VERSION "created by canmatrix"

NS_ :

BS_:

BU_: RadarFrontCenter VideoFrontCenter RadarFrontLeft RadarFrontRight ReceiveECU

BO_ 3221225472 VECTOR__INDEPENDENT_SIG_MSG: 0 Vector__XXX
 SG_ RFC_Status_CRC : 0|8@1+ (1,0) [0|255] "" Vector__XXX
 SG_ RFC_Status_AliveCtr : 0|4@1+ (1,0) [0|15] "" Vector__XXX
 SG_ RFC_Status_ModulationStatus : 0|2@1+ (1,0) [0|3] "" Vector__XXX
 SG_ RFC_Status_SensorStatus : 0|8@1+ (1,0) [0|255] "" Vector__XXX

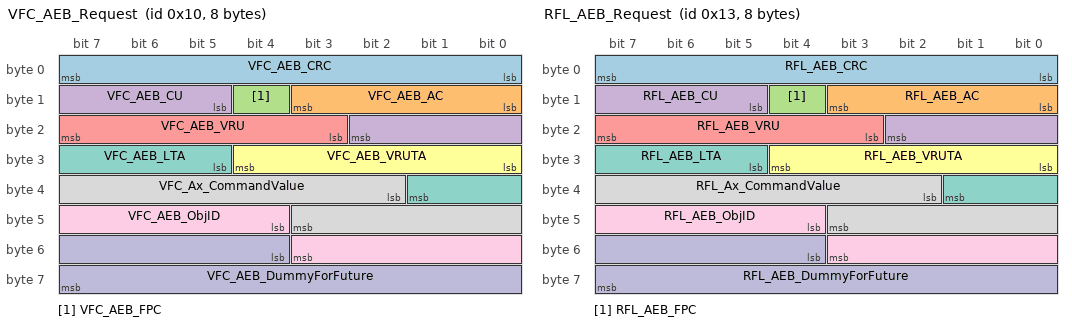
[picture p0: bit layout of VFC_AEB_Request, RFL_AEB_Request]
BO_ 16 VFC_AEB_Request: 8 VideoFrontCenter
 SG_ VFC_AEB_CRC : 0|8@1+ (1,0) [0|255] ""  RadarFrontCenter
 SG_ VFC_AEB_AC : 8|4@1+ (1,0) [0|15] ""  RadarFrontCenter
 SG_ VFC_AEB_FPC : 12|1@1+ (1,0) [0|1] ""  RadarFrontCenter
 SG_ VFC_AEB_CU : 13|6@1+ (1,0) [0|63] ""  RadarFrontCenter
 SG_ VFC_AEB_VRU : 19|5@1+ (1,0) [0|31] ""  RadarFrontCenter
 SG_ VFC_AEB_VRUTA : 24|5@1+ (1,0) [0|31] ""  RadarFrontCenter
 SG_ VFC_AEB_LTA : 29|5@1+ (1,0) [0|31] ""  RadarFrontCenter
 SG_ VFC_Ax_CommandValue : 34|10@1+ (0.024,-20.016) [-20.016|4.536] "m/s^2"  RadarFrontCenter
 SG_ VFC_AEB_ObjID : 44|8@1+ (1,0) [0|255] ""  RadarFrontCenter
 SG_ VFC_AEB_DummyForFuture : 52|12@1+ (1,0) [0|4095] ""  RadarFrontCenter

BO_ 19 RFL_AEB_Request: 8 RadarFrontLeft
 SG_ RFL_AEB_CRC : 0|8@1+ (1,0) [0|255] ""  RadarFrontCenter
 SG_ RFL_AEB_AC : 8|4@1+ (1,0) [0|15] ""  RadarFrontCenter
 SG_ RFL_AEB_FPC : 12|1@1+ (1,0) [0|1] ""  RadarFrontCenter
 SG_ RFL_AEB_CU : 13|6@1+ (1,0) [0|63] ""  RadarFrontCenter
 SG_ RFL_AEB_VRU : 19|5@1+ (1,0) [0|31] ""  RadarFrontCenter
 SG_ RFL_AEB_VRUTA : 24|5@1+ (1,0) [0|31] ""  RadarFrontCenter
 SG_ RFL_AEB_LTA : 29|5@1+ (1,0) [0|31] ""  RadarFrontCenter
 SG_ RFL_Ax_CommandValue : 34|10@1+ (0.024,-20.016) [-20.016|4.536] "m/s^2"  RadarFrontCenter
 SG_ RFL_AEB_ObjID : 44|8@1+ (1,0) [0|255] ""  RadarFrontCenter
 SG_ RFL_AEB_DummyForFuture : 52|12@1+ (1,0) [0|4095] ""  RadarFrontCenter

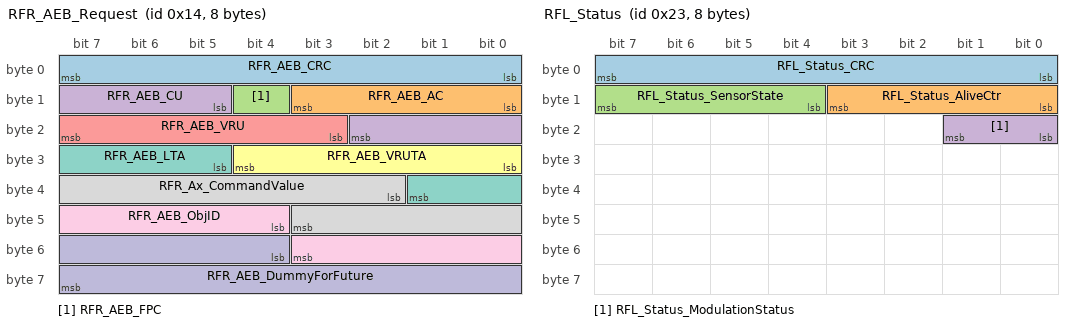
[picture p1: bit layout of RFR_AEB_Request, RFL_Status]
BO_ 20 RFR_AEB_Request: 8 RadarFrontRight
 SG_ RFR_AEB_CRC : 0|8@1+ (1,0) [0|255] ""  RadarFrontCenter
 SG_ RFR_AEB_AC : 8|4@1+ (1,0) [0|15] ""  RadarFrontCenter
 SG_ RFR_AEB_FPC : 12|1@1+ (1,0) [0|1] ""  RadarFrontCenter
 SG_ RFR_AEB_CU : 13|6@1+ (1,0) [0|63] ""  RadarFrontCenter
 SG_ RFR_AEB_VRU : 19|5@1+ (1,0) [0|31] ""  RadarFrontCenter
 SG_ RFR_AEB_VRUTA : 24|5@1+ (1,0) [0|31] ""  RadarFrontCenter
 SG_ RFR_AEB_LTA : 29|5@1+ (1,0) [0|31] ""  RadarFrontCenter
 SG_ RFR_Ax_CommandValue : 34|10@1+ (0.024,-20.016) [-20.016|4.536] "m/s^2"  RadarFrontCenter
 SG_ RFR_AEB_ObjID : 44|8@1+ (1,0) [0|255] ""  RadarFrontCenter
 SG_ RFR_AEB_DummyForFuture : 52|12@1+ (1,0) [0|4095] ""  RadarFrontCenter

BO_ 32 VFC_GlobalHdr: 32 VideoFrontCenter
 SG_ VFC_GlobalHdr_CRC : 0|16@1+ (1,0) [0|65535] ""  RadarFrontCenter,RadarFrontLeft,RadarFrontRight
 SG_ VFC_GlobalHdr_AliveCtr : 16|8@1+ (1,0) [0|255] ""  RadarFrontCenter,RadarFrontLeft,RadarFrontRight
 SG_ VFC_GlobalHdr_ProtocolVersion : 32|16@1+ (1,0) [0|65535] ""  RadarFrontCenter,RadarFrontLeft,RadarFrontRight
 SG_ VFC_GlobalHdr_TrafficFlowType : 48|1@1+ (1,0) [0|1] ""  RadarFrontCenter,RadarFrontLeft,RadarFrontRight
 SG_ VFC_GlobalHdr_TimeStampStatus : 56|8@1+ (1,0) [0|255] ""  RadarFrontCenter,RadarFrontLeft,RadarFrontRight
 SG_ VFC_GlobalHdr_TimeStamp : 64|26@1+ (1,0) [0|67108863] "ms"  RadarFrontCenter,RadarFrontLeft,RadarFrontRight
 SG_ VFC_GlobalHdr_SensorState : 96|4@1+ (1,0) [0|15] ""  RadarFrontCenter,RadarFrontLeft,RadarFrontRight
 SG_ VFC_GlobalHdr_DsmState : 100|4@1+ (1,0) [0|15] ""  RadarFrontCenter,RadarFrontLeft,RadarFrontRight
 SG_ VFC_GlobalHdr_CalibState : 104|3@1+ (1,0) [0|7] ""  RadarFrontCenter,RadarFrontLeft,RadarFrontRight
 SG_ VFC_GlobalHdr_StmState : 107|3@1+ (1,0) [0|7] ""  RadarFrontCenter,RadarFrontLeft,RadarFrontRight
 SG_ VFC_GlobalHdr_RollerBenchState : 110|2@1+ (1,0) [0|3] ""  RadarFrontCenter,RadarFrontLeft,RadarFrontRight
 SG_ VFC_GlobalHdr_MountPosX : 112|13@1+ (0.001,-4.096) [-4.096|4.095] "m"  RadarFrontCenter,RadarFrontLeft,RadarFrontRight
 SG_ VFC_GlobalHdr_MountPosY : 125|12@1+ (0.001,-2.048) [-2.048|2.047] "m"  RadarFrontCenter,RadarFrontLeft,RadarFrontRight
 SG_ VFC_GlobalHdr_MountPosZ : 137|13@1+ (0.001,0) [0|5] "m"  RadarFrontCenter,RadarFrontLeft,RadarFrontRight
 SG_ VFC_GlobalHdr_CalibYawAngle : 150|10@1+ (0.0005,-0.256) [-0.256|0.2555] "rad"  RadarFrontCenter,RadarFrontLeft,RadarFrontRight
 SG_ VFC_GlobalHdr_CalibPitchAngle : 160|10@1+ (0.0005,-0.256) [-0.256|0.2555] "rad"  RadarFrontCenter,RadarFrontLeft,RadarFrontRight
 SG_ VFC_GlobalHdr_CalibRollAngle : 170|10@1+ (0.0005,-0.256) [-0.256|0.2555] "rad"  RadarFrontCenter,RadarFrontLeft,RadarFrontRight
 SG_ VFC_GlobalHdr_SwVersion : 180|20@1+ (0.01,0) [0|9999.99] ""  RadarFrontCenter,RadarFrontLeft,RadarFrontRight
 SG_ VFC_GlobalHdr_FrameNumber : 200|16@1+ (1,0) [0|65535] ""  RadarFrontCenter,RadarFrontLeft,RadarFrontRight

BO_ 35 RFL_Status: 8 RadarFrontLeft
 SG_ RFL_Status_CRC : 0|8@1+ (1,0) [0|255] ""  RadarFrontCenter,VideoFrontCenter,RadarFrontRight
 SG_ RFL_Status_AliveCtr : 8|4@1+ (1,0) [0|15] ""  RadarFrontCenter,VideoFrontCenter,RadarFrontRight
 SG_ RFL_Status_SensorState : 12|4@1+ (1,0) [0|15] ""  RadarFrontCenter,VideoFrontCenter,RadarFrontRight
 SG_ RFL_Status_ModulationStatus : 16|2@1+ (1,0) [0|3] ""  RadarFrontCenter,VideoFrontCenter,RadarFrontRight

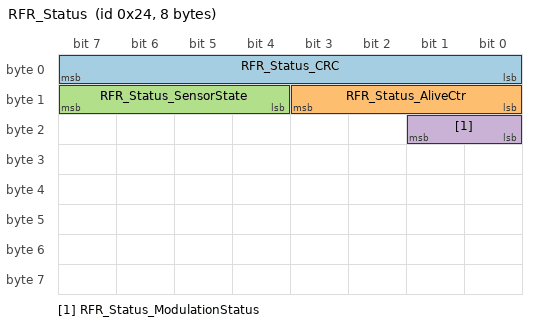
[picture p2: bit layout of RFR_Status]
BO_ 36 RFR_Status: 8 RadarFrontRight
 SG_ RFR_Status_CRC : 0|8@1+ (1,0) [0|255] ""  RadarFrontCenter,VideoFrontCenter,RadarFrontLeft
 SG_ RFR_Status_AliveCtr : 8|4@1+ (1,0) [0|15] ""  RadarFrontCenter,VideoFrontCenter,RadarFrontLeft
 SG_ RFR_Status_SensorState : 12|4@1+ (1,0) [0|15] ""  RadarFrontCenter,VideoFrontCenter,RadarFrontLeft
 SG_ RFR_Status_ModulationStatus : 16|2@1+ (1,0) [0|3] ""  RadarFrontCenter,VideoFrontCenter,RadarFrontLeft

BO_ 52 VFC_ObjectHdr: 32 VideoFrontCenter
 SG_ VFC_ObjHdr_CRC : 0|16@1+ (1,0) [0|65535] ""  RadarFrontCenter
 SG_ VFC_ObjHdr_AliveCtr : 16|8@1+ (1,0) [0|255] ""  RadarFrontCenter
 SG_ VFC_ObjHdr_ProtBlockCtr : 24|4@1+ (1,0) [0|15] ""  RadarFrontCenter
 SG_ VFC_ObjHdr_ProtObjCount : 28|6@1+ (1,0) [0|32] ""  RadarFrontCenter
 SG_ VFC_ObjHdr_State : 34|3@1+ (1,0) [0|7] ""  RadarFrontCenter
 SG_ VFC_ObjHdr_TimeStampStatus : 37|8@1+ (1,0) [0|255] ""  RadarFrontCenter
 SG_ VFC_ObjHdr_TimeStamp : 45|26@1+ (1,0) [0|67108863] "ms"  RadarFrontCenter
 SG_ VFC_ObjHdr_Principal_Point_U : 72|11@1+ (1,0) [0|2047] ""  RadarFrontCenter
 SG_ VFC_ObjHdr_Principal_Point_V : 88|10@1+ (1,0) [0|1023] ""  RadarFrontCenter
 SG_ VFC_ObjHdr_Focal_Length_X : 104|8@1+ (1,1572) [1572|1827] ""  RadarFrontCenter
 SG_ VFC_ObjHdr_Focal_Length_Y : 112|8@1+ (1,1572) [1572|1827] ""  RadarFrontCenter

BO_ 54 VFC_Object00A: 64 VideoFrontCenter
 SG_ VFC_Obj00A_CRC : 0|16@1+ (1,0) [0|65535] ""  RadarFrontCenter
 SG_ VFC_Obj00A_AliveCtr : 16|8@1+ (1,0) [0|255] ""  RadarFrontCenter
 SG_ VFC_Obj00A_ProtBlockCtr : 24|4@1+ (1,0) [0|15] ""  RadarFrontCenter
 SG_ VFC_Obj00A_ID : 32|8@1+ (1,0) [1|255] ""  RadarFrontCenter
 SG_ VFC_Obj00A_AxStdDev : 40|8@1+ (0.1,0) [0|25.5] "m/s^2"  RadarFrontCenter
 SG_ VFC_Obj00A_Dx : 48|12@1+ (0.05,0) [0|204.75] "m"  RadarFrontCenter
 SG_ VFC_Obj00A_Type : 60|4@1+ (1,0) [0|15] ""  RadarFrontCenter
 SG_ VFC_Obj00A_Dy : 64|14@1+ (0.01,-80) [-80|80] "m"  RadarFrontCenter
 SG_ VFC_Obj00A_Measured : 78|2@1+ (1,0) [0|3] ""  RadarFrontCenter
 SG_ VFC_Obj00A_Vx : 80|11@1+ (0.1,-154) [-154|50] "m/s"  RadarFrontCenter
 SG_ VFC_Obj00A_MeasSource : 91|5@1+ (1,0) [0|31] ""  RadarFrontCenter
 SG_ VFC_Obj00A_Vy : 96|10@1+ (0.1,-50) [-50|50] "m/s"  RadarFrontCenter
 SG_ VFC_Obj00A_DirIndicator : 106|3@1+ (1,0) [0|4] ""  RadarFrontCenter
 SG_ VFC_Obj00A_BrakeLight : 109|3@1+ (1,0) [0|7] ""  RadarFrontCenter
 SG_ VFC_Obj00A_Ax : 112|9@1+ (0.1,-16) [-16|16] "m/s^2"  RadarFrontCenter
 SG_ VFC_Obj00A_CompletelyInImg : 121|1@1+ (1,0) [0|1] ""  RadarFrontCenter
 SG_ VFC_Obj00A_ProbExist : 122|6@1+ (2,0) [0|100] "%"  RadarFrontCenter
 SG_ VFC_Obj00A_Ay : 128|8@1+ (0.1,-12) [-12|12] "m/s^2"  RadarFrontCenter
 SG_ VFC_Obj00A_AyStdDev : 136|8@1+ (0.1,0) [0|25.5] "m/s^2"  RadarFrontCenter
 SG_ VFC_Obj00A_DxStdDev : 144|10@1+ (0.05,0) [0|51.15] "m"  RadarFrontCenter
 SG_ VFC_Obj00A_ProbMovingLat : 154|6@1+ (2,0) [0|100] "%"  RadarFrontCenter
 SG_ VFC_Obj00A_DyStdDev : 160|10@1+ (0.02,0) [0|20.46] "m"  RadarFrontCenter
 SG_ VFC_Obj00A_ProbMovingLong : 170|6@1+ (2,0) [0|100] "%"  RadarFrontCenter
 SG_ VFC_Obj00A_VxStdDev : 176|10@1+ (0.1,0) [0|102.3] "m/s"  RadarFrontCenter
 SG_ VFC_Obj00A_HeadingAngleStdDev : 186|6@1+ (0.01,0) [0|0.5] "rad"  RadarFrontCenter
 SG_ VFC_Obj00A_VyStdDev : 192|9@1+ (0.1,0) [0|51.1] "m/s"  RadarFrontCenter
 SG_ VFC_Obj00A_HeightStdDev : 201|7@1+ (0.01,0) [0|1] "m"  RadarFrontCenter
 SG_ VFC_Obj00A_Height : 208|9@1+ (0.01,0) [0|5.11] "m"  RadarFrontCenter
 SG_ VFC_Obj00A_Length : 217|9@1+ (0.05,0) [0|25.55] "m"  RadarFrontCenter
 SG_ VFC_Obj00A_HeadingAngle : 226|9@1+ (0.01,-1.57) [-1.57|1.57] "rad"  RadarFrontCenter
 SG_ VFC_Obj00A_NormAx : 235|13@1+ (0.002,-10) [-10|6] "1/s^2"  RadarFrontCenter
 SG_ VFC_Obj00A_NormVyEdgeLeftStdDev : 248|8@1+ (0.001,0) [0|0.255] "1/s"  RadarFrontCenter
 SG_ VFC_Obj00A_NormVyEdgeLeft : 256|13@1+ (0.001,-4) [-4|4] "1/s"  RadarFrontCenter
 SG_ VFC_Obj00A_EdgeBottom : 269|12@1+ (0.00025,-0.5) [-0.5|0.5] "unitless"  RadarFrontCenter
 SG_ VFC_Obj00A_NormVyEdgeRight : 281|13@1+ (0.001,-4) [-4|4] "1/s"  RadarFrontCenter
 SG_ VFC_Obj00A_Width : 294|10@1+ (0.01,0) [0|10.23] "m"  RadarFrontCenter
 SG_ VFC_Obj00A_NormVx : 304|16@1+ (0.001,-40) [-40|25] "1/s"  RadarFrontCenter
 SG_ VFC_Obj00A_NormVyEdgeRightStdDev : 320|8@1+ (0.001,0) [0|0.255] "1/s"  RadarFrontCenter
 SG_ VFC_Obj00A_NormAxStdDev : 328|10@1+ (0.0025,0) [0|2.5575] "1/s^2"  RadarFrontCenter
 SG_ VFC_Obj00A_ScaleChange : 338|14@1+ (0.0001,0.5) [0.5|2.1383] "unitless"  RadarFrontCenter
 SG_ VFC_Obj00A_ScaleChngStdDev : 352|10@1+ (0.0001,0) [0|0.1023] "unitless"  RadarFrontCenter
 SG_ VFC_Obj00A_Reliability : 362|6@1+ (1,0) [0|63] ""  RadarFrontCenter
 SG_ VFC_Obj00A_NormVxStdDev : 368|10@1+ (0.001,0) [0|1.023] "1/s"  RadarFrontCenter
 SG_ VFC_Obj00A_TypeProb : 378|6@1+ (2,0) [0|100] "%"  RadarFrontCenter
 SG_ VFC_Obj00A_LengthStdDev : 384|7@1+ (0.05,0) [0|5] "m"  RadarFrontCenter
 SG_ VFC_Obj00A_WidthStdDev : 391|7@1+ (0.01,0) [0|1] "m"  RadarFrontCenter
 SG_ VFC_Obj00A_EdgeMid : 398|13@1+ (0.00025,-1) [-1|1] "unitless"  RadarFrontCenter
 SG_ VFC_Obj00A_EdgeLeft : 411|13@1+ (0.00025,-1) [-1|1] "unitless"  RadarFrontCenter
 SG_ VFC_Obj00A_EdgeRight : 424|13@1+ (0.00025,-1) [-1|1] "unitless"  RadarFrontCenter
 SG_ VFC_Obj00A_VisibleView : 437|3@1+ (1,0) [0|4] ""  RadarFrontCenter
 SG_ VFC_Obj00A_EdgeLeftStdDev : 440|8@1+ (0.0002,0) [0|0.051] "unitless"  RadarFrontCenter
 SG_ VFC_Obj00A_EdgeTop : 448|12@1+ (0.00025,-0.5) [-0.5|0.5] "unitless"  RadarFrontCenter
 SG_ VFC_Obj00A_HeadOrientation : 460|4@1+ (1,0) [0|15] ""  RadarFrontCenter
 SG_ VFC_Obj00A_EdgeMidStdDev : 464|8@1+ (0.0002,0) [0|0.051] "unitless"  RadarFrontCenter
 SG_ VFC_Obj00A_EdgeRightStdDev : 472|8@1+ (0.0002,0) [0|0.051] "unitless"  RadarFrontCenter
 SG_ VFC_Obj00A_EdgeTopStdDev : 480|8@1+ (0.0002,0) [0|0.051] "unitless"  RadarFrontCenter
 SG_ VFC_Obj00A_EdgeBottomStdDev : 488|8@1+ (0.0002,0) [0|0.051] "unitless"  RadarFrontCenter
 SG_ VFC_Obj00A_ClassifiedView : 496|3@1+ (1,0) [0|4] ""  RadarFrontCenter

BO_ 55 VFC_Object01A: 64 VideoFrontCenter
 SG_ VFC_Obj01A_CRC : 0|16@1+ (1,0) [0|65535] ""  RadarFrontCenter
 SG_ VFC_Obj01A_AliveCtr : 16|8@1+ (1,0) [0|255] ""  RadarFrontCenter
 SG_ VFC_Obj01A_ProtBlockCtr : 24|4@1+ (1,0) [0|15] ""  RadarFrontCenter
 SG_ VFC_Obj01A_ID : 32|8@1+ (1,0) [1|255] ""  RadarFrontCenter
 SG_ VFC_Obj01A_AxStdDev : 40|8@1+ (0.1,0) [0|25.5] "m/s^2"  RadarFrontCenter
 SG_ VFC_Obj01A_Dx : 48|12@1+ (0.05,0) [0|204.75] "m"  RadarFrontCenter
 SG_ VFC_Obj01A_Type : 60|4@1+ (1,0) [0|15] ""  RadarFrontCenter
 SG_ VFC_Obj01A_Dy : 64|14@1+ (0.01,-80) [-80|80] "m"  RadarFrontCenter
 SG_ VFC_Obj01A_Measured : 78|2@1+ (1,0) [0|3] ""  RadarFrontCenter
 SG_ VFC_Obj01A_Vx : 80|11@1+ (0.1,-154) [-154|50] "m/s"  RadarFrontCenter
 SG_ VFC_Obj01A_MeasSource : 91|5@1+ (1,0) [0|31] ""  RadarFrontCenter
 SG_ VFC_Obj01A_Vy : 96|10@1+ (0.1,-50) [-50|50] "m/s"  RadarFrontCenter
 SG_ VFC_Obj01A_DirIndicator : 106|3@1+ (1,0) [0|4] ""  RadarFrontCenter
 SG_ VFC_Obj01A_BrakeLight : 109|3@1+ (1,0) [0|7] ""  RadarFrontCenter
 SG_ VFC_Obj01A_Ax : 112|9@1+ (0.1,-16) [-16|16] "m/s^2"  RadarFrontCenter
 SG_ VFC_Obj01A_CompletelyInImg : 121|1@1+ (1,0) [0|1] ""  RadarFrontCenter
 SG_ VFC_Obj01A_ProbExist : 122|6@1+ (2,0) [0|100] "%"  RadarFrontCenter
 SG_ VFC_Obj01A_Ay : 128|8@1+ (0.1,-12) [-12|12] "m/s^2"  RadarFrontCenter
 SG_ VFC_Obj01A_AyStdDev : 136|8@1+ (0.1,0) [0|25.5] "m/s^2"  RadarFrontCenter
 SG_ VFC_Obj01A_DxStdDev : 144|10@1+ (0.05,0) [0|51.15] "m"  RadarFrontCenter
 SG_ VFC_Obj01A_ProbMovingLat : 154|6@1+ (2,0) [0|100] "%"  RadarFrontCenter
 SG_ VFC_Obj01A_DyStdDev : 160|10@1+ (0.02,0) [0|20.46] "m"  RadarFrontCenter
 SG_ VFC_Obj01A_ProbMovingLong : 170|6@1+ (2,0) [0|100] "%"  RadarFrontCenter
 SG_ VFC_Obj01A_VxStdDev : 176|10@1+ (0.1,0) [0|102.3] "m/s"  RadarFrontCenter
 SG_ VFC_Obj01A_HeadingAngleStdDev : 186|6@1+ (0.01,0) [0|0.5] "rad"  RadarFrontCenter
 SG_ VFC_Obj01A_VyStdDev : 192|9@1+ (0.1,0) [0|51.1] "m/s"  RadarFrontCenter
 SG_ VFC_Obj01A_HeightStdDev : 201|7@1+ (0.01,0) [0|1] "m"  RadarFrontCenter
 SG_ VFC_Obj01A_Height : 208|9@1+ (0.01,0) [0|5.11] "m"  RadarFrontCenter
 SG_ VFC_Obj01A_Length : 217|9@1+ (0.05,0) [0|25.55] "m"  RadarFrontCenter
 SG_ VFC_Obj01A_HeadingAngle : 226|9@1+ (0.01,-1.57) [-1.57|1.57] "rad"  RadarFrontCenter
 SG_ VFC_Obj01A_NormAx : 235|13@1+ (0.002,-10) [-10|6] "1/s^2"  RadarFrontCenter
 SG_ VFC_Obj01A_NormVyEdgeLeftStdDev : 248|8@1+ (0.001,0) [0|0.255] "1/s"  RadarFrontCenter
 SG_ VFC_Obj01A_NormVyEdgeLeft : 256|13@1+ (0.001,-4) [-4|4] "1/s"  RadarFrontCenter
 SG_ VFC_Obj01A_EdgeBottom : 269|12@1+ (0.00025,-0.5) [-0.5|0.5] "unitless"  RadarFrontCenter
 SG_ VFC_Obj01A_NormVyEdgeRight : 281|13@1+ (0.001,-4) [-4|4] "1/s"  RadarFrontCenter
 SG_ VFC_Obj01A_Width : 294|10@1+ (0.01,0) [0|10.23] "m"  RadarFrontCenter
 SG_ VFC_Obj01A_NormVx : 304|16@1+ (0.001,-40) [-40|25] "1/s"  RadarFrontCenter
 SG_ VFC_Obj01A_NormVyEdgeRightStdDev : 320|8@1+ (0.001,0) [0|0.255] "1/s"  RadarFrontCenter
 SG_ VFC_Obj01A_NormAxStdDev : 328|10@1+ (0.0025,0) [0|2.5575] "1/s^2"  RadarFrontCenter
 SG_ VFC_Obj01A_ScaleChange : 338|14@1+ (0.0001,0.5) [0.5|2.1383] "unitless"  RadarFrontCenter
 SG_ VFC_Obj01A_ScaleChngStdDev : 352|10@1+ (0.0001,0) [0|0.1023] "unitless"  RadarFrontCenter
 SG_ VFC_Obj01A_Reliability : 362|6@1+ (1,0) [0|63] ""  RadarFrontCenter
 SG_ VFC_Obj01A_NormVxStdDev : 368|10@1+ (0.001,0) [0|1.023] "1/s"  RadarFrontCenter
 SG_ VFC_Obj01A_TypeProb : 378|6@1+ (2,0) [0|100] "%"  RadarFrontCenter
 SG_ VFC_Obj01A_LengthStdDev : 384|7@1+ (0.05,0) [0|5] "m"  RadarFrontCenter
 SG_ VFC_Obj01A_WidthStdDev : 391|7@1+ (0.01,0) [0|1] "m"  RadarFrontCenter
 SG_ VFC_Obj01A_EdgeMid : 398|13@1+ (0.00025,-1) [-1|1] "unitless"  RadarFrontCenter
 SG_ VFC_Obj01A_EdgeLeft : 411|13@1+ (0.00025,-1) [-1|1] "unitless"  RadarFrontCenter
 SG_ VFC_Obj01A_EdgeRight : 424|13@1+ (0.00025,-1) [-1|1] "unitless"  RadarFrontCenter
 SG_ VFC_Obj01A_VisibleView : 437|3@1+ (1,0) [0|4] ""  RadarFrontCenter
 SG_ VFC_Obj01A_EdgeLeftStdDev : 440|8@1+ (0.0002,0) [0|0.051] "unitless"  RadarFrontCenter
 SG_ VFC_Obj01A_EdgeTop : 448|12@1+ (0.00025,-0.5) [-0.5|0.5] "unitless"  RadarFrontCenter
 SG_ VFC_Obj01A_HeadOrientation : 460|4@1+ (1,0) [0|15] ""  RadarFrontCenter
 SG_ VFC_Obj01A_EdgeMidStdDev : 464|8@1+ (0.0002,0) [0|0.051] "unitless"  RadarFrontCenter
 SG_ VFC_Obj01A_EdgeRightStdDev : 472|8@1+ (0.0002,0) [0|0.051] "unitless"  RadarFrontCenter
 SG_ VFC_Obj01A_EdgeTopStdDev : 480|8@1+ (0.0002,0) [0|0.051] "unitless"  RadarFrontCenter
 SG_ VFC_Obj01A_EdgeBottomStdDev : 488|8@1+ (0.0002,0) [0|0.051] "unitless"  RadarFrontCenter
 SG_ VFC_Obj01A_ClassifiedView : 496|3@1+ (1,0) [0|4] ""  RadarFrontCenter

BO_ 56 VFC_Object02A: 64 VideoFrontCenter
 SG_ VFC_Obj02A_CRC : 0|16@1+ (1,0) [0|65535] ""  RadarFrontCenter
 SG_ VFC_Obj02A_AliveCtr : 16|8@1+ (1,0) [0|255] ""  RadarFrontCenter
 SG_ VFC_Obj02A_ProtBlockCtr : 24|4@1+ (1,0) [0|15] ""  RadarFrontCenter
 SG_ VFC_Obj02A_ID : 32|8@1+ (1,0) [1|255] ""  RadarFrontCenter
 SG_ VFC_Obj02A_AxStdDev : 40|8@1+ (0.1,0) [0|25.5] "m/s^2"  RadarFrontCenter
 SG_ VFC_Obj02A_Dx : 48|12@1+ (0.05,0) [0|204.75] "m"  RadarFrontCenter
 SG_ VFC_Obj02A_Type : 60|4@1+ (1,0) [0|15] ""  RadarFrontCenter
 SG_ VFC_Obj02A_Dy : 64|14@1+ (0.01,-80) [-80|80] "m"  RadarFrontCenter
 SG_ VFC_Obj02A_Measured : 78|2@1+ (1,0) [0|3] ""  RadarFrontCenter
 SG_ VFC_Obj02A_Vx : 80|11@1+ (0.1,-154) [-154|50] "m/s"  RadarFrontCenter
 SG_ VFC_Obj02A_MeasSource : 91|5@1+ (1,0) [0|31] ""  RadarFrontCenter
 SG_ VFC_Obj02A_Vy : 96|10@1+ (0.1,-50) [-50|50] "m/s"  RadarFrontCenter
 SG_ VFC_Obj02A_DirIndicator : 106|3@1+ (1,0) [0|4] ""  RadarFrontCenter
 SG_ VFC_Obj02A_BrakeLight : 109|3@1+ (1,0) [0|7] ""  RadarFrontCenter
 SG_ VFC_Obj02A_Ax : 112|9@1+ (0.1,-16) [-16|16] "m/s^2"  RadarFrontCenter
 SG_ VFC_Obj02A_CompletelyInImg : 121|1@1+ (1,0) [0|1] ""  RadarFrontCenter
 SG_ VFC_Obj02A_ProbExist : 122|6@1+ (2,0) [0|100] "%"  RadarFrontCenter
 SG_ VFC_Obj02A_Ay : 128|8@1+ (0.1,-12) [-12|12] "m/s^2"  RadarFrontCenter
 SG_ VFC_Obj02A_AyStdDev : 136|8@1+ (0.1,0) [0|25.5] "m/s^2"  RadarFrontCenter
 SG_ VFC_Obj02A_DxStdDev : 144|10@1+ (0.05,0) [0|51.15] "m"  RadarFrontCenter
 SG_ VFC_Obj02A_ProbMovingLat : 154|6@1+ (2,0) [0|100] "%"  RadarFrontCenter
 SG_ VFC_Obj02A_DyStdDev : 160|10@1+ (0.02,0) [0|20.46] "m"  RadarFrontCenter
 SG_ VFC_Obj02A_ProbMovingLong : 170|6@1+ (2,0) [0|100] "%"  RadarFrontCenter
 SG_ VFC_Obj02A_VxStdDev : 176|10@1+ (0.1,0) [0|102.3] "m/s"  RadarFrontCenter
 SG_ VFC_Obj02A_HeadingAngleStdDev : 186|6@1+ (0.01,0) [0|0.5] "rad"  RadarFrontCenter
 SG_ VFC_Obj02A_VyStdDev : 192|9@1+ (0.1,0) [0|51.1] "m/s"  RadarFrontCenter
 SG_ VFC_Obj02A_HeightStdDev : 201|7@1+ (0.01,0) [0|1] "m"  RadarFrontCenter
 SG_ VFC_Obj02A_Height : 208|9@1+ (0.01,0) [0|5.11] "m"  RadarFrontCenter
 SG_ VFC_Obj02A_Length : 217|9@1+ (0.05,0) [0|25.55] "m"  RadarFrontCenter
 SG_ VFC_Obj02A_HeadingAngle : 226|9@1+ (0.01,-1.57) [-1.57|1.57] "rad"  RadarFrontCenter
 SG_ VFC_Obj02A_NormAx : 235|13@1+ (0.002,-10) [-10|6] "1/s^2"  RadarFrontCenter
 SG_ VFC_Obj02A_NormVyEdgeLeftStdDev : 248|8@1+ (0.001,0) [0|0.255] "1/s"  RadarFrontCenter
 SG_ VFC_Obj02A_NormVyEdgeLeft : 256|13@1+ (0.001,-4) [-4|4] "1/s"  RadarFrontCenter
 SG_ VFC_Obj02A_EdgeBottom : 269|12@1+ (0.00025,-0.5) [-0.5|0.5] "unitless"  RadarFrontCenter
 SG_ VFC_Obj02A_NormVyEdgeRight : 281|13@1+ (0.001,-4) [-4|4] "1/s"  RadarFrontCenter
 SG_ VFC_Obj02A_Width : 294|10@1+ (0.01,0) [0|10.23] "m"  RadarFrontCenter
 SG_ VFC_Obj02A_NormVx : 304|16@1+ (0.001,-40) [-40|25] "1/s"  RadarFrontCenter
 SG_ VFC_Obj02A_NormVyEdgeRightStdDev : 320|8@1+ (0.001,0) [0|0.255] "1/s"  RadarFrontCenter
 SG_ VFC_Obj02A_NormAxStdDev : 328|10@1+ (0.0025,0) [0|2.5575] "1/s^2"  RadarFrontCenter
 SG_ VFC_Obj02A_ScaleChange : 338|14@1+ (0.0001,0.5) [0.5|2.1383] "unitless"  RadarFrontCenter
 SG_ VFC_Obj02A_ScaleChngStdDev : 352|10@1+ (0.0001,0) [0|0.1023] "unitless"  RadarFrontCenter
 SG_ VFC_Obj02A_Reliability : 362|6@1+ (1,0) [0|63] ""  RadarFrontCenter
 SG_ VFC_Obj02A_NormVxStdDev : 368|10@1+ (0.001,0) [0|1.023] "1/s"  RadarFrontCenter
 SG_ VFC_Obj02A_TypeProb : 378|6@1+ (2,0) [0|100] "%"  RadarFrontCenter
 SG_ VFC_Obj02A_LengthStdDev : 384|7@1+ (0.05,0) [0|5] "m"  RadarFrontCenter
 SG_ VFC_Obj02A_WidthStdDev : 391|7@1+ (0.01,0) [0|1] "m"  RadarFrontCenter
 SG_ VFC_Obj02A_EdgeMid : 398|13@1+ (0.00025,-1) [-1|1] "unitless"  RadarFrontCenter
 SG_ VFC_Obj02A_EdgeLeft : 411|13@1+ (0.00025,-1) [-1|1] "unitless"  RadarFrontCenter
 SG_ VFC_Obj02A_EdgeRight : 424|13@1+ (0.00025,-1) [-1|1] "unitless"  RadarFrontCenter
 SG_ VFC_Obj02A_VisibleView : 437|3@1+ (1,0) [0|4] ""  RadarFrontCenter
 SG_ VFC_Obj02A_EdgeLeftStdDev : 440|8@1+ (0.0002,0) [0|0.051] "unitless"  RadarFrontCenter
 SG_ VFC_Obj02A_EdgeTop : 448|12@1+ (0.00025,-0.5) [-0.5|0.5] "unitless"  RadarFrontCenter
 SG_ VFC_Obj02A_HeadOrientation : 460|4@1+ (1,0) [0|15] ""  RadarFrontCenter
 SG_ VFC_Obj02A_EdgeMidStdDev : 464|8@1+ (0.0002,0) [0|0.051] "unitless"  RadarFrontCenter
 SG_ VFC_Obj02A_EdgeRightStdDev : 472|8@1+ (0.0002,0) [0|0.051] "unitless"  RadarFrontCenter
 SG_ VFC_Obj02A_EdgeTopStdDev : 480|8@1+ (0.0002,0) [0|0.051] "unitless"  RadarFrontCenter
 SG_ VFC_Obj02A_EdgeBottomStdDev : 488|8@1+ (0.0002,0) [0|0.051] "unitless"  RadarFrontCenter
 SG_ VFC_Obj02A_ClassifiedView : 496|3@1+ (1,0) [0|4] ""  RadarFrontCenter

BO_ 57 VFC_Object03A: 64 VideoFrontCenter
 SG_ VFC_Obj03A_CRC : 0|16@1+ (1,0) [0|65535] ""  RadarFrontCenter
 SG_ VFC_Obj03A_AliveCtr : 16|8@1+ (1,0) [0|255] ""  RadarFrontCenter
 SG_ VFC_Obj03A_ProtBlockCtr : 24|4@1+ (1,0) [0|15] ""  RadarFrontCenter
 SG_ VFC_Obj03A_ID : 32|8@1+ (1,0) [1|255] ""  RadarFrontCenter
 SG_ VFC_Obj03A_AxStdDev : 40|8@1+ (0.1,0) [0|25.5] "m/s^2"  RadarFrontCenter
 SG_ VFC_Obj03A_Dx : 48|12@1+ (0.05,0) [0|204.75] "m"  RadarFrontCenter
 SG_ VFC_Obj03A_Type : 60|4@1+ (1,0) [0|15] ""  RadarFrontCenter
 SG_ VFC_Obj03A_Dy : 64|14@1+ (0.01,-80) [-80|80] "m"  RadarFrontCenter
 SG_ VFC_Obj03A_Measured : 78|2@1+ (1,0) [0|3] ""  RadarFrontCenter
 SG_ VFC_Obj03A_Vx : 80|11@1+ (0.1,-154) [-154|50] "m/s"  RadarFrontCenter
 SG_ VFC_Obj03A_MeasSource : 91|5@1+ (1,0) [0|31] ""  RadarFrontCenter
 SG_ VFC_Obj03A_Vy : 96|10@1+ (0.1,-50) [-50|50] "m/s"  RadarFrontCenter
 SG_ VFC_Obj03A_DirIndicator : 106|3@1+ (1,0) [0|4] ""  RadarFrontCenter
 SG_ VFC_Obj03A_BrakeLight : 109|3@1+ (1,0) [0|7] ""  RadarFrontCenter
 SG_ VFC_Obj03A_Ax : 112|9@1+ (0.1,-16) [-16|16] "m/s^2"  RadarFrontCenter
 SG_ VFC_Obj03A_CompletelyInImg : 121|1@1+ (1,0) [0|1] ""  RadarFrontCenter
 SG_ VFC_Obj03A_ProbExist : 122|6@1+ (2,0) [0|100] "%"  RadarFrontCenter
 SG_ VFC_Obj03A_Ay : 128|8@1+ (0.1,-12) [-12|12] "m/s^2"  RadarFrontCenter
 SG_ VFC_Obj03A_AyStdDev : 136|8@1+ (0.1,0) [0|25.5] "m/s^2"  RadarFrontCenter
 SG_ VFC_Obj03A_DxStdDev : 144|10@1+ (0.05,0) [0|51.15] "m"  RadarFrontCenter
 SG_ VFC_Obj03A_ProbMovingLat : 154|6@1+ (2,0) [0|100] "%"  RadarFrontCenter
 SG_ VFC_Obj03A_DyStdDev : 160|10@1+ (0.02,0) [0|20.46] "m"  RadarFrontCenter
 SG_ VFC_Obj03A_ProbMovingLong : 170|6@1+ (2,0) [0|100] "%"  RadarFrontCenter
 SG_ VFC_Obj03A_VxStdDev : 176|10@1+ (0.1,0) [0|102.3] "m/s"  RadarFrontCenter
 SG_ VFC_Obj03A_HeadingAngleStdDev : 186|6@1+ (0.01,0) [0|0.5] "rad"  RadarFrontCenter
 SG_ VFC_Obj03A_VyStdDev : 192|9@1+ (0.1,0) [0|51.1] "m/s"  RadarFrontCenter
 SG_ VFC_Obj03A_HeightStdDev : 201|7@1+ (0.01,0) [0|1] "m"  RadarFrontCenter
 SG_ VFC_Obj03A_Height : 208|9@1+ (0.01,0) [0|5.11] "m"  RadarFrontCenter
 SG_ VFC_Obj03A_Length : 217|9@1+ (0.05,0) [0|25.55] "m"  RadarFrontCenter
 SG_ VFC_Obj03A_HeadingAngle : 226|9@1+ (0.01,-1.57) [-1.57|1.57] "rad"  RadarFrontCenter
 SG_ VFC_Obj03A_NormAx : 235|13@1+ (0.002,-10) [-10|6] "1/s^2"  RadarFrontCenter
 SG_ VFC_Obj03A_NormVyEdgeLeftStdDev : 248|8@1+ (0.001,0) [0|0.255] "1/s"  RadarFrontCenter
 SG_ VFC_Obj03A_NormVyEdgeLeft : 256|13@1+ (0.001,-4) [-4|4] "1/s"  RadarFrontCenter
 SG_ VFC_Obj03A_EdgeBottom : 269|12@1+ (0.00025,-0.5) [-0.5|0.5] "unitless"  RadarFrontCenter
 SG_ VFC_Obj03A_NormVyEdgeRight : 281|13@1+ (0.001,-4) [-4|4] "1/s"  RadarFrontCenter
 SG_ VFC_Obj03A_Width : 294|10@1+ (0.01,0) [0|10.23] "m"  RadarFrontCenter
 SG_ VFC_Obj03A_NormVx : 304|16@1+ (0.001,-40) [-40|25] "1/s"  RadarFrontCenter
 SG_ VFC_Obj03A_NormVyEdgeRightStdDev : 320|8@1+ (0.001,0) [0|0.255] "1/s"  RadarFrontCenter
 SG_ VFC_Obj03A_NormAxStdDev : 328|10@1+ (0.0025,0) [0|2.5575] "1/s^2"  RadarFrontCenter
 SG_ VFC_Obj03A_ScaleChange : 338|14@1+ (0.0001,0.5) [0.5|2.1383] "unitless"  RadarFrontCenter
 SG_ VFC_Obj03A_ScaleChngStdDev : 352|10@1+ (0.0001,0) [0|0.1023] "unitless"  RadarFrontCenter
 SG_ VFC_Obj03A_Reliability : 362|6@1+ (1,0) [0|63] ""  RadarFrontCenter
 SG_ VFC_Obj03A_NormVxStdDev : 368|10@1+ (0.001,0) [0|1.023] "1/s"  RadarFrontCenter
 SG_ VFC_Obj03A_TypeProb : 378|6@1+ (2,0) [0|100] "%"  RadarFrontCenter
 SG_ VFC_Obj03A_LengthStdDev : 384|7@1+ (0.05,0) [0|5] "m"  RadarFrontCenter
 SG_ VFC_Obj03A_WidthStdDev : 391|7@1+ (0.01,0) [0|1] "m"  RadarFrontCenter
 SG_ VFC_Obj03A_EdgeMid : 398|13@1+ (0.00025,-1) [-1|1] "unitless"  RadarFrontCenter
 SG_ VFC_Obj03A_EdgeLeft : 411|13@1+ (0.00025,-1) [-1|1] "unitless"  RadarFrontCenter
 SG_ VFC_Obj03A_EdgeRight : 424|13@1+ (0.00025,-1) [-1|1] "unitless"  RadarFrontCenter
 SG_ VFC_Obj03A_VisibleView : 437|3@1+ (1,0) [0|4] ""  RadarFrontCenter
 SG_ VFC_Obj03A_EdgeLeftStdDev : 440|8@1+ (0.0002,0) [0|0.051] "unitless"  RadarFrontCenter
 SG_ VFC_Obj03A_EdgeTop : 448|12@1+ (0.00025,-0.5) [-0.5|0.5] "unitless"  RadarFrontCenter
 SG_ VFC_Obj03A_HeadOrientation : 460|4@1+ (1,0) [0|15] ""  RadarFrontCenter
 SG_ VFC_Obj03A_EdgeMidStdDev : 464|8@1+ (0.0002,0) [0|0.051] "unitless"  RadarFrontCenter
 SG_ VFC_Obj03A_EdgeRightStdDev : 472|8@1+ (0.0002,0) [0|0.051] "unitless"  RadarFrontCenter
 SG_ VFC_Obj03A_EdgeTopStdDev : 480|8@1+ (0.0002,0) [0|0.051] "unitless"  RadarFrontCenter
 SG_ VFC_Obj03A_EdgeBottomStdDev : 488|8@1+ (0.0002,0) [0|0.051] "unitless"  RadarFrontCenter
 SG_ VFC_Obj03A_ClassifiedView : 496|3@1+ (1,0) [0|4] ""  RadarFrontCenter

BO_ 58 VFC_Object04A: 64 VideoFrontCenter
 SG_ VFC_Obj04A_CRC : 0|16@1+ (1,0) [0|65535] ""  RadarFrontCenter
 SG_ VFC_Obj04A_AliveCtr : 16|8@1+ (1,0) [0|255] ""  RadarFrontCenter
 SG_ VFC_Obj04A_ProtBlockCtr : 24|4@1+ (1,0) [0|15] ""  RadarFrontCenter
 SG_ VFC_Obj04A_ID : 32|8@1+ (1,0) [1|255] ""  RadarFrontCenter
 SG_ VFC_Obj04A_AxStdDev : 40|8@1+ (0.1,0) [0|25.5] "m/s^2"  RadarFrontCenter
 SG_ VFC_Obj04A_Dx : 48|12@1+ (0.05,0) [0|204.75] "m"  RadarFrontCenter
 SG_ VFC_Obj04A_Type : 60|4@1+ (1,0) [0|15] ""  RadarFrontCenter
 SG_ VFC_Obj04A_Dy : 64|14@1+ (0.01,-80) [-80|80] "m"  RadarFrontCenter
 SG_ VFC_Obj04A_Measured : 78|2@1+ (1,0) [0|3] ""  RadarFrontCenter
 SG_ VFC_Obj04A_Vx : 80|11@1+ (0.1,-154) [-154|50] "m/s"  RadarFrontCenter
 SG_ VFC_Obj04A_MeasSource : 91|5@1+ (1,0) [0|31] ""  RadarFrontCenter
 SG_ VFC_Obj04A_Vy : 96|10@1+ (0.1,-50) [-50|50] "m/s"  RadarFrontCenter
 SG_ VFC_Obj04A_DirIndicator : 106|3@1+ (1,0) [0|4] ""  RadarFrontCenter
 SG_ VFC_Obj04A_BrakeLight : 109|3@1+ (1,0) [0|7] ""  RadarFrontCenter
 SG_ VFC_Obj04A_Ax : 112|9@1+ (0.1,-16) [-16|16] "m/s^2"  RadarFrontCenter
 SG_ VFC_Obj04A_CompletelyInImg : 121|1@1+ (1,0) [0|1] ""  RadarFrontCenter
 SG_ VFC_Obj04A_ProbExist : 122|6@1+ (2,0) [0|100] "%"  RadarFrontCenter
 SG_ VFC_Obj04A_Ay : 128|8@1+ (0.1,-12) [-12|12] "m/s^2"  RadarFrontCenter
 SG_ VFC_Obj04A_AyStdDev : 136|8@1+ (0.1,0) [0|25.5] "m/s^2"  RadarFrontCenter
 SG_ VFC_Obj04A_DxStdDev : 144|10@1+ (0.05,0) [0|51.15] "m"  RadarFrontCenter
 SG_ VFC_Obj04A_ProbMovingLat : 154|6@1+ (2,0) [0|100] "%"  RadarFrontCenter
 SG_ VFC_Obj04A_DyStdDev : 160|10@1+ (0.02,0) [0|20.46] "m"  RadarFrontCenter
 SG_ VFC_Obj04A_ProbMovingLong : 170|6@1+ (2,0) [0|100] "%"  RadarFrontCenter
 SG_ VFC_Obj04A_VxStdDev : 176|10@1+ (0.1,0) [0|102.3] "m/s"  RadarFrontCenter
 SG_ VFC_Obj04A_HeadingAngleStdDev : 186|6@1+ (0.01,0) [0|0.5] "rad"  RadarFrontCenter
 SG_ VFC_Obj04A_VyStdDev : 192|9@1+ (0.1,0) [0|51.1] "m/s"  RadarFrontCenter
 SG_ VFC_Obj04A_HeightStdDev : 201|7@1+ (0.01,0) [0|1] "m"  RadarFrontCenter
 SG_ VFC_Obj04A_Height : 208|9@1+ (0.01,0) [0|5.11] "m"  RadarFrontCenter
 SG_ VFC_Obj04A_Length : 217|9@1+ (0.05,0) [0|25.55] "m"  RadarFrontCenter
 SG_ VFC_Obj04A_HeadingAngle : 226|9@1+ (0.01,-1.57) [-1.57|1.57] "rad"  RadarFrontCenter
 SG_ VFC_Obj04A_NormAx : 235|13@1+ (0.002,-10) [-10|6] "1/s^2"  RadarFrontCenter
 SG_ VFC_Obj04A_NormVyEdgeLeftStdDev : 248|8@1+ (0.001,0) [0|0.255] "1/s"  RadarFrontCenter
 SG_ VFC_Obj04A_NormVyEdgeLeft : 256|13@1+ (0.001,-4) [-4|4] "1/s"  RadarFrontCenter
 SG_ VFC_Obj04A_EdgeBottom : 269|12@1+ (0.00025,-0.5) [-0.5|0.5] "unitless"  RadarFrontCenter
 SG_ VFC_Obj04A_NormVyEdgeRight : 281|13@1+ (0.001,-4) [-4|4] "1/s"  RadarFrontCenter
 SG_ VFC_Obj04A_Width : 294|10@1+ (0.01,0) [0|10.23] "m"  RadarFrontCenter
 SG_ VFC_Obj04A_NormVx : 304|16@1+ (0.001,-40) [-40|25] "1/s"  RadarFrontCenter
 SG_ VFC_Obj04A_NormVyEdgeRightStdDev : 320|8@1+ (0.001,0) [0|0.255] "1/s"  RadarFrontCenter
 SG_ VFC_Obj04A_NormAxStdDev : 328|10@1+ (0.0025,0) [0|2.5575] "1/s^2"  RadarFrontCenter
 SG_ VFC_Obj04A_ScaleChange : 338|14@1+ (0.0001,0.5) [0.5|2.1383] "unitless"  RadarFrontCenter
 SG_ VFC_Obj04A_ScaleChngStdDev : 352|10@1+ (0.0001,0) [0|0.1023] "unitless"  RadarFrontCenter
 SG_ VFC_Obj04A_Reliability : 362|6@1+ (1,0) [0|63] ""  RadarFrontCenter
 SG_ VFC_Obj04A_NormVxStdDev : 368|10@1+ (0.001,0) [0|1.023] "1/s"  RadarFrontCenter
 SG_ VFC_Obj04A_TypeProb : 378|6@1+ (2,0) [0|100] "%"  RadarFrontCenter
 SG_ VFC_Obj04A_LengthStdDev : 384|7@1+ (0.05,0) [0|5] "m"  RadarFrontCenter
 SG_ VFC_Obj04A_WidthStdDev : 391|7@1+ (0.01,0) [0|1] "m"  RadarFrontCenter
 SG_ VFC_Obj04A_EdgeMid : 398|13@1+ (0.00025,-1) [-1|1] "unitless"  RadarFrontCenter
 SG_ VFC_Obj04A_EdgeLeft : 411|13@1+ (0.00025,-1) [-1|1] "unitless"  RadarFrontCenter
 SG_ VFC_Obj04A_EdgeRight : 424|13@1+ (0.00025,-1) [-1|1] "unitless"  RadarFrontCenter
 SG_ VFC_Obj04A_VisibleView : 437|3@1+ (1,0) [0|4] ""  RadarFrontCenter
 SG_ VFC_Obj04A_EdgeLeftStdDev : 440|8@1+ (0.0002,0) [0|0.051] "unitless"  RadarFrontCenter
 SG_ VFC_Obj04A_EdgeTop : 448|12@1+ (0.00025,-0.5) [-0.5|0.5] "unitless"  RadarFrontCenter
 SG_ VFC_Obj04A_HeadOrientation : 460|4@1+ (1,0) [0|15] ""  RadarFrontCenter
 SG_ VFC_Obj04A_EdgeMidStdDev : 464|8@1+ (0.0002,0) [0|0.051] "unitless"  RadarFrontCenter
 SG_ VFC_Obj04A_EdgeRightStdDev : 472|8@1+ (0.0002,0) [0|0.051] "unitless"  RadarFrontCenter
 SG_ VFC_Obj04A_EdgeTopStdDev : 480|8@1+ (0.0002,0) [0|0.051] "unitless"  RadarFrontCenter
 SG_ VFC_Obj04A_EdgeBottomStdDev : 488|8@1+ (0.0002,0) [0|0.051] "unitless"  RadarFrontCenter
 SG_ VFC_Obj04A_ClassifiedView : 496|3@1+ (1,0) [0|4] ""  RadarFrontCenter

BO_ 59 VFC_Object05A: 64 VideoFrontCenter
 SG_ VFC_Obj05A_CRC : 0|16@1+ (1,0) [0|65535] ""  RadarFrontCenter
 SG_ VFC_Obj05A_AliveCtr : 16|8@1+ (1,0) [0|255] ""  RadarFrontCenter
 SG_ VFC_Obj05A_ProtBlockCtr : 24|4@1+ (1,0) [0|15] ""  RadarFrontCenter
 SG_ VFC_Obj05A_ID : 32|8@1+ (1,0) [1|255] ""  RadarFrontCenter
 SG_ VFC_Obj05A_AxStdDev : 40|8@1+ (0.1,0) [0|25.5] "m/s^2"  RadarFrontCenter
 SG_ VFC_Obj05A_Dx : 48|12@1+ (0.05,0) [0|204.75] "m"  RadarFrontCenter
 SG_ VFC_Obj05A_Type : 60|4@1+ (1,0) [0|15] ""  RadarFrontCenter
 SG_ VFC_Obj05A_Dy : 64|14@1+ (0.01,-80) [-80|80] "m"  RadarFrontCenter
 SG_ VFC_Obj05A_Measured : 78|2@1+ (1,0) [0|3] ""  RadarFrontCenter
 SG_ VFC_Obj05A_Vx : 80|11@1+ (0.1,-154) [-154|50] "m/s"  RadarFrontCenter
 SG_ VFC_Obj05A_MeasSource : 91|5@1+ (1,0) [0|31] ""  RadarFrontCenter
 SG_ VFC_Obj05A_Vy : 96|10@1+ (0.1,-50) [-50|50] "m/s"  RadarFrontCenter
 SG_ VFC_Obj05A_DirIndicator : 106|3@1+ (1,0) [0|4] ""  RadarFrontCenter
 SG_ VFC_Obj05A_BrakeLight : 109|3@1+ (1,0) [0|7] ""  RadarFrontCenter
 SG_ VFC_Obj05A_Ax : 112|9@1+ (0.1,-16) [-16|16] "m/s^2"  RadarFrontCenter
 SG_ VFC_Obj05A_CompletelyInImg : 121|1@1+ (1,0) [0|1] ""  RadarFrontCenter
 SG_ VFC_Obj05A_ProbExist : 122|6@1+ (2,0) [0|100] "%"  RadarFrontCenter
 SG_ VFC_Obj05A_Ay : 128|8@1+ (0.1,-12) [-12|12] "m/s^2"  RadarFrontCenter
 SG_ VFC_Obj05A_AyStdDev : 136|8@1+ (0.1,0) [0|25.5] "m/s^2"  RadarFrontCenter
 SG_ VFC_Obj05A_DxStdDev : 144|10@1+ (0.05,0) [0|51.15] "m"  RadarFrontCenter
 SG_ VFC_Obj05A_ProbMovingLat : 154|6@1+ (2,0) [0|100] "%"  RadarFrontCenter
 SG_ VFC_Obj05A_DyStdDev : 160|10@1+ (0.02,0) [0|20.46] "m"  RadarFrontCenter
 SG_ VFC_Obj05A_ProbMovingLong : 170|6@1+ (2,0) [0|100] "%"  RadarFrontCenter
 SG_ VFC_Obj05A_VxStdDev : 176|10@1+ (0.1,0) [0|102.3] "m/s"  RadarFrontCenter
 SG_ VFC_Obj05A_HeadingAngleStdDev : 186|6@1+ (0.01,0) [0|0.5] "rad"  RadarFrontCenter
 SG_ VFC_Obj05A_VyStdDev : 192|9@1+ (0.1,0) [0|51.1] "m/s"  RadarFrontCenter
 SG_ VFC_Obj05A_HeightStdDev : 201|7@1+ (0.01,0) [0|1] "m"  RadarFrontCenter
 SG_ VFC_Obj05A_Height : 208|9@1+ (0.01,0) [0|5.11] "m"  RadarFrontCenter
 SG_ VFC_Obj05A_Length : 217|9@1+ (0.05,0) [0|25.55] "m"  RadarFrontCenter
 SG_ VFC_Obj05A_HeadingAngle : 226|9@1+ (0.01,-1.57) [-1.57|1.57] "rad"  RadarFrontCenter
 SG_ VFC_Obj05A_NormAx : 235|13@1+ (0.002,-10) [-10|6] "1/s^2"  RadarFrontCenter
 SG_ VFC_Obj05A_NormVyEdgeLeftStdDev : 248|8@1+ (0.001,0) [0|0.255] "1/s"  RadarFrontCenter
 SG_ VFC_Obj05A_NormVyEdgeLeft : 256|13@1+ (0.001,-4) [-4|4] "1/s"  RadarFrontCenter
 SG_ VFC_Obj05A_EdgeBottom : 269|12@1+ (0.00025,-0.5) [-0.5|0.5] "unitless"  RadarFrontCenter
 SG_ VFC_Obj05A_NormVyEdgeRight : 281|13@1+ (0.001,-4) [-4|4] "1/s"  RadarFrontCenter
 SG_ VFC_Obj05A_Width : 294|10@1+ (0.01,0) [0|10.23] "m"  RadarFrontCenter
 SG_ VFC_Obj05A_NormVx : 304|16@1+ (0.001,-40) [-40|25] "1/s"  RadarFrontCenter
 SG_ VFC_Obj05A_NormVyEdgeRightStdDev : 320|8@1+ (0.001,0) [0|0.255] "1/s"  RadarFrontCenter
 SG_ VFC_Obj05A_NormAxStdDev : 328|10@1+ (0.0025,0) [0|2.5575] "1/s^2"  RadarFrontCenter
 SG_ VFC_Obj05A_ScaleChange : 338|14@1+ (0.0001,0.5) [0.5|2.1383] "unitless"  RadarFrontCenter
 SG_ VFC_Obj05A_ScaleChngStdDev : 352|10@1+ (0.0001,0) [0|0.1023] "unitless"  RadarFrontCenter
 SG_ VFC_Obj05A_Reliability : 362|6@1+ (1,0) [0|63] ""  RadarFrontCenter
 SG_ VFC_Obj05A_NormVxStdDev : 368|10@1+ (0.001,0) [0|1.023] "1/s"  RadarFrontCenter
 SG_ VFC_Obj05A_TypeProb : 378|6@1+ (2,0) [0|100] "%"  RadarFrontCenter
 SG_ VFC_Obj05A_LengthStdDev : 384|7@1+ (0.05,0) [0|5] "m"  RadarFrontCenter
 SG_ VFC_Obj05A_WidthStdDev : 391|7@1+ (0.01,0) [0|1] "m"  RadarFrontCenter
 SG_ VFC_Obj05A_EdgeMid : 398|13@1+ (0.00025,-1) [-1|1] "unitless"  RadarFrontCenter
 SG_ VFC_Obj05A_EdgeLeft : 411|13@1+ (0.00025,-1) [-1|1] "unitless"  RadarFrontCenter
 SG_ VFC_Obj05A_EdgeRight : 424|13@1+ (0.00025,-1) [-1|1] "unitless"  RadarFrontCenter
 SG_ VFC_Obj05A_VisibleView : 437|3@1+ (1,0) [0|4] ""  RadarFrontCenter
 SG_ VFC_Obj05A_EdgeLeftStdDev : 440|8@1+ (0.0002,0) [0|0.051] "unitless"  RadarFrontCenter
 SG_ VFC_Obj05A_EdgeTop : 448|12@1+ (0.00025,-0.5) [-0.5|0.5] "unitless"  RadarFrontCenter
 SG_ VFC_Obj05A_HeadOrientation : 460|4@1+ (1,0) [0|15] ""  RadarFrontCenter
 SG_ VFC_Obj05A_EdgeMidStdDev : 464|8@1+ (0.0002,0) [0|0.051] "unitless"  RadarFrontCenter
 SG_ VFC_Obj05A_EdgeRightStdDev : 472|8@1+ (0.0002,0) [0|0.051] "unitless"  RadarFrontCenter
 SG_ VFC_Obj05A_EdgeTopStdDev : 480|8@1+ (0.0002,0) [0|0.051] "unitless"  RadarFrontCenter
 SG_ VFC_Obj05A_EdgeBottomStdDev : 488|8@1+ (0.0002,0) [0|0.051] "unitless"  RadarFrontCenter
 SG_ VFC_Obj05A_ClassifiedView : 496|3@1+ (1,0) [0|4] ""  RadarFrontCenter

BO_ 60 VFC_Object06A: 64 VideoFrontCenter
 SG_ VFC_Obj06A_CRC : 0|16@1+ (1,0) [0|65535] ""  RadarFrontCenter
 SG_ VFC_Obj06A_AliveCtr : 16|8@1+ (1,0) [0|255] ""  RadarFrontCenter
 SG_ VFC_Obj06A_ProtBlockCtr : 24|4@1+ (1,0) [0|15] ""  RadarFrontCenter
 SG_ VFC_Obj06A_ID : 32|8@1+ (1,0) [1|255] ""  RadarFrontCenter
 SG_ VFC_Obj06A_AxStdDev : 40|8@1+ (0.1,0) [0|25.5] "m/s^2"  RadarFrontCenter
 SG_ VFC_Obj06A_Dx : 48|12@1+ (0.05,0) [0|204.75] "m"  RadarFrontCenter
 SG_ VFC_Obj06A_Type : 60|4@1+ (1,0) [0|15] ""  RadarFrontCenter
 SG_ VFC_Obj06A_Dy : 64|14@1+ (0.01,-80) [-80|80] "m"  RadarFrontCenter
 SG_ VFC_Obj06A_Measured : 78|2@1+ (1,0) [0|3] ""  RadarFrontCenter
 SG_ VFC_Obj06A_Vx : 80|11@1+ (0.1,-154) [-154|50] "m/s"  RadarFrontCenter
 SG_ VFC_Obj06A_MeasSource : 91|5@1+ (1,0) [0|31] ""  RadarFrontCenter
 SG_ VFC_Obj06A_Vy : 96|10@1+ (0.1,-50) [-50|50] "m/s"  RadarFrontCenter
 SG_ VFC_Obj06A_DirIndicator : 106|3@1+ (1,0) [0|4] ""  RadarFrontCenter
 SG_ VFC_Obj06A_BrakeLight : 109|3@1+ (1,0) [0|7] ""  RadarFrontCenter
 SG_ VFC_Obj06A_Ax : 112|9@1+ (0.1,-16) [-16|16] "m/s^2"  RadarFrontCenter
 SG_ VFC_Obj06A_CompletelyInImg : 121|1@1+ (1,0) [0|1] ""  RadarFrontCenter
 SG_ VFC_Obj06A_ProbExist : 122|6@1+ (2,0) [0|100] "%"  RadarFrontCenter
 SG_ VFC_Obj06A_Ay : 128|8@1+ (0.1,-12) [-12|12] "m/s^2"  RadarFrontCenter
 SG_ VFC_Obj06A_AyStdDev : 136|8@1+ (0.1,0) [0|25.5] "m/s^2"  RadarFrontCenter
 SG_ VFC_Obj06A_DxStdDev : 144|10@1+ (0.05,0) [0|51.15] "m"  RadarFrontCenter
 SG_ VFC_Obj06A_ProbMovingLat : 154|6@1+ (2,0) [0|100] "%"  RadarFrontCenter
 SG_ VFC_Obj06A_DyStdDev : 160|10@1+ (0.02,0) [0|20.46] "m"  RadarFrontCenter
 SG_ VFC_Obj06A_ProbMovingLong : 170|6@1+ (2,0) [0|100] "%"  RadarFrontCenter
 SG_ VFC_Obj06A_VxStdDev : 176|10@1+ (0.1,0) [0|102.3] "m/s"  RadarFrontCenter
 SG_ VFC_Obj06A_HeadingAngleStdDev : 186|6@1+ (0.01,0) [0|0.5] "rad"  RadarFrontCenter
 SG_ VFC_Obj06A_VyStdDev : 192|9@1+ (0.1,0) [0|51.1] "m/s"  RadarFrontCenter
 SG_ VFC_Obj06A_HeightStdDev : 201|7@1+ (0.01,0) [0|1] "m"  RadarFrontCenter
 SG_ VFC_Obj06A_Height : 208|9@1+ (0.01,0) [0|5.11] "m"  RadarFrontCenter
 SG_ VFC_Obj06A_Length : 217|9@1+ (0.05,0) [0|25.55] "m"  RadarFrontCenter
 SG_ VFC_Obj06A_HeadingAngle : 226|9@1+ (0.01,-1.57) [-1.57|1.57] "rad"  RadarFrontCenter
 SG_ VFC_Obj06A_NormAx : 235|13@1+ (0.002,-10) [-10|6] "1/s^2"  RadarFrontCenter
 SG_ VFC_Obj06A_NormVyEdgeLeftStdDev : 248|8@1+ (0.001,0) [0|0.255] "1/s"  RadarFrontCenter
 SG_ VFC_Obj06A_NormVyEdgeLeft : 256|13@1+ (0.001,-4) [-4|4] "1/s"  RadarFrontCenter
 SG_ VFC_Obj06A_EdgeBottom : 269|12@1+ (0.00025,-0.5) [-0.5|0.5] "unitless"  RadarFrontCenter
 SG_ VFC_Obj06A_NormVyEdgeRight : 281|13@1+ (0.001,-4) [-4|4] "1/s"  RadarFrontCenter
 SG_ VFC_Obj06A_Width : 294|10@1+ (0.01,0) [0|10.23] "m"  RadarFrontCenter
 SG_ VFC_Obj06A_NormVx : 304|16@1+ (0.001,-40) [-40|25] "1/s"  RadarFrontCenter
 SG_ VFC_Obj06A_NormVyEdgeRightStdDev : 320|8@1+ (0.001,0) [0|0.255] "1/s"  RadarFrontCenter
 SG_ VFC_Obj06A_NormAxStdDev : 328|10@1+ (0.0025,0) [0|2.5575] "1/s^2"  RadarFrontCenter
 SG_ VFC_Obj06A_ScaleChange : 338|14@1+ (0.0001,0.5) [0.5|2.1383] "unitless"  RadarFrontCenter
 SG_ VFC_Obj06A_ScaleChngStdDev : 352|10@1+ (0.0001,0) [0|0.1023] "unitless"  RadarFrontCenter
 SG_ VFC_Obj06A_Reliability : 362|6@1+ (1,0) [0|63] ""  RadarFrontCenter
 SG_ VFC_Obj06A_NormVxStdDev : 368|10@1+ (0.001,0) [0|1.023] "1/s"  RadarFrontCenter
 SG_ VFC_Obj06A_TypeProb : 378|6@1+ (2,0) [0|100] "%"  RadarFrontCenter
 SG_ VFC_Obj06A_LengthStdDev : 384|7@1+ (0.05,0) [0|5] "m"  RadarFrontCenter
 SG_ VFC_Obj06A_WidthStdDev : 391|7@1+ (0.01,0) [0|1] "m"  RadarFrontCenter
 SG_ VFC_Obj06A_EdgeMid : 398|13@1+ (0.00025,-1) [-1|1] "unitless"  RadarFrontCenter
 SG_ VFC_Obj06A_EdgeLeft : 411|13@1+ (0.00025,-1) [-1|1] "unitless"  RadarFrontCenter
 SG_ VFC_Obj06A_EdgeRight : 424|13@1+ (0.00025,-1) [-1|1] "unitless"  RadarFrontCenter
 SG_ VFC_Obj06A_VisibleView : 437|3@1+ (1,0) [0|4] ""  RadarFrontCenter
 SG_ VFC_Obj06A_EdgeLeftStdDev : 440|8@1+ (0.0002,0) [0|0.051] "unitless"  RadarFrontCenter
 SG_ VFC_Obj06A_EdgeTop : 448|12@1+ (0.00025,-0.5) [-0.5|0.5] "unitless"  RadarFrontCenter
 SG_ VFC_Obj06A_HeadOrientation : 460|4@1+ (1,0) [0|15] ""  RadarFrontCenter
 SG_ VFC_Obj06A_EdgeMidStdDev : 464|8@1+ (0.0002,0) [0|0.051] "unitless"  RadarFrontCenter
 SG_ VFC_Obj06A_EdgeRightStdDev : 472|8@1+ (0.0002,0) [0|0.051] "unitless"  RadarFrontCenter
 SG_ VFC_Obj06A_EdgeTopStdDev : 480|8@1+ (0.0002,0) [0|0.051] "unitless"  RadarFrontCenter
 SG_ VFC_Obj06A_EdgeBottomStdDev : 488|8@1+ (0.0002,0) [0|0.051] "unitless"  RadarFrontCenter
 SG_ VFC_Obj06A_ClassifiedView : 496|3@1+ (1,0) [0|4] ""  RadarFrontCenter

BO_ 61 VFC_Object07A: 64 VideoFrontCenter
 SG_ VFC_Obj07A_CRC : 0|16@1+ (1,0) [0|65535] ""  RadarFrontCenter
 SG_ VFC_Obj07A_AliveCtr : 16|8@1+ (1,0) [0|255] ""  RadarFrontCenter
 SG_ VFC_Obj07A_ProtBlockCtr : 24|4@1+ (1,0) [0|15] ""  RadarFrontCenter
 SG_ VFC_Obj07A_ID : 32|8@1+ (1,0) [1|255] ""  RadarFrontCenter
 SG_ VFC_Obj07A_AxStdDev : 40|8@1+ (0.1,0) [0|25.5] "m/s^2"  RadarFrontCenter
 SG_ VFC_Obj07A_Dx : 48|12@1+ (0.05,0) [0|204.75] "m"  RadarFrontCenter
 SG_ VFC_Obj07A_Type : 60|4@1+ (1,0) [0|15] ""  RadarFrontCenter
 SG_ VFC_Obj07A_Dy : 64|14@1+ (0.01,-80) [-80|80] "m"  RadarFrontCenter
 SG_ VFC_Obj07A_Measured : 78|2@1+ (1,0) [0|3] ""  RadarFrontCenter
 SG_ VFC_Obj07A_Vx : 80|11@1+ (0.1,-154) [-154|50] "m/s"  RadarFrontCenter
 SG_ VFC_Obj07A_MeasSource : 91|5@1+ (1,0) [0|31] ""  RadarFrontCenter
 SG_ VFC_Obj07A_Vy : 96|10@1+ (0.1,-50) [-50|50] "m/s"  RadarFrontCenter
 SG_ VFC_Obj07A_DirIndicator : 106|3@1+ (1,0) [0|4] ""  RadarFrontCenter
 SG_ VFC_Obj07A_BrakeLight : 109|3@1+ (1,0) [0|7] ""  RadarFrontCenter
 SG_ VFC_Obj07A_Ax : 112|9@1+ (0.1,-16) [-16|16] "m/s^2"  RadarFrontCenter
 SG_ VFC_Obj07A_CompletelyInImg : 121|1@1+ (1,0) [0|1] ""  RadarFrontCenter
 SG_ VFC_Obj07A_ProbExist : 122|6@1+ (2,0) [0|100] "%"  RadarFrontCenter
 SG_ VFC_Obj07A_Ay : 128|8@1+ (0.1,-12) [-12|12] "m/s^2"  RadarFrontCenter
 SG_ VFC_Obj07A_AyStdDev : 136|8@1+ (0.1,0) [0|25.5] "m/s^2"  RadarFrontCenter
 SG_ VFC_Obj07A_DxStdDev : 144|10@1+ (0.05,0) [0|51.15] "m"  RadarFrontCenter
 SG_ VFC_Obj07A_ProbMovingLat : 154|6@1+ (2,0) [0|100] "%"  RadarFrontCenter
 SG_ VFC_Obj07A_DyStdDev : 160|10@1+ (0.02,0) [0|20.46] "m"  RadarFrontCenter
 SG_ VFC_Obj07A_ProbMovingLong : 170|6@1+ (2,0) [0|100] "%"  RadarFrontCenter
 SG_ VFC_Obj07A_VxStdDev : 176|10@1+ (0.1,0) [0|102.3] "m/s"  RadarFrontCenter
 SG_ VFC_Obj07A_HeadingAngleStdDev : 186|6@1+ (0.01,0) [0|0.5] "rad"  RadarFrontCenter
 SG_ VFC_Obj07A_VyStdDev : 192|9@1+ (0.1,0) [0|51.1] "m/s"  RadarFrontCenter
 SG_ VFC_Obj07A_HeightStdDev : 201|7@1+ (0.01,0) [0|1] "m"  RadarFrontCenter
 SG_ VFC_Obj07A_Height : 208|9@1+ (0.01,0) [0|5.11] "m"  RadarFrontCenter
 SG_ VFC_Obj07A_Length : 217|9@1+ (0.05,0) [0|25.55] "m"  RadarFrontCenter
 SG_ VFC_Obj07A_HeadingAngle : 226|9@1+ (0.01,-1.57) [-1.57|1.57] "rad"  RadarFrontCenter
 SG_ VFC_Obj07A_NormAx : 235|13@1+ (0.002,-10) [-10|6] "1/s^2"  RadarFrontCenter
 SG_ VFC_Obj07A_NormVyEdgeLeftStdDev : 248|8@1+ (0.001,0) [0|0.255] "1/s"  RadarFrontCenter
 SG_ VFC_Obj07A_NormVyEdgeLeft : 256|13@1+ (0.001,-4) [-4|4] "1/s"  RadarFrontCenter
 SG_ VFC_Obj07A_EdgeBottom : 269|12@1+ (0.00025,-0.5) [-0.5|0.5] "unitless"  RadarFrontCenter
 SG_ VFC_Obj07A_NormVyEdgeRight : 281|13@1+ (0.001,-4) [-4|4] "1/s"  RadarFrontCenter
 SG_ VFC_Obj07A_Width : 294|10@1+ (0.01,0) [0|10.23] "m"  RadarFrontCenter
 SG_ VFC_Obj07A_NormVx : 304|16@1+ (0.001,-40) [-40|25] "1/s"  RadarFrontCenter
 SG_ VFC_Obj07A_NormVyEdgeRightStdDev : 320|8@1+ (0.001,0) [0|0.255] "1/s"  RadarFrontCenter
 SG_ VFC_Obj07A_NormAxStdDev : 328|10@1+ (0.0025,0) [0|2.5575] "1/s^2"  RadarFrontCenter
 SG_ VFC_Obj07A_ScaleChange : 338|14@1+ (0.0001,0.5) [0.5|2.1383] "unitless"  RadarFrontCenter
 SG_ VFC_Obj07A_ScaleChngStdDev : 352|10@1+ (0.0001,0) [0|0.1023] "unitless"  RadarFrontCenter
 SG_ VFC_Obj07A_Reliability : 362|6@1+ (1,0) [0|63] ""  RadarFrontCenter
 SG_ VFC_Obj07A_NormVxStdDev : 368|10@1+ (0.001,0) [0|1.023] "1/s"  RadarFrontCenter
 SG_ VFC_Obj07A_TypeProb : 378|6@1+ (2,0) [0|100] "%"  RadarFrontCenter
 SG_ VFC_Obj07A_LengthStdDev : 384|7@1+ (0.05,0) [0|5] "m"  RadarFrontCenter
 SG_ VFC_Obj07A_WidthStdDev : 391|7@1+ (0.01,0) [0|1] "m"  RadarFrontCenter
 SG_ VFC_Obj07A_EdgeMid : 398|13@1+ (0.00025,-1) [-1|1] "unitless"  RadarFrontCenter
 SG_ VFC_Obj07A_EdgeLeft : 411|13@1+ (0.00025,-1) [-1|1] "unitless"  RadarFrontCenter
 SG_ VFC_Obj07A_EdgeRight : 424|13@1+ (0.00025,-1) [-1|1] "unitless"  RadarFrontCenter
 SG_ VFC_Obj07A_VisibleView : 437|3@1+ (1,0) [0|4] ""  RadarFrontCenter
 SG_ VFC_Obj07A_EdgeLeftStdDev : 440|8@1+ (0.0002,0) [0|0.051] "unitless"  RadarFrontCenter
 SG_ VFC_Obj07A_EdgeTop : 448|12@1+ (0.00025,-0.5) [-0.5|0.5] "unitless"  RadarFrontCenter
 SG_ VFC_Obj07A_HeadOrientation : 460|4@1+ (1,0) [0|15] ""  RadarFrontCenter
 SG_ VFC_Obj07A_EdgeMidStdDev : 464|8@1+ (0.0002,0) [0|0.051] "unitless"  RadarFrontCenter
 SG_ VFC_Obj07A_EdgeRightStdDev : 472|8@1+ (0.0002,0) [0|0.051] "unitless"  RadarFrontCenter
 SG_ VFC_Obj07A_EdgeTopStdDev : 480|8@1+ (0.0002,0) [0|0.051] "unitless"  RadarFrontCenter
 SG_ VFC_Obj07A_EdgeBottomStdDev : 488|8@1+ (0.0002,0) [0|0.051] "unitless"  RadarFrontCenter
 SG_ VFC_Obj07A_ClassifiedView : 496|3@1+ (1,0) [0|4] ""  RadarFrontCenter

BO_ 62 VFC_Object08A: 64 VideoFrontCenter
 SG_ VFC_Obj08A_CRC : 0|16@1+ (1,0) [0|65535] ""  RadarFrontCenter
 SG_ VFC_Obj08A_AliveCtr : 16|8@1+ (1,0) [0|255] ""  RadarFrontCenter
 SG_ VFC_Obj08A_ProtBlockCtr : 24|4@1+ (1,0) [0|15] ""  RadarFrontCenter
 SG_ VFC_Obj08A_ID : 32|8@1+ (1,0) [1|255] ""  RadarFrontCenter
 SG_ VFC_Obj08A_AxStdDev : 40|8@1+ (0.1,0) [0|25.5] "m/s^2"  RadarFrontCenter
 SG_ VFC_Obj08A_Dx : 48|12@1+ (0.05,0) [0|204.75] "m"  RadarFrontCenter
 SG_ VFC_Obj08A_Type : 60|4@1+ (1,0) [0|15] ""  RadarFrontCenter
 SG_ VFC_Obj08A_Dy : 64|14@1+ (0.01,-80) [-80|80] "m"  RadarFrontCenter
 SG_ VFC_Obj08A_Measured : 78|2@1+ (1,0) [0|3] ""  RadarFrontCenter
 SG_ VFC_Obj08A_Vx : 80|11@1+ (0.1,-154) [-154|50] "m/s"  RadarFrontCenter
 SG_ VFC_Obj08A_MeasSource : 91|5@1+ (1,0) [0|31] ""  RadarFrontCenter
 SG_ VFC_Obj08A_Vy : 96|10@1+ (0.1,-50) [-50|50] "m/s"  RadarFrontCenter
 SG_ VFC_Obj08A_DirIndicator : 106|3@1+ (1,0) [0|4] ""  RadarFrontCenter
 SG_ VFC_Obj08A_BrakeLight : 109|3@1+ (1,0) [0|7] ""  RadarFrontCenter
 SG_ VFC_Obj08A_Ax : 112|9@1+ (0.1,-16) [-16|16] "m/s^2"  RadarFrontCenter
 SG_ VFC_Obj08A_CompletelyInImg : 121|1@1+ (1,0) [0|1] ""  RadarFrontCenter
 SG_ VFC_Obj08A_ProbExist : 122|6@1+ (2,0) [0|100] "%"  RadarFrontCenter
 SG_ VFC_Obj08A_Ay : 128|8@1+ (0.1,-12) [-12|12] "m/s^2"  RadarFrontCenter
 SG_ VFC_Obj08A_AyStdDev : 136|8@1+ (0.1,0) [0|25.5] "m/s^2"  RadarFrontCenter
 SG_ VFC_Obj08A_DxStdDev : 144|10@1+ (0.05,0) [0|51.15] "m"  RadarFrontCenter
 SG_ VFC_Obj08A_ProbMovingLat : 154|6@1+ (2,0) [0|100] "%"  RadarFrontCenter
 SG_ VFC_Obj08A_DyStdDev : 160|10@1+ (0.02,0) [0|20.46] "m"  RadarFrontCenter
 SG_ VFC_Obj08A_ProbMovingLong : 170|6@1+ (2,0) [0|100] "%"  RadarFrontCenter
 SG_ VFC_Obj08A_VxStdDev : 176|10@1+ (0.1,0) [0|102.3] "m/s"  RadarFrontCenter
 SG_ VFC_Obj08A_HeadingAngleStdDev : 186|6@1+ (0.01,0) [0|0.5] "rad"  RadarFrontCenter
 SG_ VFC_Obj08A_VyStdDev : 192|9@1+ (0.1,0) [0|51.1] "m/s"  RadarFrontCenter
 SG_ VFC_Obj08A_HeightStdDev : 201|7@1+ (0.01,0) [0|1] "m"  RadarFrontCenter
 SG_ VFC_Obj08A_Height : 208|9@1+ (0.01,0) [0|5.11] "m"  RadarFrontCenter
 SG_ VFC_Obj08A_Length : 217|9@1+ (0.05,0) [0|25.55] "m"  RadarFrontCenter
 SG_ VFC_Obj08A_HeadingAngle : 226|9@1+ (0.01,-1.57) [-1.57|1.57] "rad"  RadarFrontCenter
 SG_ VFC_Obj08A_NormAx : 235|13@1+ (0.002,-10) [-10|6] "1/s^2"  RadarFrontCenter
 SG_ VFC_Obj08A_NormVyEdgeLeftStdDev : 248|8@1+ (0.001,0) [0|0.255] "1/s"  RadarFrontCenter
 SG_ VFC_Obj08A_NormVyEdgeLeft : 256|13@1+ (0.001,-4) [-4|4] "1/s"  RadarFrontCenter
 SG_ VFC_Obj08A_EdgeBottom : 269|12@1+ (0.00025,-0.5) [-0.5|0.5] "unitless"  RadarFrontCenter
 SG_ VFC_Obj08A_NormVyEdgeRight : 281|13@1+ (0.001,-4) [-4|4] "1/s"  RadarFrontCenter
 SG_ VFC_Obj08A_Width : 294|10@1+ (0.01,0) [0|10.23] "m"  RadarFrontCenter
 SG_ VFC_Obj08A_NormVx : 304|16@1+ (0.001,-40) [-40|25] "1/s"  RadarFrontCenter
 SG_ VFC_Obj08A_NormVyEdgeRightStdDev : 320|8@1+ (0.001,0) [0|0.255] "1/s"  RadarFrontCenter
 SG_ VFC_Obj08A_NormAxStdDev : 328|10@1+ (0.0025,0) [0|2.5575] "1/s^2"  RadarFrontCenter
 SG_ VFC_Obj08A_ScaleChange : 338|14@1+ (0.0001,0.5) [0.5|2.1383] "unitless"  RadarFrontCenter
 SG_ VFC_Obj08A_ScaleChngStdDev : 352|10@1+ (0.0001,0) [0|0.1023] "unitless"  RadarFrontCenter
 SG_ VFC_Obj08A_Reliability : 362|6@1+ (1,0) [0|63] ""  RadarFrontCenter
 SG_ VFC_Obj08A_NormVxStdDev : 368|10@1+ (0.001,0) [0|1.023] "1/s"  RadarFrontCenter
 SG_ VFC_Obj08A_TypeProb : 378|6@1+ (2,0) [0|100] "%"  RadarFrontCenter
 SG_ VFC_Obj08A_LengthStdDev : 384|7@1+ (0.05,0) [0|5] "m"  RadarFrontCenter
 SG_ VFC_Obj08A_WidthStdDev : 391|7@1+ (0.01,0) [0|1] "m"  RadarFrontCenter
 SG_ VFC_Obj08A_EdgeMid : 398|13@1+ (0.00025,-1) [-1|1] "unitless"  RadarFrontCenter
 SG_ VFC_Obj08A_EdgeLeft : 411|13@1+ (0.00025,-1) [-1|1] "unitless"  RadarFrontCenter
 SG_ VFC_Obj08A_EdgeRight : 424|13@1+ (0.00025,-1) [-1|1] "unitless"  RadarFrontCenter
 SG_ VFC_Obj08A_VisibleView : 437|3@1+ (1,0) [0|4] ""  RadarFrontCenter
 SG_ VFC_Obj08A_EdgeLeftStdDev : 440|8@1+ (0.0002,0) [0|0.051] "unitless"  RadarFrontCenter
 SG_ VFC_Obj08A_EdgeTop : 448|12@1+ (0.00025,-0.5) [-0.5|0.5] "unitless"  RadarFrontCenter
 SG_ VFC_Obj08A_HeadOrientation : 460|4@1+ (1,0) [0|15] ""  RadarFrontCenter
 SG_ VFC_Obj08A_EdgeMidStdDev : 464|8@1+ (0.0002,0) [0|0.051] "unitless"  RadarFrontCenter
 SG_ VFC_Obj08A_EdgeRightStdDev : 472|8@1+ (0.0002,0) [0|0.051] "unitless"  RadarFrontCenter
 SG_ VFC_Obj08A_EdgeTopStdDev : 480|8@1+ (0.0002,0) [0|0.051] "unitless"  RadarFrontCenter
 SG_ VFC_Obj08A_EdgeBottomStdDev : 488|8@1+ (0.0002,0) [0|0.051] "unitless"  RadarFrontCenter
 SG_ VFC_Obj08A_ClassifiedView : 496|3@1+ (1,0) [0|4] ""  RadarFrontCenter

BO_ 63 VFC_Object09A: 64 VideoFrontCenter
 SG_ VFC_Obj09A_CRC : 0|16@1+ (1,0) [0|65535] ""  RadarFrontCenter
 SG_ VFC_Obj09A_AliveCtr : 16|8@1+ (1,0) [0|255] ""  RadarFrontCenter
 SG_ VFC_Obj09A_ProtBlockCtr : 24|4@1+ (1,0) [0|15] ""  RadarFrontCenter
 SG_ VFC_Obj09A_ID : 32|8@1+ (1,0) [1|255] ""  RadarFrontCenter
 SG_ VFC_Obj09A_AxStdDev : 40|8@1+ (0.1,0) [0|25.5] "m/s^2"  RadarFrontCenter
 SG_ VFC_Obj09A_Dx : 48|12@1+ (0.05,0) [0|204.75] "m"  RadarFrontCenter
 SG_ VFC_Obj09A_Type : 60|4@1+ (1,0) [0|15] ""  RadarFrontCenter
 SG_ VFC_Obj09A_Dy : 64|14@1+ (0.01,-80) [-80|80] "m"  RadarFrontCenter
 SG_ VFC_Obj09A_Measured : 78|2@1+ (1,0) [0|3] ""  RadarFrontCenter
 SG_ VFC_Obj09A_Vx : 80|11@1+ (0.1,-154) [-154|50] "m/s"  RadarFrontCenter
 SG_ VFC_Obj09A_MeasSource : 91|5@1+ (1,0) [0|31] ""  RadarFrontCenter
 SG_ VFC_Obj09A_Vy : 96|10@1+ (0.1,-50) [-50|50] "m/s"  RadarFrontCenter
 SG_ VFC_Obj09A_DirIndicator : 106|3@1+ (1,0) [0|4] ""  RadarFrontCenter
 SG_ VFC_Obj09A_BrakeLight : 109|3@1+ (1,0) [0|7] ""  RadarFrontCenter
 SG_ VFC_Obj09A_Ax : 112|9@1+ (0.1,-16) [-16|16] "m/s^2"  RadarFrontCenter
 SG_ VFC_Obj09A_CompletelyInImg : 121|1@1+ (1,0) [0|1] ""  RadarFrontCenter
 SG_ VFC_Obj09A_ProbExist : 122|6@1+ (2,0) [0|100] "%"  RadarFrontCenter
 SG_ VFC_Obj09A_Ay : 128|8@1+ (0.1,-12) [-12|12] "m/s^2"  RadarFrontCenter
 SG_ VFC_Obj09A_AyStdDev : 136|8@1+ (0.1,0) [0|25.5] "m/s^2"  RadarFrontCenter
 SG_ VFC_Obj09A_DxStdDev : 144|10@1+ (0.05,0) [0|51.15] "m"  RadarFrontCenter
 SG_ VFC_Obj09A_ProbMovingLat : 154|6@1+ (2,0) [0|100] "%"  RadarFrontCenter
 SG_ VFC_Obj09A_DyStdDev : 160|10@1+ (0.02,0) [0|20.46] "m"  RadarFrontCenter
 SG_ VFC_Obj09A_ProbMovingLong : 170|6@1+ (2,0) [0|100] "%"  RadarFrontCenter
 SG_ VFC_Obj09A_VxStdDev : 176|10@1+ (0.1,0) [0|102.3] "m/s"  RadarFrontCenter
 SG_ VFC_Obj09A_HeadingAngleStdDev : 186|6@1+ (0.01,0) [0|0.5] "rad"  RadarFrontCenter
 SG_ VFC_Obj09A_VyStdDev : 192|9@1+ (0.1,0) [0|51.1] "m/s"  RadarFrontCenter
 SG_ VFC_Obj09A_HeightStdDev : 201|7@1+ (0.01,0) [0|1] "m"  RadarFrontCenter
 SG_ VFC_Obj09A_Height : 208|9@1+ (0.01,0) [0|5.11] "m"  RadarFrontCenter
 SG_ VFC_Obj09A_Length : 217|9@1+ (0.05,0) [0|25.55] "m"  RadarFrontCenter
 SG_ VFC_Obj09A_HeadingAngle : 226|9@1+ (0.01,-1.57) [-1.57|1.57] "rad"  RadarFrontCenter
 SG_ VFC_Obj09A_NormAx : 235|13@1+ (0.002,-10) [-10|6] "1/s^2"  RadarFrontCenter
 SG_ VFC_Obj09A_NormVyEdgeLeftStdDev : 248|8@1+ (0.001,0) [0|0.255] "1/s"  RadarFrontCenter
 SG_ VFC_Obj09A_NormVyEdgeLeft : 256|13@1+ (0.001,-4) [-4|4] "1/s"  RadarFrontCenter
 SG_ VFC_Obj09A_EdgeBottom : 269|12@1+ (0.00025,-0.5) [-0.5|0.5] "unitless"  RadarFrontCenter
 SG_ VFC_Obj09A_NormVyEdgeRight : 281|13@1+ (0.001,-4) [-4|4] "1/s"  RadarFrontCenter
 SG_ VFC_Obj09A_Width : 294|10@1+ (0.01,0) [0|10.23] "m"  RadarFrontCenter
 SG_ VFC_Obj09A_NormVx : 304|16@1+ (0.001,-40) [-40|25] "1/s"  RadarFrontCenter
 SG_ VFC_Obj09A_NormVyEdgeRightStdDev : 320|8@1+ (0.001,0) [0|0.255] "1/s"  RadarFrontCenter
 SG_ VFC_Obj09A_NormAxStdDev : 328|10@1+ (0.0025,0) [0|2.5575] "1/s^2"  RadarFrontCenter
 SG_ VFC_Obj09A_ScaleChange : 338|14@1+ (0.0001,0.5) [0.5|2.1383] "unitless"  RadarFrontCenter
 SG_ VFC_Obj09A_ScaleChngStdDev : 352|10@1+ (0.0001,0) [0|0.1023] "unitless"  RadarFrontCenter
 SG_ VFC_Obj09A_Reliability : 362|6@1+ (1,0) [0|63] ""  RadarFrontCenter
 SG_ VFC_Obj09A_NormVxStdDev : 368|10@1+ (0.001,0) [0|1.023] "1/s"  RadarFrontCenter
 SG_ VFC_Obj09A_TypeProb : 378|6@1+ (2,0) [0|100] "%"  RadarFrontCenter
 SG_ VFC_Obj09A_LengthStdDev : 384|7@1+ (0.05,0) [0|5] "m"  RadarFrontCenter
 SG_ VFC_Obj09A_WidthStdDev : 391|7@1+ (0.01,0) [0|1] "m"  RadarFrontCenter
 SG_ VFC_Obj09A_EdgeMid : 398|13@1+ (0.00025,-1) [-1|1] "unitless"  RadarFrontCenter
 SG_ VFC_Obj09A_EdgeLeft : 411|13@1+ (0.00025,-1) [-1|1] "unitless"  RadarFrontCenter
 SG_ VFC_Obj09A_EdgeRight : 424|13@1+ (0.00025,-1) [-1|1] "unitless"  RadarFrontCenter
 SG_ VFC_Obj09A_VisibleView : 437|3@1+ (1,0) [0|4] ""  RadarFrontCenter
 SG_ VFC_Obj09A_EdgeLeftStdDev : 440|8@1+ (0.0002,0) [0|0.051] "unitless"  RadarFrontCenter
 SG_ VFC_Obj09A_EdgeTop : 448|12@1+ (0.00025,-0.5) [-0.5|0.5] "unitless"  RadarFrontCenter
 SG_ VFC_Obj09A_HeadOrientation : 460|4@1+ (1,0) [0|15] ""  RadarFrontCenter
 SG_ VFC_Obj09A_EdgeMidStdDev : 464|8@1+ (0.0002,0) [0|0.051] "unitless"  RadarFrontCenter
 SG_ VFC_Obj09A_EdgeRightStdDev : 472|8@1+ (0.0002,0) [0|0.051] "unitless"  RadarFrontCenter
 SG_ VFC_Obj09A_EdgeTopStdDev : 480|8@1+ (0.0002,0) [0|0.051] "unitless"  RadarFrontCenter
 SG_ VFC_Obj09A_EdgeBottomStdDev : 488|8@1+ (0.0002,0) [0|0.051] "unitless"  RadarFrontCenter
 SG_ VFC_Obj09A_ClassifiedView : 496|3@1+ (1,0) [0|4] ""  RadarFrontCenter

BO_ 64 VFC_Object10A: 64 VideoFrontCenter
 SG_ VFC_Obj10A_CRC : 0|16@1+ (1,0) [0|65535] ""  RadarFrontCenter
 SG_ VFC_Obj10A_AliveCtr : 16|8@1+ (1,0) [0|255] ""  RadarFrontCenter
 SG_ VFC_Obj10A_ProtBlockCtr : 24|4@1+ (1,0) [0|15] ""  RadarFrontCenter
 SG_ VFC_Obj10A_ID : 32|8@1+ (1,0) [1|255] ""  RadarFrontCenter
 SG_ VFC_Obj10A_AxStdDev : 40|8@1+ (0.1,0) [0|25.5] "m/s^2"  RadarFrontCenter
 SG_ VFC_Obj10A_Dx : 48|12@1+ (0.05,0) [0|204.75] "m"  RadarFrontCenter
 SG_ VFC_Obj10A_Type : 60|4@1+ (1,0) [0|15] ""  RadarFrontCenter
 SG_ VFC_Obj10A_Dy : 64|14@1+ (0.01,-80) [-80|80] "m"  RadarFrontCenter
 SG_ VFC_Obj10A_Measured : 78|2@1+ (1,0) [0|3] ""  RadarFrontCenter
 SG_ VFC_Obj10A_Vx : 80|11@1+ (0.1,-154) [-154|50] "m/s"  RadarFrontCenter
 SG_ VFC_Obj10A_MeasSource : 91|5@1+ (1,0) [0|31] ""  RadarFrontCenter
 SG_ VFC_Obj10A_Vy : 96|10@1+ (0.1,-50) [-50|50] "m/s"  RadarFrontCenter
 SG_ VFC_Obj10A_DirIndicator : 106|3@1+ (1,0) [0|4] ""  RadarFrontCenter
 SG_ VFC_Obj10A_BrakeLight : 109|3@1+ (1,0) [0|7] ""  RadarFrontCenter
 SG_ VFC_Obj10A_Ax : 112|9@1+ (0.1,-16) [-16|16] "m/s^2"  RadarFrontCenter
 SG_ VFC_Obj10A_CompletelyInImg : 121|1@1+ (1,0) [0|1] ""  RadarFrontCenter
 SG_ VFC_Obj10A_ProbExist : 122|6@1+ (2,0) [0|100] "%"  RadarFrontCenter
 SG_ VFC_Obj10A_Ay : 128|8@1+ (0.1,-12) [-12|12] "m/s^2"  RadarFrontCenter
 SG_ VFC_Obj10A_AyStdDev : 136|8@1+ (0.1,0) [0|25.5] "m/s^2"  RadarFrontCenter
 SG_ VFC_Obj10A_DxStdDev : 144|10@1+ (0.05,0) [0|51.15] "m"  RadarFrontCenter
 SG_ VFC_Obj10A_ProbMovingLat : 154|6@1+ (2,0) [0|100] "%"  RadarFrontCenter
 SG_ VFC_Obj10A_DyStdDev : 160|10@1+ (0.02,0) [0|20.46] "m"  RadarFrontCenter
 SG_ VFC_Obj10A_ProbMovingLong : 170|6@1+ (2,0) [0|100] "%"  RadarFrontCenter
 SG_ VFC_Obj10A_VxStdDev : 176|10@1+ (0.1,0) [0|102.3] "m/s"  RadarFrontCenter
 SG_ VFC_Obj10A_HeadingAngleStdDev : 186|6@1+ (0.01,0) [0|0.5] "rad"  RadarFrontCenter
 SG_ VFC_Obj10A_VyStdDev : 192|9@1+ (0.1,0) [0|51.1] "m/s"  RadarFrontCenter
 SG_ VFC_Obj10A_HeightStdDev : 201|7@1+ (0.01,0) [0|1] "m"  RadarFrontCenter
 SG_ VFC_Obj10A_Height : 208|9@1+ (0.01,0) [0|5.11] "m"  RadarFrontCenter
 SG_ VFC_Obj10A_Length : 217|9@1+ (0.05,0) [0|25.55] "m"  RadarFrontCenter
 SG_ VFC_Obj10A_HeadingAngle : 226|9@1+ (0.01,-1.57) [-1.57|1.57] "rad"  RadarFrontCenter
 SG_ VFC_Obj10A_NormAx : 235|13@1+ (0.002,-10) [-10|6] "1/s^2"  RadarFrontCenter
 SG_ VFC_Obj10A_NormVyEdgeLeftStdDev : 248|8@1+ (0.001,0) [0|0.255] "1/s"  RadarFrontCenter
 SG_ VFC_Obj10A_NormVyEdgeLeft : 256|13@1+ (0.001,-4) [-4|4] "1/s"  RadarFrontCenter
 SG_ VFC_Obj10A_EdgeBottom : 269|12@1+ (0.00025,-0.5) [-0.5|0.5] "unitless"  RadarFrontCenter
 SG_ VFC_Obj10A_NormVyEdgeRight : 281|13@1+ (0.001,-4) [-4|4] "1/s"  RadarFrontCenter
 SG_ VFC_Obj10A_Width : 294|10@1+ (0.01,0) [0|10.23] "m"  RadarFrontCenter
 SG_ VFC_Obj10A_NormVx : 304|16@1+ (0.001,-40) [-40|25] "1/s"  RadarFrontCenter
 SG_ VFC_Obj10A_NormVyEdgeRightStdDev : 320|8@1+ (0.001,0) [0|0.255] "1/s"  RadarFrontCenter
 SG_ VFC_Obj10A_NormAxStdDev : 328|10@1+ (0.0025,0) [0|2.5575] "1/s^2"  RadarFrontCenter
 SG_ VFC_Obj10A_ScaleChange : 338|14@1+ (0.0001,0.5) [0.5|2.1383] "unitless"  RadarFrontCenter
 SG_ VFC_Obj10A_ScaleChngStdDev : 352|10@1+ (0.0001,0) [0|0.1023] "unitless"  RadarFrontCenter
 SG_ VFC_Obj10A_Reliability : 362|6@1+ (1,0) [0|63] ""  RadarFrontCenter
 SG_ VFC_Obj10A_NormVxStdDev : 368|10@1+ (0.001,0) [0|1.023] "1/s"  RadarFrontCenter
 SG_ VFC_Obj10A_TypeProb : 378|6@1+ (2,0) [0|100] "%"  RadarFrontCenter
 SG_ VFC_Obj10A_LengthStdDev : 384|7@1+ (0.05,0) [0|5] "m"  RadarFrontCenter
 SG_ VFC_Obj10A_WidthStdDev : 391|7@1+ (0.01,0) [0|1] "m"  RadarFrontCenter
 SG_ VFC_Obj10A_EdgeMid : 398|13@1+ (0.00025,-1) [-1|1] "unitless"  RadarFrontCenter
 SG_ VFC_Obj10A_EdgeLeft : 411|13@1+ (0.00025,-1) [-1|1] "unitless"  RadarFrontCenter
 SG_ VFC_Obj10A_EdgeRight : 424|13@1+ (0.00025,-1) [-1|1] "unitless"  RadarFrontCenter
 SG_ VFC_Obj10A_VisibleView : 437|3@1+ (1,0) [0|4] ""  RadarFrontCenter
 SG_ VFC_Obj10A_EdgeLeftStdDev : 440|8@1+ (0.0002,0) [0|0.051] "unitless"  RadarFrontCenter
 SG_ VFC_Obj10A_EdgeTop : 448|12@1+ (0.00025,-0.5) [-0.5|0.5] "unitless"  RadarFrontCenter
 SG_ VFC_Obj10A_HeadOrientation : 460|4@1+ (1,0) [0|15] ""  RadarFrontCenter
 SG_ VFC_Obj10A_EdgeMidStdDev : 464|8@1+ (0.0002,0) [0|0.051] "unitless"  RadarFrontCenter
 SG_ VFC_Obj10A_EdgeRightStdDev : 472|8@1+ (0.0002,0) [0|0.051] "unitless"  RadarFrontCenter
 SG_ VFC_Obj10A_EdgeTopStdDev : 480|8@1+ (0.0002,0) [0|0.051] "unitless"  RadarFrontCenter
 SG_ VFC_Obj10A_EdgeBottomStdDev : 488|8@1+ (0.0002,0) [0|0.051] "unitless"  RadarFrontCenter
 SG_ VFC_Obj10A_ClassifiedView : 496|3@1+ (1,0) [0|4] ""  RadarFrontCenter

BO_ 65 VFC_Object11A: 64 VideoFrontCenter
 SG_ VFC_Obj11A_CRC : 0|16@1+ (1,0) [0|65535] ""  RadarFrontCenter
 SG_ VFC_Obj11A_AliveCtr : 16|8@1+ (1,0) [0|255] ""  RadarFrontCenter
 SG_ VFC_Obj11A_ProtBlockCtr : 24|4@1+ (1,0) [0|15] ""  RadarFrontCenter
 SG_ VFC_Obj11A_ID : 32|8@1+ (1,0) [1|255] ""  RadarFrontCenter
 SG_ VFC_Obj11A_AxStdDev : 40|8@1+ (0.1,0) [0|25.5] "m/s^2"  RadarFrontCenter
 SG_ VFC_Obj11A_Dx : 48|12@1+ (0.05,0) [0|204.75] "m"  RadarFrontCenter
 SG_ VFC_Obj11A_Type : 60|4@1+ (1,0) [0|15] ""  RadarFrontCenter
 SG_ VFC_Obj11A_Dy : 64|14@1+ (0.01,-80) [-80|80] "m"  RadarFrontCenter
 SG_ VFC_Obj11A_Measured : 78|2@1+ (1,0) [0|3] ""  RadarFrontCenter
 SG_ VFC_Obj11A_Vx : 80|11@1+ (0.1,-154) [-154|50] "m/s"  RadarFrontCenter
 SG_ VFC_Obj11A_MeasSource : 91|5@1+ (1,0) [0|31] ""  RadarFrontCenter
 SG_ VFC_Obj11A_Vy : 96|10@1+ (0.1,-50) [-50|50] "m/s"  RadarFrontCenter
 SG_ VFC_Obj11A_DirIndicator : 106|3@1+ (1,0) [0|4] ""  RadarFrontCenter
 SG_ VFC_Obj11A_BrakeLight : 109|3@1+ (1,0) [0|7] ""  RadarFrontCenter
 SG_ VFC_Obj11A_Ax : 112|9@1+ (0.1,-16) [-16|16] "m/s^2"  RadarFrontCenter
 SG_ VFC_Obj11A_CompletelyInImg : 121|1@1+ (1,0) [0|1] ""  RadarFrontCenter
 SG_ VFC_Obj11A_ProbExist : 122|6@1+ (2,0) [0|100] "%"  RadarFrontCenter
 SG_ VFC_Obj11A_Ay : 128|8@1+ (0.1,-12) [-12|12] "m/s^2"  RadarFrontCenter
 SG_ VFC_Obj11A_AyStdDev : 136|8@1+ (0.1,0) [0|25.5] "m/s^2"  RadarFrontCenter
 SG_ VFC_Obj11A_DxStdDev : 144|10@1+ (0.05,0) [0|51.15] "m"  RadarFrontCenter
 SG_ VFC_Obj11A_ProbMovingLat : 154|6@1+ (2,0) [0|100] "%"  RadarFrontCenter
 SG_ VFC_Obj11A_DyStdDev : 160|10@1+ (0.02,0) [0|20.46] "m"  RadarFrontCenter
 SG_ VFC_Obj11A_ProbMovingLong : 170|6@1+ (2,0) [0|100] "%"  RadarFrontCenter
 SG_ VFC_Obj11A_VxStdDev : 176|10@1+ (0.1,0) [0|102.3] "m/s"  RadarFrontCenter
 SG_ VFC_Obj11A_HeadingAngleStdDev : 186|6@1+ (0.01,0) [0|0.5] "rad"  RadarFrontCenter
 SG_ VFC_Obj11A_VyStdDev : 192|9@1+ (0.1,0) [0|51.1] "m/s"  RadarFrontCenter
 SG_ VFC_Obj11A_HeightStdDev : 201|7@1+ (0.01,0) [0|1] "m"  RadarFrontCenter
 SG_ VFC_Obj11A_Height : 208|9@1+ (0.01,0) [0|5.11] "m"  RadarFrontCenter
 SG_ VFC_Obj11A_Length : 217|9@1+ (0.05,0) [0|25.55] "m"  RadarFrontCenter
 SG_ VFC_Obj11A_HeadingAngle : 226|9@1+ (0.01,-1.57) [-1.57|1.57] "rad"  RadarFrontCenter
 SG_ VFC_Obj11A_NormAx : 235|13@1+ (0.002,-10) [-10|6] "1/s^2"  RadarFrontCenter
 SG_ VFC_Obj11A_NormVyEdgeLeftStdDev : 248|8@1+ (0.001,0) [0|0.255] "1/s"  RadarFrontCenter
 SG_ VFC_Obj11A_NormVyEdgeLeft : 256|13@1+ (0.001,-4) [-4|4] "1/s"  RadarFrontCenter
 SG_ VFC_Obj11A_EdgeBottom : 269|12@1+ (0.00025,-0.5) [-0.5|0.5] "unitless"  RadarFrontCenter
 SG_ VFC_Obj11A_NormVyEdgeRight : 281|13@1+ (0.001,-4) [-4|4] "1/s"  RadarFrontCenter
 SG_ VFC_Obj11A_Width : 294|10@1+ (0.01,0) [0|10.23] "m"  RadarFrontCenter
 SG_ VFC_Obj11A_NormVx : 304|16@1+ (0.001,-40) [-40|25] "1/s"  RadarFrontCenter
 SG_ VFC_Obj11A_NormVyEdgeRightStdDev : 320|8@1+ (0.001,0) [0|0.255] "1/s"  RadarFrontCenter
 SG_ VFC_Obj11A_NormAxStdDev : 328|10@1+ (0.0025,0) [0|2.5575] "1/s^2"  RadarFrontCenter
 SG_ VFC_Obj11A_ScaleChange : 338|14@1+ (0.0001,0.5) [0.5|2.1383] "unitless"  RadarFrontCenter
 SG_ VFC_Obj11A_ScaleChngStdDev : 352|10@1+ (0.0001,0) [0|0.1023] "unitless"  RadarFrontCenter
 SG_ VFC_Obj11A_Reliability : 362|6@1+ (1,0) [0|63] ""  RadarFrontCenter
 SG_ VFC_Obj11A_NormVxStdDev : 368|10@1+ (0.001,0) [0|1.023] "1/s"  RadarFrontCenter
 SG_ VFC_Obj11A_TypeProb : 378|6@1+ (2,0) [0|100] "%"  RadarFrontCenter
 SG_ VFC_Obj11A_LengthStdDev : 384|7@1+ (0.05,0) [0|5] "m"  RadarFrontCenter
 SG_ VFC_Obj11A_WidthStdDev : 391|7@1+ (0.01,0) [0|1] "m"  RadarFrontCenter
 SG_ VFC_Obj11A_EdgeMid : 398|13@1+ (0.00025,-1) [-1|1] "unitless"  RadarFrontCenter
 SG_ VFC_Obj11A_EdgeLeft : 411|13@1+ (0.00025,-1) [-1|1] "unitless"  RadarFrontCenter
 SG_ VFC_Obj11A_EdgeRight : 424|13@1+ (0.00025,-1) [-1|1] "unitless"  RadarFrontCenter
 SG_ VFC_Obj11A_VisibleView : 437|3@1+ (1,0) [0|4] ""  RadarFrontCenter
 SG_ VFC_Obj11A_EdgeLeftStdDev : 440|8@1+ (0.0002,0) [0|0.051] "unitless"  RadarFrontCenter
 SG_ VFC_Obj11A_EdgeTop : 448|12@1+ (0.00025,-0.5) [-0.5|0.5] "unitless"  RadarFrontCenter
 SG_ VFC_Obj11A_HeadOrientation : 460|4@1+ (1,0) [0|15] ""  RadarFrontCenter
 SG_ VFC_Obj11A_EdgeMidStdDev : 464|8@1+ (0.0002,0) [0|0.051] "unitless"  RadarFrontCenter
 SG_ VFC_Obj11A_EdgeRightStdDev : 472|8@1+ (0.0002,0) [0|0.051] "unitless"  RadarFrontCenter
 SG_ VFC_Obj11A_EdgeTopStdDev : 480|8@1+ (0.0002,0) [0|0.051] "unitless"  RadarFrontCenter
 SG_ VFC_Obj11A_EdgeBottomStdDev : 488|8@1+ (0.0002,0) [0|0.051] "unitless"  RadarFrontCenter
 SG_ VFC_Obj11A_ClassifiedView : 496|3@1+ (1,0) [0|4] ""  RadarFrontCenter

BO_ 66 VFC_Object12A: 64 VideoFrontCenter
 SG_ VFC_Obj12A_CRC : 0|16@1+ (1,0) [0|65535] ""  RadarFrontCenter
 SG_ VFC_Obj12A_AliveCtr : 16|8@1+ (1,0) [0|255] ""  RadarFrontCenter
 SG_ VFC_Obj12A_ProtBlockCtr : 24|4@1+ (1,0) [0|15] ""  RadarFrontCenter
 SG_ VFC_Obj12A_ID : 32|8@1+ (1,0) [1|255] ""  RadarFrontCenter
 SG_ VFC_Obj12A_AxStdDev : 40|8@1+ (0.1,0) [0|25.5] "m/s^2"  RadarFrontCenter
 SG_ VFC_Obj12A_Dx : 48|12@1+ (0.05,0) [0|204.75] "m"  RadarFrontCenter
 SG_ VFC_Obj12A_Type : 60|4@1+ (1,0) [0|15] ""  RadarFrontCenter
 SG_ VFC_Obj12A_Dy : 64|14@1+ (0.01,-80) [-80|80] "m"  RadarFrontCenter
 SG_ VFC_Obj12A_Measured : 78|2@1+ (1,0) [0|3] ""  RadarFrontCenter
 SG_ VFC_Obj12A_Vx : 80|11@1+ (0.1,-154) [-154|50] "m/s"  RadarFrontCenter
 SG_ VFC_Obj12A_MeasSource : 91|5@1+ (1,0) [0|31] ""  RadarFrontCenter
 SG_ VFC_Obj12A_Vy : 96|10@1+ (0.1,-50) [-50|50] "m/s"  RadarFrontCenter
 SG_ VFC_Obj12A_DirIndicator : 106|3@1+ (1,0) [0|4] ""  RadarFrontCenter
 SG_ VFC_Obj12A_BrakeLight : 109|3@1+ (1,0) [0|7] ""  RadarFrontCenter
 SG_ VFC_Obj12A_Ax : 112|9@1+ (0.1,-16) [-16|16] "m/s^2"  RadarFrontCenter
 SG_ VFC_Obj12A_CompletelyInImg : 121|1@1+ (1,0) [0|1] ""  RadarFrontCenter
 SG_ VFC_Obj12A_ProbExist : 122|6@1+ (2,0) [0|100] "%"  RadarFrontCenter
 SG_ VFC_Obj12A_Ay : 128|8@1+ (0.1,-12) [-12|12] "m/s^2"  RadarFrontCenter
 SG_ VFC_Obj12A_AyStdDev : 136|8@1+ (0.1,0) [0|25.5] "m/s^2"  RadarFrontCenter
 SG_ VFC_Obj12A_DxStdDev : 144|10@1+ (0.05,0) [0|51.15] "m"  RadarFrontCenter
 SG_ VFC_Obj12A_ProbMovingLat : 154|6@1+ (2,0) [0|100] "%"  RadarFrontCenter
 SG_ VFC_Obj12A_DyStdDev : 160|10@1+ (0.02,0) [0|20.46] "m"  RadarFrontCenter
 SG_ VFC_Obj12A_ProbMovingLong : 170|6@1+ (2,0) [0|100] "%"  RadarFrontCenter
 SG_ VFC_Obj12A_VxStdDev : 176|10@1+ (0.1,0) [0|102.3] "m/s"  RadarFrontCenter
 SG_ VFC_Obj12A_HeadingAngleStdDev : 186|6@1+ (0.01,0) [0|0.5] "rad"  RadarFrontCenter
 SG_ VFC_Obj12A_VyStdDev : 192|9@1+ (0.1,0) [0|51.1] "m/s"  RadarFrontCenter
 SG_ VFC_Obj12A_HeightStdDev : 201|7@1+ (0.01,0) [0|1] "m"  RadarFrontCenter
 SG_ VFC_Obj12A_Height : 208|9@1+ (0.01,0) [0|5.11] "m"  RadarFrontCenter
 SG_ VFC_Obj12A_Length : 217|9@1+ (0.05,0) [0|25.55] "m"  RadarFrontCenter
 SG_ VFC_Obj12A_HeadingAngle : 226|9@1+ (0.01,-1.57) [-1.57|1.57] "rad"  RadarFrontCenter
 SG_ VFC_Obj12A_NormAx : 235|13@1+ (0.002,-10) [-10|6] "1/s^2"  RadarFrontCenter
 SG_ VFC_Obj12A_NormVyEdgeLeftStdDev : 248|8@1+ (0.001,0) [0|0.255] "1/s"  RadarFrontCenter
 SG_ VFC_Obj12A_NormVyEdgeLeft : 256|13@1+ (0.001,-4) [-4|4] "1/s"  RadarFrontCenter
 SG_ VFC_Obj12A_EdgeBottom : 269|12@1+ (0.00025,-0.5) [-0.5|0.5] "unitless"  RadarFrontCenter
 SG_ VFC_Obj12A_NormVyEdgeRight : 281|13@1+ (0.001,-4) [-4|4] "1/s"  RadarFrontCenter
 SG_ VFC_Obj12A_Width : 294|10@1+ (0.01,0) [0|10.23] "m"  RadarFrontCenter
 SG_ VFC_Obj12A_NormVx : 304|16@1+ (0.001,-40) [-40|25] "1/s"  RadarFrontCenter
 SG_ VFC_Obj12A_NormVyEdgeRightStdDev : 320|8@1+ (0.001,0) [0|0.255] "1/s"  RadarFrontCenter
 SG_ VFC_Obj12A_NormAxStdDev : 328|10@1+ (0.0025,0) [0|2.5575] "1/s^2"  RadarFrontCenter
 SG_ VFC_Obj12A_ScaleChange : 338|14@1+ (0.0001,0.5) [0.5|2.1383] "unitless"  RadarFrontCenter
 SG_ VFC_Obj12A_ScaleChngStdDev : 352|10@1+ (0.0001,0) [0|0.1023] "unitless"  RadarFrontCenter
 SG_ VFC_Obj12A_Reliability : 362|6@1+ (1,0) [0|63] ""  RadarFrontCenter
 SG_ VFC_Obj12A_NormVxStdDev : 368|10@1+ (0.001,0) [0|1.023] "1/s"  RadarFrontCenter
 SG_ VFC_Obj12A_TypeProb : 378|6@1+ (2,0) [0|100] "%"  RadarFrontCenter
 SG_ VFC_Obj12A_LengthStdDev : 384|7@1+ (0.05,0) [0|5] "m"  RadarFrontCenter
 SG_ VFC_Obj12A_WidthStdDev : 391|7@1+ (0.01,0) [0|1] "m"  RadarFrontCenter
 SG_ VFC_Obj12A_EdgeMid : 398|13@1+ (0.00025,-1) [-1|1] "unitless"  RadarFrontCenter
 SG_ VFC_Obj12A_EdgeLeft : 411|13@1+ (0.00025,-1) [-1|1] "unitless"  RadarFrontCenter
 SG_ VFC_Obj12A_EdgeRight : 424|13@1+ (0.00025,-1) [-1|1] "unitless"  RadarFrontCenter
 SG_ VFC_Obj12A_VisibleView : 437|3@1+ (1,0) [0|4] ""  RadarFrontCenter
 SG_ VFC_Obj12A_EdgeLeftStdDev : 440|8@1+ (0.0002,0) [0|0.051] "unitless"  RadarFrontCenter
 SG_ VFC_Obj12A_EdgeTop : 448|12@1+ (0.00025,-0.5) [-0.5|0.5] "unitless"  RadarFrontCenter
 SG_ VFC_Obj12A_HeadOrientation : 460|4@1+ (1,0) [0|15] ""  RadarFrontCenter
 SG_ VFC_Obj12A_EdgeMidStdDev : 464|8@1+ (0.0002,0) [0|0.051] "unitless"  RadarFrontCenter
 SG_ VFC_Obj12A_EdgeRightStdDev : 472|8@1+ (0.0002,0) [0|0.051] "unitless"  RadarFrontCenter
 SG_ VFC_Obj12A_EdgeTopStdDev : 480|8@1+ (0.0002,0) [0|0.051] "unitless"  RadarFrontCenter
 SG_ VFC_Obj12A_EdgeBottomStdDev : 488|8@1+ (0.0002,0) [0|0.051] "unitless"  RadarFrontCenter
 SG_ VFC_Obj12A_ClassifiedView : 496|3@1+ (1,0) [0|4] ""  RadarFrontCenter

CM_ BO_ 3221225472 "This is a message for not used signals, created by Vector CANdb++ DBC OLE DB Provider.";
CM_ SG_ 3221225472 RFC_Status_CRC "CRC - E2E Profile decision by customer project. Possible options: AUTOSAR Profile 1A,1B,1C,2,11A,11C,22, OEM specified E2E profile (Platform proposal Profile 22)";
CM_ SG_ 3221225472 RFC_Status_AliveCtr "Alive counter - E2E Profile decision by customer project. Possible options: AUTOSAR Profile 1A,1B,1C,2,11A,11C,22, OEM specified E2E profile (Platform proposal Profile 22)";
CM_ SG_ 3221225472 RFC_Status_ModulationStatus "Reflect if there is any problem with the modulation of the radar";
CM_ SG_ 3221225472 RFC_Status_SensorStatus "Bit 0: HW MALFUNCTION
Bit 1: DSP ISSUES
Bit 2: COMMUNICATION ERRORS
Bit 3: MISALIGNMENT (OUT OF SPEC)
Bit 4: SENSOR BLIDNESS DETECTED
Bit 5: SENSOR DISTURBED
Bit 6: OTHER ISSUES
Bit 7: RESERVED
Value 0: no event
Value 1: event occured";
CM_ SG_ 16 VFC_AEB_CRC "CRC - E2E Profile decision by customer project. Possible options: AUTOSAR Profile 1A,1B,1C,2,11A,11C,22, OEM specified E2E profile (Platform proposal Profile 22)";
CM_ SG_ 16 VFC_AEB_AC "Alive Counter - E2E Profile decision by customer project. Possible options: AUTOSAR Profile 1A,1B,1C,2,11A,11C,22, OEM specified E2E profile (Platform proposal Profile 22)";
CM_ SG_ 16 VFC_AEB_FPC "Trigger recommendation of AEB FPC (Front Pre Crash)";
CM_ SG_ 16 VFC_AEB_CU "Trigger recommendations of AEB CU (CityUrban)
Bit 0 : AEB_CU_EMERGENCY_BRAKE 
Bit 1 : AEB_CU_WARNING
Bit 2 : AEB_CU_EBA_REACTION
Bit 3 : AEB_CU_PREFILL
Bit 4 : AEB_CU_HAPTIC
Bit 5 : AEB_CU_PARTIAL_BRAKE";
CM_ SG_ 16 VFC_AEB_VRU "Trigger recommendations of AEB VRU (Vulnerable Road User)
Bit 0 : AEB_VRU_EMERGENCY_BRAKE
Bit 1 : AEB_VRU_WARNINGÂ 
Bit 2 : AEB_VRU_PREFILL
Bit 3 : AEB_VRU_EBA_REACTION
Bit 4 : AEB_VRU_HAPTIC";
CM_ SG_ 16 VFC_AEB_VRUTA "Trigger recommendations of AEB VRUTA (Vulnerable Road User Turning Assist)
Bit 0 :  AEB_VRUTA_EMERGENCY_BRAKE
Bit 1 :  AEB_VRUTA_WARNING 
Bit 2 :  AEB_VRUTA_EBA_REACTION
Bit 3 :  AEB_VRUTA_PREFILL
Bit 4 :  AEB_VRUTA_HAPTIC";
CM_ SG_ 16 VFC_AEB_LTA "Trigger recommendations of AEB LTA (Left Turn Assist)
Bit 0 : AEB_LTA_EMERGENCY_BRAKE
Bit 1 : AEB_LTA_WARNING 
Bit 2 : AEB_LTA_EBA_REACTION
Bit 3 : AEB_LTA_PREFILL
Bit 4 : AEB_LTA_HAPTIC";
CM_ SG_ 16 VFC_AEB_ObjID "Object ID of AEB event";
CM_ SG_ 19 RFL_AEB_CRC "CRC - E2E Profile decision by customer project. Possible options: AUTOSAR Profile 1A,1B,1C,2,11A,11C,22, OEM specified E2E profile (Platform proposal Profile 22)";
CM_ SG_ 19 RFL_AEB_AC "Alive Counter - E2E Profile decision by customer project. Possible options: AUTOSAR Profile 1A,1B,1C,2,11A,11C,22, OEM specified E2E profile (Platform proposal Profile 22)";
CM_ SG_ 19 RFL_AEB_FPC "Trigger recommendation of AEB FPC (Front Pre Crash)";
CM_ SG_ 19 RFL_AEB_CU "Trigger recommendations of AEB CU (CityUrban)
Bit 0 : AEB_CU_EMERGENCY_BRAKE 
Bit 1 : AEB_CU_WARNING
Bit 2 : AEB_CU_EBA_REACTION
Bit 3 : AEB_CU_PREFILL
Bit 4 : AEB_CU_HAPTIC
Bit 5 : AEB_CU_PARTIAL_BRAKE";
CM_ SG_ 19 RFL_AEB_VRU "Trigger recommendations of AEB VRU (Vulnerable Road User)
Bit 0 : AEB_VRU_EMERGENCY_BRAKE
Bit 1 : AEB_VRU_WARNINGÂ 
Bit 2 : AEB_VRU_PREFILL
Bit 3 : AEB_VRU_EBA_REACTION
Bit 4 : AEB_VRU_HAPTIC";
CM_ SG_ 19 RFL_AEB_VRUTA "Trigger recommendations of AEB VRUTA (Vulnerable Road User Turning Assist)
Bit 0 :  AEB_VRUTA_EMERGENCY_BRAKE
Bit 1 :  AEB_VRUTA_WARNING 
Bit 2 :  AEB_VRUTA_EBA_REACTION
Bit 3 :  AEB_VRUTA_PREFILL
Bit 4 :  AEB_VRUTA_HAPTIC";
CM_ SG_ 19 RFL_AEB_LTA "Trigger recommendations of AEB LTA (Left Turn Assist)
Bit 0 : AEB_LTA_EMERGENCY_BRAKE
Bit 1 : AEB_LTA_WARNING 
Bit 2 : AEB_LTA_EBA_REACTION
Bit 3 : AEB_LTA_PREFILL
Bit 4 : AEB_LTA_HAPTIC";
CM_ SG_ 19 RFL_AEB_ObjID "Object ID of AEB event";
CM_ SG_ 20 RFR_AEB_CRC "CRC - E2E Profile decision by customer project. Possible options: AUTOSAR Profile 1A,1B,1C,2,11A,11C,22, OEM specified E2E profile (Platform proposal Profile 22)";
CM_ SG_ 20 RFR_AEB_AC "Alive Counter - E2E Profile decision by customer project. Possible options: AUTOSAR Profile 1A,1B,1C,2,11A,11C,22, OEM specified E2E profile (Platform proposal Profile 22)";
CM_ SG_ 20 RFR_AEB_FPC "Trigger recommendation of AEB FPC (Front Pre Crash)";
CM_ SG_ 20 RFR_AEB_CU "Trigger recommendations of AEB CU (CityUrban)
Bit 0 : AEB_CU_EMERGENCY_BRAKE 
Bit 1 : AEB_CU_WARNING
Bit 2 : AEB_CU_EBA_REACTION
Bit 3 : AEB_CU_PREFILL
Bit 4 : AEB_CU_HAPTIC
Bit 5 : AEB_CU_PARTIAL_BRAKE";
CM_ SG_ 20 RFR_AEB_VRU "Trigger recommendations of AEB VRU (Vulnerable Road User)
Bit 0 : AEB_VRU_EMERGENCY_BRAKE
Bit 1 : AEB_VRU_WARNINGÂ 
Bit 2 : AEB_VRU_PREFILL
Bit 3 : AEB_VRU_EBA_REACTION
Bit 4 : AEB_VRU_HAPTIC";
CM_ SG_ 20 RFR_AEB_VRUTA "Trigger recommendations of AEB VRUTA (Vulnerable Road User Turning Assist)
Bit 0 :  AEB_VRUTA_EMERGENCY_BRAKE
Bit 1 :  AEB_VRUTA_WARNING 
Bit 2 :  AEB_VRUTA_EBA_REACTION
Bit 3 :  AEB_VRUTA_PREFILL
Bit 4 :  AEB_VRUTA_HAPTIC";
CM_ SG_ 20 RFR_AEB_LTA "Trigger recommendations of AEB LTA (Left Turn Assist)
Bit 0 : AEB_LTA_EMERGENCY_BRAKE
Bit 1 : AEB_LTA_WARNING 
Bit 2 : AEB_LTA_EBA_REACTION
Bit 3 : AEB_LTA_PREFILL
Bit 4 : AEB_LTA_HAPTIC";
CM_ SG_ 20 RFR_AEB_ObjID "Object ID of AEB event";
CM_ SG_ 32 VFC_GlobalHdr_CRC "CRC - Autosar E2E Profile 5";
CM_ SG_ 32 VFC_GlobalHdr_AliveCtr "Alive counter - Autosar E2E Profile 5";
CM_ SG_ 32 VFC_GlobalHdr_ProtocolVersion "Protocol version to be send (BCD coded: Major.Minor): 0x0200 = V2.0";
CM_ SG_ 32 VFC_GlobalHdr_TrafficFlowType "ISO 23150:2022(E): Current traffic flow type (A.6.49)";
CM_ SG_ 32 VFC_GlobalHdr_TimeStampStatus "Autosar StbM_TimeBaseStatusType bitfield with extension:
Bit 0: TIMEOUT
Bit 1: Reserved1
Bit 2: SYNC_TO_GATEWAY
Bit 3: GLOBAL_TIME_BASE
Bit 4: TIMELEAP_FUTURE
Bit 5: TIMELEAP_PAST
Bit 6: Reserved6
Bit 7: Extension: GENERAL_ERROR";
CM_ SG_ 32 VFC_GlobalHdr_TimeStamp "TimeStamp of frame";
CM_ SG_ 32 VFC_GlobalHdr_SensorState "The current state of the camera system";
CM_ SG_ 32 VFC_GlobalHdr_DsmState "Function related system state, whether the function can be supported fully, in any degraded mode, init, etc.";
CM_ SG_ 32 VFC_GlobalHdr_CalibState "The calibration state of the camera system";
CM_ SG_ 32 VFC_GlobalHdr_StmState "HW related system state, whether all HW parts are running, in init or any other state";
CM_ SG_ 32 VFC_GlobalHdr_RollerBenchState "The state of the roller bench test mode";
CM_ SG_ 32 VFC_GlobalHdr_MountPosX "The current estimation of mounting position of the camera in the longitudinal direction";
CM_ SG_ 32 VFC_GlobalHdr_MountPosY "The current estimation of mounting position of the camera in the lateral direction";
CM_ SG_ 32 VFC_GlobalHdr_MountPosZ "The current estimation of mounting position of the camera in the vertical direction";
CM_ SG_ 32 VFC_GlobalHdr_CalibYawAngle "The calibrated yaw angle of the camera";
CM_ SG_ 32 VFC_GlobalHdr_CalibPitchAngle "The calibrated pitch angle of the camera";
CM_ SG_ 32 VFC_GlobalHdr_CalibRollAngle "The calibrated roll angle of the camera";
CM_ SG_ 32 VFC_GlobalHdr_SwVersion "SW version: 4 digits major version, 2 digits minor version";
CM_ SG_ 32 VFC_GlobalHdr_FrameNumber "The frame number that the data belongs to";
CM_ SG_ 35 RFL_Status_CRC "CRC - Autosar E2E Profile TBD";
CM_ SG_ 35 RFL_Status_AliveCtr "Alive counter - Autosar E2E Profile TBD";
CM_ SG_ 35 RFL_Status_SensorState "The sensor shall provide its operation state.
In case of multiple errors the most severe state shall be sent.
This signal is used for safety and time-out check purposes";
CM_ SG_ 35 RFL_Status_ModulationStatus "Reflect if there is any problem with the modulation of the radar";
CM_ SG_ 36 RFR_Status_CRC "CRC - Autosar E2E Profile TBD";
CM_ SG_ 36 RFR_Status_AliveCtr "Alive counter - Autosar E2E Profile TBD";
CM_ SG_ 36 RFR_Status_SensorState "The sensor shall provide its operation state.
In case of multiple errors the most severe state shall be sent.
This signal is used for safety and time-out check purposes";
CM_ SG_ 36 RFR_Status_ModulationStatus "Reflect if there is any problem with the modulation of the radar";
CM_ SG_ 52 VFC_ObjHdr_CRC "CRC - Autosar E2E Profile 5";
CM_ SG_ 52 VFC_ObjHdr_AliveCtr "Alive counter - Autosar E2E Profile 5";
CM_ SG_ 52 VFC_ObjHdr_ProtBlockCtr "Protocol-Signal: Block-Counter";
CM_ SG_ 52 VFC_ObjHdr_ProtObjCount "Protocol-Signal: count of all objects";
CM_ SG_ 52 VFC_ObjHdr_State "Informs the system of the current state of the camera";
CM_ SG_ 52 VFC_ObjHdr_TimeStampStatus "Autosar StbM_TimeBaseStatusType bitfield with extension:
Bit 0: TIMEOUT
Bit 1: Reserved1
Bit 2: SYNC_TO_GATEWAY
Bit 3: GLOBAL_TIME_BASE
Bit 4: TIMELEAP_FUTURE
Bit 5: TIMELEAP_PAST
Bit 6: Reserved6
Bit 7: Extension: GENERAL_ERROR";
CM_ SG_ 52 VFC_ObjHdr_TimeStamp "TimeStamp of Objects";
CM_ SG_ 54 VFC_Obj00A_CRC "CRC - Autosar E2E Profile 5";
CM_ SG_ 54 VFC_Obj00A_AliveCtr "Alive counter - Autosar E2E Profile 5";
CM_ SG_ 54 VFC_Obj00A_ProtBlockCtr "Protocol-Signal: Block-Counter";
CM_ SG_ 54 VFC_Obj00A_ID "Unique Object ID";
CM_ SG_ 54 VFC_Obj00A_AxStdDev "Standard deviation of Object acceleration in longitudinal direction";
CM_ SG_ 54 VFC_Obj00A_Dx "Object distance in longitudinal direction";
CM_ SG_ 54 VFC_Obj00A_Type "Classification of the object";
CM_ SG_ 54 VFC_Obj00A_Dy "Object distance in lateral direction";
CM_ SG_ 54 VFC_Obj00A_Measured "Indicator if the object detected is measured or predicted";
CM_ SG_ 54 VFC_Obj00A_Vx "Object velocity in longitudinal direction";
CM_ SG_ 54 VFC_Obj00A_MeasSource "Bitfield for the measurement programs from which this object originates
Bit 0: MOD
Bit 1: PDET
Bit 2: OFT
Bit 3: OLS
Bit 4: RESERVED";
CM_ SG_ 54 VFC_Obj00A_Vy "Object velocity in lateral direction";
CM_ SG_ 54 VFC_Obj00A_DirIndicator "The detected direction indicator lights";
CM_ SG_ 54 VFC_Obj00A_BrakeLight "The number of detected lights. More confident if more lights are detected.";
CM_ SG_ 54 VFC_Obj00A_Ax "Object acceleration in longitudinal direction";
CM_ SG_ 54 VFC_Obj00A_CompletelyInImg "indicator if the object is completely measured in the image";
CM_ SG_ 54 VFC_Obj00A_ProbExist "Object existence probability";
CM_ SG_ 54 VFC_Obj00A_Ay "Object acceleration in lateral direction";
CM_ SG_ 54 VFC_Obj00A_AyStdDev "Standard deviation of Object acceleration in lateral direction";
CM_ SG_ 54 VFC_Obj00A_DxStdDev "Standard deviation of Object distance in longitudinal direction";
CM_ SG_ 54 VFC_Obj00A_ProbMovingLat "Probability of object moving laterally";
CM_ SG_ 54 VFC_Obj00A_DyStdDev "Standard deviation of Object distance in lateral direction";
CM_ SG_ 54 VFC_Obj00A_ProbMovingLong "Probability of object moving longitudinally";
CM_ SG_ 54 VFC_Obj00A_VxStdDev "Standard deviation of Object velocity in longitudinal direction";
CM_ SG_ 54 VFC_Obj00A_HeadingAngleStdDev "Standard deviation of object Heading angle";
CM_ SG_ 54 VFC_Obj00A_VyStdDev "Standard deviation of Object velocity in lateral direction";
CM_ SG_ 54 VFC_Obj00A_HeightStdDev "Standard deviation of object height";
CM_ SG_ 54 VFC_Obj00A_Height "Height of the object";
CM_ SG_ 54 VFC_Obj00A_Length "Length of the object";
CM_ SG_ 54 VFC_Obj00A_HeadingAngle "Heading angle of the object";
CM_ SG_ 54 VFC_Obj00A_NormAx "Normalised Object acceleration in longitudinal direction";
CM_ SG_ 54 VFC_Obj00A_NormVyEdgeLeftStdDev "Standard deviation of Normalised velocity of the ACCS left object edge in lateral direction";
CM_ SG_ 54 VFC_Obj00A_NormVyEdgeLeft "Normalised velocity of the ACCS left object edge in lateral direction";
CM_ SG_ 54 VFC_Obj00A_EdgeBottom "In ACCS coordinates; corresponds to tan(viewing angle of bottom object edge)";
CM_ SG_ 54 VFC_Obj00A_NormVyEdgeRight "Normalised velocity of the ACCS right object edge in lateral direction";
CM_ SG_ 54 VFC_Obj00A_Width "Width of the object";
CM_ SG_ 54 VFC_Obj00A_NormVx "Normalised Object velocity in longitudinal direction";
CM_ SG_ 54 VFC_Obj00A_NormVyEdgeRightStdDev "Standard deviation of Normalised velocity of the ACCS right object edge in lateral direction";
CM_ SG_ 54 VFC_Obj00A_NormAxStdDev "Standard deviation of Normalised Object acceleration in longitudinal direction";
CM_ SG_ 54 VFC_Obj00A_ScaleChange "A scale change of of the detected object";
CM_ SG_ 54 VFC_Obj00A_ScaleChngStdDev "Standard deviation of object scale change";
CM_ SG_ 54 VFC_Obj00A_Reliability "The bitfield shows if the signal quality is assumed to be sufficient for functions with safety target -no false positives-
Bit 0: DYNAMIC
Bit 1: SEMSEG_SURFACE
Bit 2: WDD_CRITICAL
Bit 3: GOD_CONFIRMED
Bit 4: RESTRICTED
Bit 5: ISO26262_SAFE";
CM_ SG_ 54 VFC_Obj00A_NormVxStdDev "Standard deviation of Normalised Object velocity in longitudinal direction";
CM_ SG_ 54 VFC_Obj00A_TypeProb "Probability of the classified object type";
CM_ SG_ 54 VFC_Obj00A_LengthStdDev "Standard deviation of object length";
CM_ SG_ 54 VFC_Obj00A_WidthStdDev "Standard deviation of object width";
CM_ SG_ 54 VFC_Obj00A_EdgeMid "In ACCS coordinates; corresponds to tan(viewing angle of middle object edge)";
CM_ SG_ 54 VFC_Obj00A_EdgeLeft "In ACCS coordinates; corresponds to tan(viewing angle of left object edge)";
CM_ SG_ 54 VFC_Obj00A_EdgeRight "In ACCS coordinates; corresponds to tan(viewing angle of right object edge)";
CM_ SG_ 54 VFC_Obj00A_VisibleView "The visible view of the detected object";
CM_ SG_ 54 VFC_Obj00A_EdgeLeftStdDev "Standard deviation of the ACCS left object edge";
CM_ SG_ 54 VFC_Obj00A_EdgeTop "In ACCS coordinates; corresponds to tan(viewing angle of top object edge)";
CM_ SG_ 54 VFC_Obj00A_HeadOrientation "The orientation of the head of cyclists or pedestrians that are detected";
CM_ SG_ 54 VFC_Obj00A_EdgeMidStdDev "Standard deviation of the ACCS middle object edge";
CM_ SG_ 54 VFC_Obj00A_EdgeRightStdDev "Standard deviation of the ACCS right object edge";
CM_ SG_ 54 VFC_Obj00A_EdgeTopStdDev "Standard deviation of the ACCS top object edge";
CM_ SG_ 54 VFC_Obj00A_EdgeBottomStdDev "Standard deviation of the ACCS bottom object edge";
CM_ SG_ 54 VFC_Obj00A_ClassifiedView "The classified view of object to be used in connection with Heading angle";
CM_ SG_ 55 VFC_Obj01A_CRC "CRC - Autosar E2E Profile 5";
CM_ SG_ 55 VFC_Obj01A_AliveCtr "Alive counter - Autosar E2E Profile 5";
CM_ SG_ 55 VFC_Obj01A_ProtBlockCtr "Protocol-Signal: Block-Counter";
CM_ SG_ 55 VFC_Obj01A_ID "Unique Object ID";
CM_ SG_ 55 VFC_Obj01A_AxStdDev "Standard deviation of Object acceleration in longitudinal direction";
CM_ SG_ 55 VFC_Obj01A_Dx "Object distance in longitudinal direction";
CM_ SG_ 55 VFC_Obj01A_Type "Classification of the object";
CM_ SG_ 55 VFC_Obj01A_Dy "Object distance in lateral direction";
CM_ SG_ 55 VFC_Obj01A_Measured "Indicator if the object detected is measured or predicted";
CM_ SG_ 55 VFC_Obj01A_Vx "Object velocity in longitudinal direction";
CM_ SG_ 55 VFC_Obj01A_MeasSource "Bitfield for the measurement programs from which this object originates
Bit 0: MOD
Bit 1: PDET
Bit 2: OFT
Bit 3: OLS
Bit 4: RESERVED";
CM_ SG_ 55 VFC_Obj01A_Vy "Object velocity in lateral direction";
CM_ SG_ 55 VFC_Obj01A_DirIndicator "The detected direction indicator lights";
CM_ SG_ 55 VFC_Obj01A_BrakeLight "The number of detected lights. More confident if more lights are detected.";
CM_ SG_ 55 VFC_Obj01A_Ax "Object acceleration in longitudinal direction";
CM_ SG_ 55 VFC_Obj01A_CompletelyInImg "indicator if the object is completely measured in the image";
CM_ SG_ 55 VFC_Obj01A_ProbExist "Object existence probability";
CM_ SG_ 55 VFC_Obj01A_Ay "Object acceleration in lateral direction";
CM_ SG_ 55 VFC_Obj01A_AyStdDev "Standard deviation of Object acceleration in lateral direction";
CM_ SG_ 55 VFC_Obj01A_DxStdDev "Standard deviation of Object distance in longitudinal direction";
CM_ SG_ 55 VFC_Obj01A_ProbMovingLat "Probability of object moving laterally";
CM_ SG_ 55 VFC_Obj01A_DyStdDev "Standard deviation of Object distance in lateral direction";
CM_ SG_ 55 VFC_Obj01A_ProbMovingLong "Probability of object moving longitudinally";
CM_ SG_ 55 VFC_Obj01A_VxStdDev "Standard deviation of Object velocity in longitudinal direction";
CM_ SG_ 55 VFC_Obj01A_HeadingAngleStdDev "Standard deviation of object Heading angle";
CM_ SG_ 55 VFC_Obj01A_VyStdDev "Standard deviation of Object velocity in lateral direction";
CM_ SG_ 55 VFC_Obj01A_HeightStdDev "Standard deviation of object height";
CM_ SG_ 55 VFC_Obj01A_Height "Height of the object";
CM_ SG_ 55 VFC_Obj01A_Length "Length of the object";
CM_ SG_ 55 VFC_Obj01A_HeadingAngle "Heading angle of the object";
CM_ SG_ 55 VFC_Obj01A_NormAx "Normalised Object acceleration in longitudinal direction";
CM_ SG_ 55 VFC_Obj01A_NormVyEdgeLeftStdDev "Standard deviation of Normalised velocity of the ACCS left object edge in lateral direction";
CM_ SG_ 55 VFC_Obj01A_NormVyEdgeLeft "Normalised velocity of the ACCS left object edge in lateral direction";
CM_ SG_ 55 VFC_Obj01A_EdgeBottom "In ACCS coordinates; corresponds to tan(viewing angle of bottom object edge)";
CM_ SG_ 55 VFC_Obj01A_NormVyEdgeRight "Normalised velocity of the ACCS right object edge in lateral direction";
CM_ SG_ 55 VFC_Obj01A_Width "Width of the object";
CM_ SG_ 55 VFC_Obj01A_NormVx "Normalised Object velocity in longitudinal direction";
CM_ SG_ 55 VFC_Obj01A_NormVyEdgeRightStdDev "Standard deviation of Normalised velocity of the ACCS right object edge in lateral direction";
CM_ SG_ 55 VFC_Obj01A_NormAxStdDev "Standard deviation of Normalised Object acceleration in longitudinal direction";
CM_ SG_ 55 VFC_Obj01A_ScaleChange "A scale change of of the detected object";
CM_ SG_ 55 VFC_Obj01A_ScaleChngStdDev "Standard deviation of object scale change";
CM_ SG_ 55 VFC_Obj01A_Reliability "The bitfield shows if the signal quality is assumed to be sufficient for functions with safety target -no false positives-
Bit 0: DYNAMIC
Bit 1: SEMSEG_SURFACE
Bit 2: WDD_CRITICAL
Bit 3: GOD_CONFIRMED
Bit 4: RESTRICTED
Bit 5: ISO26262_SAFE";
CM_ SG_ 55 VFC_Obj01A_NormVxStdDev "Standard deviation of Normalised Object velocity in longitudinal direction";
CM_ SG_ 55 VFC_Obj01A_TypeProb "Probability of the classified object type";
CM_ SG_ 55 VFC_Obj01A_LengthStdDev "Standard deviation of object length";
CM_ SG_ 55 VFC_Obj01A_WidthStdDev "Standard deviation of object width";
CM_ SG_ 55 VFC_Obj01A_EdgeMid "In ACCS coordinates; corresponds to tan(viewing angle of middle object edge)";
CM_ SG_ 55 VFC_Obj01A_EdgeLeft "In ACCS coordinates; corresponds to tan(viewing angle of left object edge)";
CM_ SG_ 55 VFC_Obj01A_EdgeRight "In ACCS coordinates; corresponds to tan(viewing angle of right object edge)";
CM_ SG_ 55 VFC_Obj01A_VisibleView "The visible view of the detected object";
CM_ SG_ 55 VFC_Obj01A_EdgeLeftStdDev "Standard deviation of the ACCS left object edge";
CM_ SG_ 55 VFC_Obj01A_EdgeTop "In ACCS coordinates; corresponds to tan(viewing angle of top object edge)";
CM_ SG_ 55 VFC_Obj01A_HeadOrientation "The orientation of the head of cyclists or pedestrians that are detected";
CM_ SG_ 55 VFC_Obj01A_EdgeMidStdDev "Standard deviation of the ACCS middle object edge";
CM_ SG_ 55 VFC_Obj01A_EdgeRightStdDev "Standard deviation of the ACCS right object edge";
CM_ SG_ 55 VFC_Obj01A_EdgeTopStdDev "Standard deviation of the ACCS top object edge";
CM_ SG_ 55 VFC_Obj01A_EdgeBottomStdDev "Standard deviation of the ACCS bottom object edge";
CM_ SG_ 55 VFC_Obj01A_ClassifiedView "The classified view of object to be used in connection with Heading angle";
CM_ SG_ 56 VFC_Obj02A_CRC "CRC - Autosar E2E Profile 5";
CM_ SG_ 56 VFC_Obj02A_AliveCtr "Alive counter - Autosar E2E Profile 5";
CM_ SG_ 56 VFC_Obj02A_ProtBlockCtr "Protocol-Signal: Block-Counter";
CM_ SG_ 56 VFC_Obj02A_ID "Unique Object ID";
CM_ SG_ 56 VFC_Obj02A_AxStdDev "Standard deviation of Object acceleration in longitudinal direction";
CM_ SG_ 56 VFC_Obj02A_Dx "Object distance in longitudinal direction";
CM_ SG_ 56 VFC_Obj02A_Type "Classification of the object";
CM_ SG_ 56 VFC_Obj02A_Dy "Object distance in lateral direction";
CM_ SG_ 56 VFC_Obj02A_Measured "Indicator if the object detected is measured or predicted";
CM_ SG_ 56 VFC_Obj02A_Vx "Object velocity in longitudinal direction";
CM_ SG_ 56 VFC_Obj02A_MeasSource "Bitfield for the measurement programs from which this object originates
Bit 0: MOD
Bit 1: PDET
Bit 2: OFT
Bit 3: OLS
Bit 4: RESERVED";
CM_ SG_ 56 VFC_Obj02A_Vy "Object velocity in lateral direction";
CM_ SG_ 56 VFC_Obj02A_DirIndicator "The detected direction indicator lights";
CM_ SG_ 56 VFC_Obj02A_BrakeLight "The number of detected lights. More confident if more lights are detected.";
CM_ SG_ 56 VFC_Obj02A_Ax "Object acceleration in longitudinal direction";
CM_ SG_ 56 VFC_Obj02A_CompletelyInImg "indicator if the object is completely measured in the image";
CM_ SG_ 56 VFC_Obj02A_ProbExist "Object existence probability";
CM_ SG_ 56 VFC_Obj02A_Ay "Object acceleration in lateral direction";
CM_ SG_ 56 VFC_Obj02A_AyStdDev "Standard deviation of Object acceleration in lateral direction";
CM_ SG_ 56 VFC_Obj02A_DxStdDev "Standard deviation of Object distance in longitudinal direction";
CM_ SG_ 56 VFC_Obj02A_ProbMovingLat "Probability of object moving laterally";
CM_ SG_ 56 VFC_Obj02A_DyStdDev "Standard deviation of Object distance in lateral direction";
CM_ SG_ 56 VFC_Obj02A_ProbMovingLong "Probability of object moving longitudinally";
CM_ SG_ 56 VFC_Obj02A_VxStdDev "Standard deviation of Object velocity in longitudinal direction";
CM_ SG_ 56 VFC_Obj02A_HeadingAngleStdDev "Standard deviation of object Heading angle";
CM_ SG_ 56 VFC_Obj02A_VyStdDev "Standard deviation of Object velocity in lateral direction";
CM_ SG_ 56 VFC_Obj02A_HeightStdDev "Standard deviation of object height";
CM_ SG_ 56 VFC_Obj02A_Height "Height of the object";
CM_ SG_ 56 VFC_Obj02A_Length "Length of the object";
CM_ SG_ 56 VFC_Obj02A_HeadingAngle "Heading angle of the object";
CM_ SG_ 56 VFC_Obj02A_NormAx "Normalised Object acceleration in longitudinal direction";
CM_ SG_ 56 VFC_Obj02A_NormVyEdgeLeftStdDev "Standard deviation of Normalised velocity of the ACCS left object edge in lateral direction";
CM_ SG_ 56 VFC_Obj02A_NormVyEdgeLeft "Normalised velocity of the ACCS left object edge in lateral direction";
CM_ SG_ 56 VFC_Obj02A_EdgeBottom "In ACCS coordinates; corresponds to tan(viewing angle of bottom object edge)";
CM_ SG_ 56 VFC_Obj02A_NormVyEdgeRight "Normalised velocity of the ACCS right object edge in lateral direction";
CM_ SG_ 56 VFC_Obj02A_Width "Width of the object";
CM_ SG_ 56 VFC_Obj02A_NormVx "Normalised Object velocity in longitudinal direction";
CM_ SG_ 56 VFC_Obj02A_NormVyEdgeRightStdDev "Standard deviation of Normalised velocity of the ACCS right object edge in lateral direction";
CM_ SG_ 56 VFC_Obj02A_NormAxStdDev "Standard deviation of Normalised Object acceleration in longitudinal direction";
CM_ SG_ 56 VFC_Obj02A_ScaleChange "A scale change of of the detected object";
CM_ SG_ 56 VFC_Obj02A_ScaleChngStdDev "Standard deviation of object scale change";
CM_ SG_ 56 VFC_Obj02A_Reliability "The bitfield shows if the signal quality is assumed to be sufficient for functions with safety target -no false positives-
Bit 0: DYNAMIC
Bit 1: SEMSEG_SURFACE
Bit 2: WDD_CRITICAL
Bit 3: GOD_CONFIRMED
Bit 4: RESTRICTED
Bit 5: ISO26262_SAFE";
CM_ SG_ 56 VFC_Obj02A_NormVxStdDev "Standard deviation of Normalised Object velocity in longitudinal direction";
CM_ SG_ 56 VFC_Obj02A_TypeProb "Probability of the classified object type";
CM_ SG_ 56 VFC_Obj02A_LengthStdDev "Standard deviation of object length";
CM_ SG_ 56 VFC_Obj02A_WidthStdDev "Standard deviation of object width";
CM_ SG_ 56 VFC_Obj02A_EdgeMid "In ACCS coordinates; corresponds to tan(viewing angle of middle object edge)";
CM_ SG_ 56 VFC_Obj02A_EdgeLeft "In ACCS coordinates; corresponds to tan(viewing angle of left object edge)";
CM_ SG_ 56 VFC_Obj02A_EdgeRight "In ACCS coordinates; corresponds to tan(viewing angle of right object edge)";
CM_ SG_ 56 VFC_Obj02A_VisibleView "The visible view of the detected object";
CM_ SG_ 56 VFC_Obj02A_EdgeLeftStdDev "Standard deviation of the ACCS left object edge";
CM_ SG_ 56 VFC_Obj02A_EdgeTop "In ACCS coordinates; corresponds to tan(viewing angle of top object edge)";
CM_ SG_ 56 VFC_Obj02A_HeadOrientation "The orientation of the head of cyclists or pedestrians that are detected";
CM_ SG_ 56 VFC_Obj02A_EdgeMidStdDev "Standard deviation of the ACCS middle object edge";
CM_ SG_ 56 VFC_Obj02A_EdgeRightStdDev "Standard deviation of the ACCS right object edge";
CM_ SG_ 56 VFC_Obj02A_EdgeTopStdDev "Standard deviation of the ACCS top object edge";
CM_ SG_ 56 VFC_Obj02A_EdgeBottomStdDev "Standard deviation of the ACCS bottom object edge";
CM_ SG_ 56 VFC_Obj02A_ClassifiedView "The classified view of object to be used in connection with Heading angle";
CM_ SG_ 57 VFC_Obj03A_CRC "CRC - Autosar E2E Profile 5";
CM_ SG_ 57 VFC_Obj03A_AliveCtr "Alive counter - Autosar E2E Profile 5";
CM_ SG_ 57 VFC_Obj03A_ProtBlockCtr "Protocol-Signal: Block-Counter";
CM_ SG_ 57 VFC_Obj03A_ID "Unique Object ID";
CM_ SG_ 57 VFC_Obj03A_AxStdDev "Standard deviation of Object acceleration in longitudinal direction";
CM_ SG_ 57 VFC_Obj03A_Dx "Object distance in longitudinal direction";
CM_ SG_ 57 VFC_Obj03A_Type "Classification of the object";
CM_ SG_ 57 VFC_Obj03A_Dy "Object distance in lateral direction";
CM_ SG_ 57 VFC_Obj03A_Measured "Indicator if the object detected is measured or predicted";
CM_ SG_ 57 VFC_Obj03A_Vx "Object velocity in longitudinal direction";
CM_ SG_ 57 VFC_Obj03A_MeasSource "Bitfield for the measurement programs from which this object originates
Bit 0: MOD
Bit 1: PDET
Bit 2: OFT
Bit 3: OLS
Bit 4: RESERVED";
CM_ SG_ 57 VFC_Obj03A_Vy "Object velocity in lateral direction";
CM_ SG_ 57 VFC_Obj03A_DirIndicator "The detected direction indicator lights";
CM_ SG_ 57 VFC_Obj03A_BrakeLight "The number of detected lights. More confident if more lights are detected.";
CM_ SG_ 57 VFC_Obj03A_Ax "Object acceleration in longitudinal direction";
CM_ SG_ 57 VFC_Obj03A_CompletelyInImg "indicator if the object is completely measured in the image";
CM_ SG_ 57 VFC_Obj03A_ProbExist "Object existence probability";
CM_ SG_ 57 VFC_Obj03A_Ay "Object acceleration in lateral direction";
CM_ SG_ 57 VFC_Obj03A_AyStdDev "Standard deviation of Object acceleration in lateral direction";
CM_ SG_ 57 VFC_Obj03A_DxStdDev "Standard deviation of Object distance in longitudinal direction";
CM_ SG_ 57 VFC_Obj03A_ProbMovingLat "Probability of object moving laterally";
CM_ SG_ 57 VFC_Obj03A_DyStdDev "Standard deviation of Object distance in lateral direction";
CM_ SG_ 57 VFC_Obj03A_ProbMovingLong "Probability of object moving longitudinally";
CM_ SG_ 57 VFC_Obj03A_VxStdDev "Standard deviation of Object velocity in longitudinal direction";
CM_ SG_ 57 VFC_Obj03A_HeadingAngleStdDev "Standard deviation of object Heading angle";
CM_ SG_ 57 VFC_Obj03A_VyStdDev "Standard deviation of Object velocity in lateral direction";
CM_ SG_ 57 VFC_Obj03A_HeightStdDev "Standard deviation of object height";
CM_ SG_ 57 VFC_Obj03A_Height "Height of the object";
CM_ SG_ 57 VFC_Obj03A_Length "Length of the object";
CM_ SG_ 57 VFC_Obj03A_HeadingAngle "Heading angle of the object";
CM_ SG_ 57 VFC_Obj03A_NormAx "Normalised Object acceleration in longitudinal direction";
CM_ SG_ 57 VFC_Obj03A_NormVyEdgeLeftStdDev "Standard deviation of Normalised velocity of the ACCS left object edge in lateral direction";
CM_ SG_ 57 VFC_Obj03A_NormVyEdgeLeft "Normalised velocity of the ACCS left object edge in lateral direction";
CM_ SG_ 57 VFC_Obj03A_EdgeBottom "In ACCS coordinates; corresponds to tan(viewing angle of bottom object edge)";
CM_ SG_ 57 VFC_Obj03A_NormVyEdgeRight "Normalised velocity of the ACCS right object edge in lateral direction";
CM_ SG_ 57 VFC_Obj03A_Width "Width of the object";
CM_ SG_ 57 VFC_Obj03A_NormVx "Normalised Object velocity in longitudinal direction";
CM_ SG_ 57 VFC_Obj03A_NormVyEdgeRightStdDev "Standard deviation of Normalised velocity of the ACCS right object edge in lateral direction";
CM_ SG_ 57 VFC_Obj03A_NormAxStdDev "Standard deviation of Normalised Object acceleration in longitudinal direction";
CM_ SG_ 57 VFC_Obj03A_ScaleChange "A scale change of of the detected object";
CM_ SG_ 57 VFC_Obj03A_ScaleChngStdDev "Standard deviation of object scale change";
CM_ SG_ 57 VFC_Obj03A_Reliability "The bitfield shows if the signal quality is assumed to be sufficient for functions with safety target -no false positives-
Bit 0: DYNAMIC
Bit 1: SEMSEG_SURFACE
Bit 2: WDD_CRITICAL
Bit 3: GOD_CONFIRMED
Bit 4: RESTRICTED
Bit 5: ISO26262_SAFE";
CM_ SG_ 57 VFC_Obj03A_NormVxStdDev "Standard deviation of Normalised Object velocity in longitudinal direction";
CM_ SG_ 57 VFC_Obj03A_TypeProb "Probability of the classified object type";
CM_ SG_ 57 VFC_Obj03A_LengthStdDev "Standard deviation of object length";
CM_ SG_ 57 VFC_Obj03A_WidthStdDev "Standard deviation of object width";
CM_ SG_ 57 VFC_Obj03A_EdgeMid "In ACCS coordinates; corresponds to tan(viewing angle of middle object edge)";
CM_ SG_ 57 VFC_Obj03A_EdgeLeft "In ACCS coordinates; corresponds to tan(viewing angle of left object edge)";
CM_ SG_ 57 VFC_Obj03A_EdgeRight "In ACCS coordinates; corresponds to tan(viewing angle of right object edge)";
CM_ SG_ 57 VFC_Obj03A_VisibleView "The visible view of the detected object";
CM_ SG_ 57 VFC_Obj03A_EdgeLeftStdDev "Standard deviation of the ACCS left object edge";
CM_ SG_ 57 VFC_Obj03A_EdgeTop "In ACCS coordinates; corresponds to tan(viewing angle of top object edge)";
CM_ SG_ 57 VFC_Obj03A_HeadOrientation "The orientation of the head of cyclists or pedestrians that are detected";
CM_ SG_ 57 VFC_Obj03A_EdgeMidStdDev "Standard deviation of the ACCS middle object edge";
CM_ SG_ 57 VFC_Obj03A_EdgeRightStdDev "Standard deviation of the ACCS right object edge";
CM_ SG_ 57 VFC_Obj03A_EdgeTopStdDev "Standard deviation of the ACCS top object edge";
CM_ SG_ 57 VFC_Obj03A_EdgeBottomStdDev "Standard deviation of the ACCS bottom object edge";
CM_ SG_ 57 VFC_Obj03A_ClassifiedView "The classified view of object to be used in connection with Heading angle";
CM_ SG_ 58 VFC_Obj04A_CRC "CRC - Autosar E2E Profile 5";
CM_ SG_ 58 VFC_Obj04A_AliveCtr "Alive counter - Autosar E2E Profile 5";
CM_ SG_ 58 VFC_Obj04A_ProtBlockCtr "Protocol-Signal: Block-Counter";
CM_ SG_ 58 VFC_Obj04A_ID "Unique Object ID";
CM_ SG_ 58 VFC_Obj04A_AxStdDev "Standard deviation of Object acceleration in longitudinal direction";
CM_ SG_ 58 VFC_Obj04A_Dx "Object distance in longitudinal direction";
CM_ SG_ 58 VFC_Obj04A_Type "Classification of the object";
CM_ SG_ 58 VFC_Obj04A_Dy "Object distance in lateral direction";
CM_ SG_ 58 VFC_Obj04A_Measured "Indicator if the object detected is measured or predicted";
CM_ SG_ 58 VFC_Obj04A_Vx "Object velocity in longitudinal direction";
CM_ SG_ 58 VFC_Obj04A_MeasSource "Bitfield for the measurement programs from which this object originates
Bit 0: MOD
Bit 1: PDET
Bit 2: OFT
Bit 3: OLS
Bit 4: RESERVED";
CM_ SG_ 58 VFC_Obj04A_Vy "Object velocity in lateral direction";
CM_ SG_ 58 VFC_Obj04A_DirIndicator "The detected direction indicator lights";
CM_ SG_ 58 VFC_Obj04A_BrakeLight "The number of detected lights. More confident if more lights are detected.";
CM_ SG_ 58 VFC_Obj04A_Ax "Object acceleration in longitudinal direction";
CM_ SG_ 58 VFC_Obj04A_CompletelyInImg "indicator if the object is completely measured in the image";
CM_ SG_ 58 VFC_Obj04A_ProbExist "Object existence probability";
CM_ SG_ 58 VFC_Obj04A_Ay "Object acceleration in lateral direction";
CM_ SG_ 58 VFC_Obj04A_AyStdDev "Standard deviation of Object acceleration in lateral direction";
CM_ SG_ 58 VFC_Obj04A_DxStdDev "Standard deviation of Object distance in longitudinal direction";
CM_ SG_ 58 VFC_Obj04A_ProbMovingLat "Probability of object moving laterally";
CM_ SG_ 58 VFC_Obj04A_DyStdDev "Standard deviation of Object distance in lateral direction";
CM_ SG_ 58 VFC_Obj04A_ProbMovingLong "Probability of object moving longitudinally";
CM_ SG_ 58 VFC_Obj04A_VxStdDev "Standard deviation of Object velocity in longitudinal direction";
CM_ SG_ 58 VFC_Obj04A_HeadingAngleStdDev "Standard deviation of object Heading angle";
CM_ SG_ 58 VFC_Obj04A_VyStdDev "Standard deviation of Object velocity in lateral direction";
CM_ SG_ 58 VFC_Obj04A_HeightStdDev "Standard deviation of object height";
CM_ SG_ 58 VFC_Obj04A_Height "Height of the object";
CM_ SG_ 58 VFC_Obj04A_Length "Length of the object";
CM_ SG_ 58 VFC_Obj04A_HeadingAngle "Heading angle of the object";
CM_ SG_ 58 VFC_Obj04A_NormAx "Normalised Object acceleration in longitudinal direction";
CM_ SG_ 58 VFC_Obj04A_NormVyEdgeLeftStdDev "Standard deviation of Normalised velocity of the ACCS left object edge in lateral direction";
CM_ SG_ 58 VFC_Obj04A_NormVyEdgeLeft "Normalised velocity of the ACCS left object edge in lateral direction";
CM_ SG_ 58 VFC_Obj04A_EdgeBottom "In ACCS coordinates; corresponds to tan(viewing angle of bottom object edge)";
CM_ SG_ 58 VFC_Obj04A_NormVyEdgeRight "Normalised velocity of the ACCS right object edge in lateral direction";
CM_ SG_ 58 VFC_Obj04A_Width "Width of the object";
CM_ SG_ 58 VFC_Obj04A_NormVx "Normalised Object velocity in longitudinal direction";
CM_ SG_ 58 VFC_Obj04A_NormVyEdgeRightStdDev "Standard deviation of Normalised velocity of the ACCS right object edge in lateral direction";
CM_ SG_ 58 VFC_Obj04A_NormAxStdDev "Standard deviation of Normalised Object acceleration in longitudinal direction";
CM_ SG_ 58 VFC_Obj04A_ScaleChange "A scale change of of the detected object";
CM_ SG_ 58 VFC_Obj04A_ScaleChngStdDev "Standard deviation of object scale change";
CM_ SG_ 58 VFC_Obj04A_Reliability "The bitfield shows if the signal quality is assumed to be sufficient for functions with safety target -no false positives-
Bit 0: DYNAMIC
Bit 1: SEMSEG_SURFACE
Bit 2: WDD_CRITICAL
Bit 3: GOD_CONFIRMED
Bit 4: RESTRICTED
Bit 5: ISO26262_SAFE";
CM_ SG_ 58 VFC_Obj04A_NormVxStdDev "Standard deviation of Normalised Object velocity in longitudinal direction";
CM_ SG_ 58 VFC_Obj04A_TypeProb "Probability of the classified object type";
CM_ SG_ 58 VFC_Obj04A_LengthStdDev "Standard deviation of object length";
CM_ SG_ 58 VFC_Obj04A_WidthStdDev "Standard deviation of object width";
CM_ SG_ 58 VFC_Obj04A_EdgeMid "In ACCS coordinates; corresponds to tan(viewing angle of middle object edge)";
CM_ SG_ 58 VFC_Obj04A_EdgeLeft "In ACCS coordinates; corresponds to tan(viewing angle of left object edge)";
CM_ SG_ 58 VFC_Obj04A_EdgeRight "In ACCS coordinates; corresponds to tan(viewing angle of right object edge)";
CM_ SG_ 58 VFC_Obj04A_VisibleView "The visible view of the detected object";
CM_ SG_ 58 VFC_Obj04A_EdgeLeftStdDev "Standard deviation of the ACCS left object edge";
CM_ SG_ 58 VFC_Obj04A_EdgeTop "In ACCS coordinates; corresponds to tan(viewing angle of top object edge)";
CM_ SG_ 58 VFC_Obj04A_HeadOrientation "The orientation of the head of cyclists or pedestrians that are detected";
CM_ SG_ 58 VFC_Obj04A_EdgeMidStdDev "Standard deviation of the ACCS middle object edge";
CM_ SG_ 58 VFC_Obj04A_EdgeRightStdDev "Standard deviation of the ACCS right object edge";
CM_ SG_ 58 VFC_Obj04A_EdgeTopStdDev "Standard deviation of the ACCS top object edge";
CM_ SG_ 58 VFC_Obj04A_EdgeBottomStdDev "Standard deviation of the ACCS bottom object edge";
CM_ SG_ 58 VFC_Obj04A_ClassifiedView "The classified view of object to be used in connection with Heading angle";
CM_ SG_ 59 VFC_Obj05A_CRC "CRC - Autosar E2E Profile 5";
CM_ SG_ 59 VFC_Obj05A_AliveCtr "Alive counter - Autosar E2E Profile 5";
CM_ SG_ 59 VFC_Obj05A_ProtBlockCtr "Protocol-Signal: Block-Counter";
CM_ SG_ 59 VFC_Obj05A_ID "Unique Object ID";
CM_ SG_ 59 VFC_Obj05A_AxStdDev "Standard deviation of Object acceleration in longitudinal direction";
CM_ SG_ 59 VFC_Obj05A_Dx "Object distance in longitudinal direction";
CM_ SG_ 59 VFC_Obj05A_Type "Classification of the object";
CM_ SG_ 59 VFC_Obj05A_Dy "Object distance in lateral direction";
CM_ SG_ 59 VFC_Obj05A_Measured "Indicator if the object detected is measured or predicted";
CM_ SG_ 59 VFC_Obj05A_Vx "Object velocity in longitudinal direction";
CM_ SG_ 59 VFC_Obj05A_MeasSource "Bitfield for the measurement programs from which this object originates
Bit 0: MOD
Bit 1: PDET
Bit 2: OFT
Bit 3: OLS
Bit 4: RESERVED";
CM_ SG_ 59 VFC_Obj05A_Vy "Object velocity in lateral direction";
CM_ SG_ 59 VFC_Obj05A_DirIndicator "The detected direction indicator lights";
CM_ SG_ 59 VFC_Obj05A_BrakeLight "The number of detected lights. More confident if more lights are detected.";
CM_ SG_ 59 VFC_Obj05A_Ax "Object acceleration in longitudinal direction";
CM_ SG_ 59 VFC_Obj05A_CompletelyInImg "indicator if the object is completely measured in the image";
CM_ SG_ 59 VFC_Obj05A_ProbExist "Object existence probability";
CM_ SG_ 59 VFC_Obj05A_Ay "Object acceleration in lateral direction";
CM_ SG_ 59 VFC_Obj05A_AyStdDev "Standard deviation of Object acceleration in lateral direction";
CM_ SG_ 59 VFC_Obj05A_DxStdDev "Standard deviation of Object distance in longitudinal direction";
CM_ SG_ 59 VFC_Obj05A_ProbMovingLat "Probability of object moving laterally";
CM_ SG_ 59 VFC_Obj05A_DyStdDev "Standard deviation of Object distance in lateral direction";
CM_ SG_ 59 VFC_Obj05A_ProbMovingLong "Probability of object moving longitudinally";
CM_ SG_ 59 VFC_Obj05A_VxStdDev "Standard deviation of Object velocity in longitudinal direction";
CM_ SG_ 59 VFC_Obj05A_HeadingAngleStdDev "Standard deviation of object Heading angle";
CM_ SG_ 59 VFC_Obj05A_VyStdDev "Standard deviation of Object velocity in lateral direction";
CM_ SG_ 59 VFC_Obj05A_HeightStdDev "Standard deviation of object height";
CM_ SG_ 59 VFC_Obj05A_Height "Height of the object";
CM_ SG_ 59 VFC_Obj05A_Length "Length of the object";
CM_ SG_ 59 VFC_Obj05A_HeadingAngle "Heading angle of the object";
CM_ SG_ 59 VFC_Obj05A_NormAx "Normalised Object acceleration in longitudinal direction";
CM_ SG_ 59 VFC_Obj05A_NormVyEdgeLeftStdDev "Standard deviation of Normalised velocity of the ACCS left object edge in lateral direction";
CM_ SG_ 59 VFC_Obj05A_NormVyEdgeLeft "Normalised velocity of the ACCS left object edge in lateral direction";
CM_ SG_ 59 VFC_Obj05A_EdgeBottom "In ACCS coordinates; corresponds to tan(viewing angle of bottom object edge)";
CM_ SG_ 59 VFC_Obj05A_NormVyEdgeRight "Normalised velocity of the ACCS right object edge in lateral direction";
CM_ SG_ 59 VFC_Obj05A_Width "Width of the object";
CM_ SG_ 59 VFC_Obj05A_NormVx "Normalised Object velocity in longitudinal direction";
CM_ SG_ 59 VFC_Obj05A_NormVyEdgeRightStdDev "Standard deviation of Normalised velocity of the ACCS right object edge in lateral direction";
CM_ SG_ 59 VFC_Obj05A_NormAxStdDev "Standard deviation of Normalised Object acceleration in longitudinal direction";
CM_ SG_ 59 VFC_Obj05A_ScaleChange "A scale change of of the detected object";
CM_ SG_ 59 VFC_Obj05A_ScaleChngStdDev "Standard deviation of object scale change";
CM_ SG_ 59 VFC_Obj05A_Reliability "The bitfield shows if the signal quality is assumed to be sufficient for functions with safety target -no false positives-
Bit 0: DYNAMIC
Bit 1: SEMSEG_SURFACE
Bit 2: WDD_CRITICAL
Bit 3: GOD_CONFIRMED
Bit 4: RESTRICTED
Bit 5: ISO26262_SAFE";
CM_ SG_ 59 VFC_Obj05A_NormVxStdDev "Standard deviation of Normalised Object velocity in longitudinal direction";
CM_ SG_ 59 VFC_Obj05A_TypeProb "Probability of the classified object type";
CM_ SG_ 59 VFC_Obj05A_LengthStdDev "Standard deviation of object length";
CM_ SG_ 59 VFC_Obj05A_WidthStdDev "Standard deviation of object width";
CM_ SG_ 59 VFC_Obj05A_EdgeMid "In ACCS coordinates; corresponds to tan(viewing angle of middle object edge)";
CM_ SG_ 59 VFC_Obj05A_EdgeLeft "In ACCS coordinates; corresponds to tan(viewing angle of left object edge)";
CM_ SG_ 59 VFC_Obj05A_EdgeRight "In ACCS coordinates; corresponds to tan(viewing angle of right object edge)";
CM_ SG_ 59 VFC_Obj05A_VisibleView "The visible view of the detected object";
CM_ SG_ 59 VFC_Obj05A_EdgeLeftStdDev "Standard deviation of the ACCS left object edge";
CM_ SG_ 59 VFC_Obj05A_EdgeTop "In ACCS coordinates; corresponds to tan(viewing angle of top object edge)";
CM_ SG_ 59 VFC_Obj05A_HeadOrientation "The orientation of the head of cyclists or pedestrians that are detected";
CM_ SG_ 59 VFC_Obj05A_EdgeMidStdDev "Standard deviation of the ACCS middle object edge";
CM_ SG_ 59 VFC_Obj05A_EdgeRightStdDev "Standard deviation of the ACCS right object edge";
CM_ SG_ 59 VFC_Obj05A_EdgeTopStdDev "Standard deviation of the ACCS top object edge";
CM_ SG_ 59 VFC_Obj05A_EdgeBottomStdDev "Standard deviation of the ACCS bottom object edge";
CM_ SG_ 59 VFC_Obj05A_ClassifiedView "The classified view of object to be used in connection with Heading angle";
CM_ SG_ 60 VFC_Obj06A_CRC "CRC - Autosar E2E Profile 5";
CM_ SG_ 60 VFC_Obj06A_AliveCtr "Alive counter - Autosar E2E Profile 5";
CM_ SG_ 60 VFC_Obj06A_ProtBlockCtr "Protocol-Signal: Block-Counter";
CM_ SG_ 60 VFC_Obj06A_ID "Unique Object ID";
CM_ SG_ 60 VFC_Obj06A_AxStdDev "Standard deviation of Object acceleration in longitudinal direction";
CM_ SG_ 60 VFC_Obj06A_Dx "Object distance in longitudinal direction";
CM_ SG_ 60 VFC_Obj06A_Type "Classification of the object";
CM_ SG_ 60 VFC_Obj06A_Dy "Object distance in lateral direction";
CM_ SG_ 60 VFC_Obj06A_Measured "Indicator if the object detected is measured or predicted";
CM_ SG_ 60 VFC_Obj06A_Vx "Object velocity in longitudinal direction";
CM_ SG_ 60 VFC_Obj06A_MeasSource "Bitfield for the measurement programs from which this object originates
Bit 0: MOD
Bit 1: PDET
Bit 2: OFT
Bit 3: OLS
Bit 4: RESERVED";
CM_ SG_ 60 VFC_Obj06A_Vy "Object velocity in lateral direction";
CM_ SG_ 60 VFC_Obj06A_DirIndicator "The detected direction indicator lights";
CM_ SG_ 60 VFC_Obj06A_BrakeLight "The number of detected lights. More confident if more lights are detected.";
CM_ SG_ 60 VFC_Obj06A_Ax "Object acceleration in longitudinal direction";
CM_ SG_ 60 VFC_Obj06A_CompletelyInImg "indicator if the object is completely measured in the image";
CM_ SG_ 60 VFC_Obj06A_ProbExist "Object existence probability";
CM_ SG_ 60 VFC_Obj06A_Ay "Object acceleration in lateral direction";
CM_ SG_ 60 VFC_Obj06A_AyStdDev "Standard deviation of Object acceleration in lateral direction";
CM_ SG_ 60 VFC_Obj06A_DxStdDev "Standard deviation of Object distance in longitudinal direction";
CM_ SG_ 60 VFC_Obj06A_ProbMovingLat "Probability of object moving laterally";
CM_ SG_ 60 VFC_Obj06A_DyStdDev "Standard deviation of Object distance in lateral direction";
CM_ SG_ 60 VFC_Obj06A_ProbMovingLong "Probability of object moving longitudinally";
CM_ SG_ 60 VFC_Obj06A_VxStdDev "Standard deviation of Object velocity in longitudinal direction";
CM_ SG_ 60 VFC_Obj06A_HeadingAngleStdDev "Standard deviation of object Heading angle";
CM_ SG_ 60 VFC_Obj06A_VyStdDev "Standard deviation of Object velocity in lateral direction";
CM_ SG_ 60 VFC_Obj06A_HeightStdDev "Standard deviation of object height";
CM_ SG_ 60 VFC_Obj06A_Height "Height of the object";
CM_ SG_ 60 VFC_Obj06A_Length "Length of the object";
CM_ SG_ 60 VFC_Obj06A_HeadingAngle "Heading angle of the object";
CM_ SG_ 60 VFC_Obj06A_NormAx "Normalised Object acceleration in longitudinal direction";
CM_ SG_ 60 VFC_Obj06A_NormVyEdgeLeftStdDev "Standard deviation of Normalised velocity of the ACCS left object edge in lateral direction";
CM_ SG_ 60 VFC_Obj06A_NormVyEdgeLeft "Normalised velocity of the ACCS left object edge in lateral direction";
CM_ SG_ 60 VFC_Obj06A_EdgeBottom "In ACCS coordinates; corresponds to tan(viewing angle of bottom object edge)";
CM_ SG_ 60 VFC_Obj06A_NormVyEdgeRight "Normalised velocity of the ACCS right object edge in lateral direction";
CM_ SG_ 60 VFC_Obj06A_Width "Width of the object";
CM_ SG_ 60 VFC_Obj06A_NormVx "Normalised Object velocity in longitudinal direction";
CM_ SG_ 60 VFC_Obj06A_NormVyEdgeRightStdDev "Standard deviation of Normalised velocity of the ACCS right object edge in lateral direction";
CM_ SG_ 60 VFC_Obj06A_NormAxStdDev "Standard deviation of Normalised Object acceleration in longitudinal direction";
CM_ SG_ 60 VFC_Obj06A_ScaleChange "A scale change of of the detected object";
CM_ SG_ 60 VFC_Obj06A_ScaleChngStdDev "Standard deviation of object scale change";
CM_ SG_ 60 VFC_Obj06A_Reliability "The bitfield shows if the signal quality is assumed to be sufficient for functions with safety target -no false positives-
Bit 0: DYNAMIC
Bit 1: SEMSEG_SURFACE
Bit 2: WDD_CRITICAL
Bit 3: GOD_CONFIRMED
Bit 4: RESTRICTED
Bit 5: ISO26262_SAFE";
CM_ SG_ 60 VFC_Obj06A_NormVxStdDev "Standard deviation of Normalised Object velocity in longitudinal direction";
CM_ SG_ 60 VFC_Obj06A_TypeProb "Probability of the classified object type";
CM_ SG_ 60 VFC_Obj06A_LengthStdDev "Standard deviation of object length";
CM_ SG_ 60 VFC_Obj06A_WidthStdDev "Standard deviation of object width";
CM_ SG_ 60 VFC_Obj06A_EdgeMid "In ACCS coordinates; corresponds to tan(viewing angle of middle object edge)";
CM_ SG_ 60 VFC_Obj06A_EdgeLeft "In ACCS coordinates; corresponds to tan(viewing angle of left object edge)";
CM_ SG_ 60 VFC_Obj06A_EdgeRight "In ACCS coordinates; corresponds to tan(viewing angle of right object edge)";
CM_ SG_ 60 VFC_Obj06A_VisibleView "The visible view of the detected object";
CM_ SG_ 60 VFC_Obj06A_EdgeLeftStdDev "Standard deviation of the ACCS left object edge";
CM_ SG_ 60 VFC_Obj06A_EdgeTop "In ACCS coordinates; corresponds to tan(viewing angle of top object edge)";
CM_ SG_ 60 VFC_Obj06A_HeadOrientation "The orientation of the head of cyclists or pedestrians that are detected";
CM_ SG_ 60 VFC_Obj06A_EdgeMidStdDev "Standard deviation of the ACCS middle object edge";
CM_ SG_ 60 VFC_Obj06A_EdgeRightStdDev "Standard deviation of the ACCS right object edge";
CM_ SG_ 60 VFC_Obj06A_EdgeTopStdDev "Standard deviation of the ACCS top object edge";
CM_ SG_ 60 VFC_Obj06A_EdgeBottomStdDev "Standard deviation of the ACCS bottom object edge";
CM_ SG_ 60 VFC_Obj06A_ClassifiedView "The classified view of object to be used in connection with Heading angle";
CM_ SG_ 61 VFC_Obj07A_CRC "CRC - Autosar E2E Profile 5";
CM_ SG_ 61 VFC_Obj07A_AliveCtr "Alive counter - Autosar E2E Profile 5";
CM_ SG_ 61 VFC_Obj07A_ProtBlockCtr "Protocol-Signal: Block-Counter";
CM_ SG_ 61 VFC_Obj07A_ID "Unique Object ID";
CM_ SG_ 61 VFC_Obj07A_AxStdDev "Standard deviation of Object acceleration in longitudinal direction";
CM_ SG_ 61 VFC_Obj07A_Dx "Object distance in longitudinal direction";
CM_ SG_ 61 VFC_Obj07A_Type "Classification of the object";
CM_ SG_ 61 VFC_Obj07A_Dy "Object distance in lateral direction";
CM_ SG_ 61 VFC_Obj07A_Measured "Indicator if the object detected is measured or predicted";
CM_ SG_ 61 VFC_Obj07A_Vx "Object velocity in longitudinal direction";
CM_ SG_ 61 VFC_Obj07A_MeasSource "Bitfield for the measurement programs from which this object originates
Bit 0: MOD
Bit 1: PDET
Bit 2: OFT
Bit 3: OLS
Bit 4: RESERVED";
CM_ SG_ 61 VFC_Obj07A_Vy "Object velocity in lateral direction";
CM_ SG_ 61 VFC_Obj07A_DirIndicator "The detected direction indicator lights";
CM_ SG_ 61 VFC_Obj07A_BrakeLight "The number of detected lights. More confident if more lights are detected.";
CM_ SG_ 61 VFC_Obj07A_Ax "Object acceleration in longitudinal direction";
CM_ SG_ 61 VFC_Obj07A_CompletelyInImg "indicator if the object is completely measured in the image";
CM_ SG_ 61 VFC_Obj07A_ProbExist "Object existence probability";
CM_ SG_ 61 VFC_Obj07A_Ay "Object acceleration in lateral direction";
CM_ SG_ 61 VFC_Obj07A_AyStdDev "Standard deviation of Object acceleration in lateral direction";
CM_ SG_ 61 VFC_Obj07A_DxStdDev "Standard deviation of Object distance in longitudinal direction";
CM_ SG_ 61 VFC_Obj07A_ProbMovingLat "Probability of object moving laterally";
CM_ SG_ 61 VFC_Obj07A_DyStdDev "Standard deviation of Object distance in lateral direction";
CM_ SG_ 61 VFC_Obj07A_ProbMovingLong "Probability of object moving longitudinally";
CM_ SG_ 61 VFC_Obj07A_VxStdDev "Standard deviation of Object velocity in longitudinal direction";
CM_ SG_ 61 VFC_Obj07A_HeadingAngleStdDev "Standard deviation of object Heading angle";
CM_ SG_ 61 VFC_Obj07A_VyStdDev "Standard deviation of Object velocity in lateral direction";
CM_ SG_ 61 VFC_Obj07A_HeightStdDev "Standard deviation of object height";
CM_ SG_ 61 VFC_Obj07A_Height "Height of the object";
CM_ SG_ 61 VFC_Obj07A_Length "Length of the object";
CM_ SG_ 61 VFC_Obj07A_HeadingAngle "Heading angle of the object";
CM_ SG_ 61 VFC_Obj07A_NormAx "Normalised Object acceleration in longitudinal direction";
CM_ SG_ 61 VFC_Obj07A_NormVyEdgeLeftStdDev "Standard deviation of Normalised velocity of the ACCS left object edge in lateral direction";
CM_ SG_ 61 VFC_Obj07A_NormVyEdgeLeft "Normalised velocity of the ACCS left object edge in lateral direction";
CM_ SG_ 61 VFC_Obj07A_EdgeBottom "In ACCS coordinates; corresponds to tan(viewing angle of bottom object edge)";
CM_ SG_ 61 VFC_Obj07A_NormVyEdgeRight "Normalised velocity of the ACCS right object edge in lateral direction";
CM_ SG_ 61 VFC_Obj07A_Width "Width of the object";
CM_ SG_ 61 VFC_Obj07A_NormVx "Normalised Object velocity in longitudinal direction";
CM_ SG_ 61 VFC_Obj07A_NormVyEdgeRightStdDev "Standard deviation of Normalised velocity of the ACCS right object edge in lateral direction";
CM_ SG_ 61 VFC_Obj07A_NormAxStdDev "Standard deviation of Normalised Object acceleration in longitudinal direction";
CM_ SG_ 61 VFC_Obj07A_ScaleChange "A scale change of of the detected object";
CM_ SG_ 61 VFC_Obj07A_ScaleChngStdDev "Standard deviation of object scale change";
CM_ SG_ 61 VFC_Obj07A_Reliability "The bitfield shows if the signal quality is assumed to be sufficient for functions with safety target -no false positives-
Bit 0: DYNAMIC
Bit 1: SEMSEG_SURFACE
Bit 2: WDD_CRITICAL
Bit 3: GOD_CONFIRMED
Bit 4: RESTRICTED
Bit 5: ISO26262_SAFE";
CM_ SG_ 61 VFC_Obj07A_NormVxStdDev "Standard deviation of Normalised Object velocity in longitudinal direction";
CM_ SG_ 61 VFC_Obj07A_TypeProb "Probability of the classified object type";
CM_ SG_ 61 VFC_Obj07A_LengthStdDev "Standard deviation of object length";
CM_ SG_ 61 VFC_Obj07A_WidthStdDev "Standard deviation of object width";
CM_ SG_ 61 VFC_Obj07A_EdgeMid "In ACCS coordinates; corresponds to tan(viewing angle of middle object edge)";
CM_ SG_ 61 VFC_Obj07A_EdgeLeft "In ACCS coordinates; corresponds to tan(viewing angle of left object edge)";
CM_ SG_ 61 VFC_Obj07A_EdgeRight "In ACCS coordinates; corresponds to tan(viewing angle of right object edge)";
CM_ SG_ 61 VFC_Obj07A_VisibleView "The visible view of the detected object";
CM_ SG_ 61 VFC_Obj07A_EdgeLeftStdDev "Standard deviation of the ACCS left object edge";
CM_ SG_ 61 VFC_Obj07A_EdgeTop "In ACCS coordinates; corresponds to tan(viewing angle of top object edge)";
CM_ SG_ 61 VFC_Obj07A_HeadOrientation "The orientation of the head of cyclists or pedestrians that are detected";
CM_ SG_ 61 VFC_Obj07A_EdgeMidStdDev "Standard deviation of the ACCS middle object edge";
CM_ SG_ 61 VFC_Obj07A_EdgeRightStdDev "Standard deviation of the ACCS right object edge";
CM_ SG_ 61 VFC_Obj07A_EdgeTopStdDev "Standard deviation of the ACCS top object edge";
CM_ SG_ 61 VFC_Obj07A_EdgeBottomStdDev "Standard deviation of the ACCS bottom object edge";
CM_ SG_ 61 VFC_Obj07A_ClassifiedView "The classified view of object to be used in connection with Heading angle";
CM_ SG_ 62 VFC_Obj08A_CRC "CRC - Autosar E2E Profile 5";
CM_ SG_ 62 VFC_Obj08A_AliveCtr "Alive counter - Autosar E2E Profile 5";
CM_ SG_ 62 VFC_Obj08A_ProtBlockCtr "Protocol-Signal: Block-Counter";
CM_ SG_ 62 VFC_Obj08A_ID "Unique Object ID";
CM_ SG_ 62 VFC_Obj08A_AxStdDev "Standard deviation of Object acceleration in longitudinal direction";
CM_ SG_ 62 VFC_Obj08A_Dx "Object distance in longitudinal direction";
CM_ SG_ 62 VFC_Obj08A_Type "Classification of the object";
CM_ SG_ 62 VFC_Obj08A_Dy "Object distance in lateral direction";
CM_ SG_ 62 VFC_Obj08A_Measured "Indicator if the object detected is measured or predicted";
CM_ SG_ 62 VFC_Obj08A_Vx "Object velocity in longitudinal direction";
CM_ SG_ 62 VFC_Obj08A_MeasSource "Bitfield for the measurement programs from which this object originates
Bit 0: MOD
Bit 1: PDET
Bit 2: OFT
Bit 3: OLS
Bit 4: RESERVED";
CM_ SG_ 62 VFC_Obj08A_Vy "Object velocity in lateral direction";
CM_ SG_ 62 VFC_Obj08A_DirIndicator "The detected direction indicator lights";
CM_ SG_ 62 VFC_Obj08A_BrakeLight "The number of detected lights. More confident if more lights are detected.";
CM_ SG_ 62 VFC_Obj08A_Ax "Object acceleration in longitudinal direction";
CM_ SG_ 62 VFC_Obj08A_CompletelyInImg "indicator if the object is completely measured in the image";
CM_ SG_ 62 VFC_Obj08A_ProbExist "Object existence probability";
CM_ SG_ 62 VFC_Obj08A_Ay "Object acceleration in lateral direction";
CM_ SG_ 62 VFC_Obj08A_AyStdDev "Standard deviation of Object acceleration in lateral direction";
CM_ SG_ 62 VFC_Obj08A_DxStdDev "Standard deviation of Object distance in longitudinal direction";
CM_ SG_ 62 VFC_Obj08A_ProbMovingLat "Probability of object moving laterally";
CM_ SG_ 62 VFC_Obj08A_DyStdDev "Standard deviation of Object distance in lateral direction";
CM_ SG_ 62 VFC_Obj08A_ProbMovingLong "Probability of object moving longitudinally";
CM_ SG_ 62 VFC_Obj08A_VxStdDev "Standard deviation of Object velocity in longitudinal direction";
CM_ SG_ 62 VFC_Obj08A_HeadingAngleStdDev "Standard deviation of object Heading angle";
CM_ SG_ 62 VFC_Obj08A_VyStdDev "Standard deviation of Object velocity in lateral direction";
CM_ SG_ 62 VFC_Obj08A_HeightStdDev "Standard deviation of object height";
CM_ SG_ 62 VFC_Obj08A_Height "Height of the object";
CM_ SG_ 62 VFC_Obj08A_Length "Length of the object";
CM_ SG_ 62 VFC_Obj08A_HeadingAngle "Heading angle of the object";
CM_ SG_ 62 VFC_Obj08A_NormAx "Normalised Object acceleration in longitudinal direction";
CM_ SG_ 62 VFC_Obj08A_NormVyEdgeLeftStdDev "Standard deviation of Normalised velocity of the ACCS left object edge in lateral direction";
CM_ SG_ 62 VFC_Obj08A_NormVyEdgeLeft "Normalised velocity of the ACCS left object edge in lateral direction";
CM_ SG_ 62 VFC_Obj08A_EdgeBottom "In ACCS coordinates; corresponds to tan(viewing angle of bottom object edge)";
CM_ SG_ 62 VFC_Obj08A_NormVyEdgeRight "Normalised velocity of the ACCS right object edge in lateral direction";
CM_ SG_ 62 VFC_Obj08A_Width "Width of the object";
CM_ SG_ 62 VFC_Obj08A_NormVx "Normalised Object velocity in longitudinal direction";
CM_ SG_ 62 VFC_Obj08A_NormVyEdgeRightStdDev "Standard deviation of Normalised velocity of the ACCS right object edge in lateral direction";
CM_ SG_ 62 VFC_Obj08A_NormAxStdDev "Standard deviation of Normalised Object acceleration in longitudinal direction";
CM_ SG_ 62 VFC_Obj08A_ScaleChange "A scale change of of the detected object";
CM_ SG_ 62 VFC_Obj08A_ScaleChngStdDev "Standard deviation of object scale change";
CM_ SG_ 62 VFC_Obj08A_Reliability "The bitfield shows if the signal quality is assumed to be sufficient for functions with safety target -no false positives-
Bit 0: DYNAMIC
Bit 1: SEMSEG_SURFACE
Bit 2: WDD_CRITICAL
Bit 3: GOD_CONFIRMED
Bit 4: RESTRICTED
Bit 5: ISO26262_SAFE";
CM_ SG_ 62 VFC_Obj08A_NormVxStdDev "Standard deviation of Normalised Object velocity in longitudinal direction";
CM_ SG_ 62 VFC_Obj08A_TypeProb "Probability of the classified object type";
CM_ SG_ 62 VFC_Obj08A_LengthStdDev "Standard deviation of object length";
CM_ SG_ 62 VFC_Obj08A_WidthStdDev "Standard deviation of object width";
CM_ SG_ 62 VFC_Obj08A_EdgeMid "In ACCS coordinates; corresponds to tan(viewing angle of middle object edge)";
CM_ SG_ 62 VFC_Obj08A_EdgeLeft "In ACCS coordinates; corresponds to tan(viewing angle of left object edge)";
CM_ SG_ 62 VFC_Obj08A_EdgeRight "In ACCS coordinates; corresponds to tan(viewing angle of right object edge)";
CM_ SG_ 62 VFC_Obj08A_VisibleView "The visible view of the detected object";
CM_ SG_ 62 VFC_Obj08A_EdgeLeftStdDev "Standard deviation of the ACCS left object edge";
CM_ SG_ 62 VFC_Obj08A_EdgeTop "In ACCS coordinates; corresponds to tan(viewing angle of top object edge)";
CM_ SG_ 62 VFC_Obj08A_HeadOrientation "The orientation of the head of cyclists or pedestrians that are detected";
CM_ SG_ 62 VFC_Obj08A_EdgeMidStdDev "Standard deviation of the ACCS middle object edge";
CM_ SG_ 62 VFC_Obj08A_EdgeRightStdDev "Standard deviation of the ACCS right object edge";
CM_ SG_ 62 VFC_Obj08A_EdgeTopStdDev "Standard deviation of the ACCS top object edge";
CM_ SG_ 62 VFC_Obj08A_EdgeBottomStdDev "Standard deviation of the ACCS bottom object edge";
CM_ SG_ 62 VFC_Obj08A_ClassifiedView "The classified view of object to be used in connection with Heading angle";
CM_ SG_ 63 VFC_Obj09A_CRC "CRC - Autosar E2E Profile 5";
CM_ SG_ 63 VFC_Obj09A_AliveCtr "Alive counter - Autosar E2E Profile 5";
CM_ SG_ 63 VFC_Obj09A_ProtBlockCtr "Protocol-Signal: Block-Counter";
CM_ SG_ 63 VFC_Obj09A_ID "Unique Object ID";
CM_ SG_ 63 VFC_Obj09A_AxStdDev "Standard deviation of Object acceleration in longitudinal direction";
CM_ SG_ 63 VFC_Obj09A_Dx "Object distance in longitudinal direction";
CM_ SG_ 63 VFC_Obj09A_Type "Classification of the object";
CM_ SG_ 63 VFC_Obj09A_Dy "Object distance in lateral direction";
CM_ SG_ 63 VFC_Obj09A_Measured "Indicator if the object detected is measured or predicted";
CM_ SG_ 63 VFC_Obj09A_Vx "Object velocity in longitudinal direction";
CM_ SG_ 63 VFC_Obj09A_MeasSource "Bitfield for the measurement programs from which this object originates
Bit 0: MOD
Bit 1: PDET
Bit 2: OFT
Bit 3: OLS
Bit 4: RESERVED";
CM_ SG_ 63 VFC_Obj09A_Vy "Object velocity in lateral direction";
CM_ SG_ 63 VFC_Obj09A_DirIndicator "The detected direction indicator lights";
CM_ SG_ 63 VFC_Obj09A_BrakeLight "The number of detected lights. More confident if more lights are detected.";
CM_ SG_ 63 VFC_Obj09A_Ax "Object acceleration in longitudinal direction";
CM_ SG_ 63 VFC_Obj09A_CompletelyInImg "indicator if the object is completely measured in the image";
CM_ SG_ 63 VFC_Obj09A_ProbExist "Object existence probability";
CM_ SG_ 63 VFC_Obj09A_Ay "Object acceleration in lateral direction";
CM_ SG_ 63 VFC_Obj09A_AyStdDev "Standard deviation of Object acceleration in lateral direction";
CM_ SG_ 63 VFC_Obj09A_DxStdDev "Standard deviation of Object distance in longitudinal direction";
CM_ SG_ 63 VFC_Obj09A_ProbMovingLat "Probability of object moving laterally";
CM_ SG_ 63 VFC_Obj09A_DyStdDev "Standard deviation of Object distance in lateral direction";
CM_ SG_ 63 VFC_Obj09A_ProbMovingLong "Probability of object moving longitudinally";
CM_ SG_ 63 VFC_Obj09A_VxStdDev "Standard deviation of Object velocity in longitudinal direction";
CM_ SG_ 63 VFC_Obj09A_HeadingAngleStdDev "Standard deviation of object Heading angle";
CM_ SG_ 63 VFC_Obj09A_VyStdDev "Standard deviation of Object velocity in lateral direction";
CM_ SG_ 63 VFC_Obj09A_HeightStdDev "Standard deviation of object height";
CM_ SG_ 63 VFC_Obj09A_Height "Height of the object";
CM_ SG_ 63 VFC_Obj09A_Length "Length of the object";
CM_ SG_ 63 VFC_Obj09A_HeadingAngle "Heading angle of the object";
CM_ SG_ 63 VFC_Obj09A_NormAx "Normalised Object acceleration in longitudinal direction";
CM_ SG_ 63 VFC_Obj09A_NormVyEdgeLeftStdDev "Standard deviation of Normalised velocity of the ACCS left object edge in lateral direction";
CM_ SG_ 63 VFC_Obj09A_NormVyEdgeLeft "Normalised velocity of the ACCS left object edge in lateral direction";
CM_ SG_ 63 VFC_Obj09A_EdgeBottom "In ACCS coordinates; corresponds to tan(viewing angle of bottom object edge)";
CM_ SG_ 63 VFC_Obj09A_NormVyEdgeRight "Normalised velocity of the ACCS right object edge in lateral direction";
CM_ SG_ 63 VFC_Obj09A_Width "Width of the object";
CM_ SG_ 63 VFC_Obj09A_NormVx "Normalised Object velocity in longitudinal direction";
CM_ SG_ 63 VFC_Obj09A_NormVyEdgeRightStdDev "Standard deviation of Normalised velocity of the ACCS right object edge in lateral direction";
CM_ SG_ 63 VFC_Obj09A_NormAxStdDev "Standard deviation of Normalised Object acceleration in longitudinal direction";
CM_ SG_ 63 VFC_Obj09A_ScaleChange "A scale change of of the detected object";
CM_ SG_ 63 VFC_Obj09A_ScaleChngStdDev "Standard deviation of object scale change";
CM_ SG_ 63 VFC_Obj09A_Reliability "The bitfield shows if the signal quality is assumed to be sufficient for functions with safety target -no false positives-
Bit 0: DYNAMIC
Bit 1: SEMSEG_SURFACE
Bit 2: WDD_CRITICAL
Bit 3: GOD_CONFIRMED
Bit 4: RESTRICTED
Bit 5: ISO26262_SAFE";
CM_ SG_ 63 VFC_Obj09A_NormVxStdDev "Standard deviation of Normalised Object velocity in longitudinal direction";
CM_ SG_ 63 VFC_Obj09A_TypeProb "Probability of the classified object type";
CM_ SG_ 63 VFC_Obj09A_LengthStdDev "Standard deviation of object length";
CM_ SG_ 63 VFC_Obj09A_WidthStdDev "Standard deviation of object width";
CM_ SG_ 63 VFC_Obj09A_EdgeMid "In ACCS coordinates; corresponds to tan(viewing angle of middle object edge)";
CM_ SG_ 63 VFC_Obj09A_EdgeLeft "In ACCS coordinates; corresponds to tan(viewing angle of left object edge)";
CM_ SG_ 63 VFC_Obj09A_EdgeRight "In ACCS coordinates; corresponds to tan(viewing angle of right object edge)";
CM_ SG_ 63 VFC_Obj09A_VisibleView "The visible view of the detected object";
CM_ SG_ 63 VFC_Obj09A_EdgeLeftStdDev "Standard deviation of the ACCS left object edge";
CM_ SG_ 63 VFC_Obj09A_EdgeTop "In ACCS coordinates; corresponds to tan(viewing angle of top object edge)";
CM_ SG_ 63 VFC_Obj09A_HeadOrientation "The orientation of the head of cyclists or pedestrians that are detected";
CM_ SG_ 63 VFC_Obj09A_EdgeMidStdDev "Standard deviation of the ACCS middle object edge";
CM_ SG_ 63 VFC_Obj09A_EdgeRightStdDev "Standard deviation of the ACCS right object edge";
CM_ SG_ 63 VFC_Obj09A_EdgeTopStdDev "Standard deviation of the ACCS top object edge";
CM_ SG_ 63 VFC_Obj09A_EdgeBottomStdDev "Standard deviation of the ACCS bottom object edge";
CM_ SG_ 63 VFC_Obj09A_ClassifiedView "The classified view of object to be used in connection with Heading angle";
CM_ SG_ 64 VFC_Obj10A_CRC "CRC - Autosar E2E Profile 5";
CM_ SG_ 64 VFC_Obj10A_AliveCtr "Alive counter - Autosar E2E Profile 5";
CM_ SG_ 64 VFC_Obj10A_ProtBlockCtr "Protocol-Signal: Block-Counter";
CM_ SG_ 64 VFC_Obj10A_ID "Unique Object ID";
CM_ SG_ 64 VFC_Obj10A_AxStdDev "Standard deviation of Object acceleration in longitudinal direction";
CM_ SG_ 64 VFC_Obj10A_Dx "Object distance in longitudinal direction";
CM_ SG_ 64 VFC_Obj10A_Type "Classification of the object";
CM_ SG_ 64 VFC_Obj10A_Dy "Object distance in lateral direction";
CM_ SG_ 64 VFC_Obj10A_Measured "Indicator if the object detected is measured or predicted";
CM_ SG_ 64 VFC_Obj10A_Vx "Object velocity in longitudinal direction";
CM_ SG_ 64 VFC_Obj10A_MeasSource "Bitfield for the measurement programs from which this object originates
Bit 0: MOD
Bit 1: PDET
Bit 2: OFT
Bit 3: OLS
Bit 4: RESERVED";
CM_ SG_ 64 VFC_Obj10A_Vy "Object velocity in lateral direction";
CM_ SG_ 64 VFC_Obj10A_DirIndicator "The detected direction indicator lights";
CM_ SG_ 64 VFC_Obj10A_BrakeLight "The number of detected lights. More confident if more lights are detected.";
CM_ SG_ 64 VFC_Obj10A_Ax "Object acceleration in longitudinal direction";
CM_ SG_ 64 VFC_Obj10A_CompletelyInImg "indicator if the object is completely measured in the image";
CM_ SG_ 64 VFC_Obj10A_ProbExist "Object existence probability";
CM_ SG_ 64 VFC_Obj10A_Ay "Object acceleration in lateral direction";
CM_ SG_ 64 VFC_Obj10A_AyStdDev "Standard deviation of Object acceleration in lateral direction";
CM_ SG_ 64 VFC_Obj10A_DxStdDev "Standard deviation of Object distance in longitudinal direction";
CM_ SG_ 64 VFC_Obj10A_ProbMovingLat "Probability of object moving laterally";
CM_ SG_ 64 VFC_Obj10A_DyStdDev "Standard deviation of Object distance in lateral direction";
CM_ SG_ 64 VFC_Obj10A_ProbMovingLong "Probability of object moving longitudinally";
CM_ SG_ 64 VFC_Obj10A_VxStdDev "Standard deviation of Object velocity in longitudinal direction";
CM_ SG_ 64 VFC_Obj10A_HeadingAngleStdDev "Standard deviation of object Heading angle";
CM_ SG_ 64 VFC_Obj10A_VyStdDev "Standard deviation of Object velocity in lateral direction";
CM_ SG_ 64 VFC_Obj10A_HeightStdDev "Standard deviation of object height";
CM_ SG_ 64 VFC_Obj10A_Height "Height of the object";
CM_ SG_ 64 VFC_Obj10A_Length "Length of the object";
CM_ SG_ 64 VFC_Obj10A_HeadingAngle "Heading angle of the object";
CM_ SG_ 64 VFC_Obj10A_NormAx "Normalised Object acceleration in longitudinal direction";
CM_ SG_ 64 VFC_Obj10A_NormVyEdgeLeftStdDev "Standard deviation of Normalised velocity of the ACCS left object edge in lateral direction";
CM_ SG_ 64 VFC_Obj10A_NormVyEdgeLeft "Normalised velocity of the ACCS left object edge in lateral direction";
CM_ SG_ 64 VFC_Obj10A_EdgeBottom "In ACCS coordinates; corresponds to tan(viewing angle of bottom object edge)";
CM_ SG_ 64 VFC_Obj10A_NormVyEdgeRight "Normalised velocity of the ACCS right object edge in lateral direction";
CM_ SG_ 64 VFC_Obj10A_Width "Width of the object";
CM_ SG_ 64 VFC_Obj10A_NormVx "Normalised Object velocity in longitudinal direction";
CM_ SG_ 64 VFC_Obj10A_NormVyEdgeRightStdDev "Standard deviation of Normalised velocity of the ACCS right object edge in lateral direction";
CM_ SG_ 64 VFC_Obj10A_NormAxStdDev "Standard deviation of Normalised Object acceleration in longitudinal direction";
CM_ SG_ 64 VFC_Obj10A_ScaleChange "A scale change of of the detected object";
CM_ SG_ 64 VFC_Obj10A_ScaleChngStdDev "Standard deviation of object scale change";
CM_ SG_ 64 VFC_Obj10A_Reliability "The bitfield shows if the signal quality is assumed to be sufficient for functions with safety target -no false positives-
Bit 0: DYNAMIC
Bit 1: SEMSEG_SURFACE
Bit 2: WDD_CRITICAL
Bit 3: GOD_CONFIRMED
Bit 4: RESTRICTED
Bit 5: ISO26262_SAFE";
CM_ SG_ 64 VFC_Obj10A_NormVxStdDev "Standard deviation of Normalised Object velocity in longitudinal direction";
CM_ SG_ 64 VFC_Obj10A_TypeProb "Probability of the classified object type";
CM_ SG_ 64 VFC_Obj10A_LengthStdDev "Standard deviation of object length";
CM_ SG_ 64 VFC_Obj10A_WidthStdDev "Standard deviation of object width";
CM_ SG_ 64 VFC_Obj10A_EdgeMid "In ACCS coordinates; corresponds to tan(viewing angle of middle object edge)";
CM_ SG_ 64 VFC_Obj10A_EdgeLeft "In ACCS coordinates; corresponds to tan(viewing angle of left object edge)";
CM_ SG_ 64 VFC_Obj10A_EdgeRight "In ACCS coordinates; corresponds to tan(viewing angle of right object edge)";
CM_ SG_ 64 VFC_Obj10A_VisibleView "The visible view of the detected object";
CM_ SG_ 64 VFC_Obj10A_EdgeLeftStdDev "Standard deviation of the ACCS left object edge";
CM_ SG_ 64 VFC_Obj10A_EdgeTop "In ACCS coordinates; corresponds to tan(viewing angle of top object edge)";
CM_ SG_ 64 VFC_Obj10A_HeadOrientation "The orientation of the head of cyclists or pedestrians that are detected";
CM_ SG_ 64 VFC_Obj10A_EdgeMidStdDev "Standard deviation of the ACCS middle object edge";
CM_ SG_ 64 VFC_Obj10A_EdgeRightStdDev "Standard deviation of the ACCS right object edge";
CM_ SG_ 64 VFC_Obj10A_EdgeTopStdDev "Standard deviation of the ACCS top object edge";
CM_ SG_ 64 VFC_Obj10A_EdgeBottomStdDev "Standard deviation of the ACCS bottom object edge";
CM_ SG_ 64 VFC_Obj10A_ClassifiedView "The classified view of object to be used in connection with Heading angle";
CM_ SG_ 65 VFC_Obj11A_CRC "CRC - Autosar E2E Profile 5";
CM_ SG_ 65 VFC_Obj11A_AliveCtr "Alive counter - Autosar E2E Profile 5";
CM_ SG_ 65 VFC_Obj11A_ProtBlockCtr "Protocol-Signal: Block-Counter";
CM_ SG_ 65 VFC_Obj11A_ID "Unique Object ID";
CM_ SG_ 65 VFC_Obj11A_AxStdDev "Standard deviation of Object acceleration in longitudinal direction";
CM_ SG_ 65 VFC_Obj11A_Dx "Object distance in longitudinal direction";
CM_ SG_ 65 VFC_Obj11A_Type "Classification of the object";
CM_ SG_ 65 VFC_Obj11A_Dy "Object distance in lateral direction";
CM_ SG_ 65 VFC_Obj11A_Measured "Indicator if the object detected is measured or predicted";
CM_ SG_ 65 VFC_Obj11A_Vx "Object velocity in longitudinal direction";
CM_ SG_ 65 VFC_Obj11A_MeasSource "Bitfield for the measurement programs from which this object originates
Bit 0: MOD
Bit 1: PDET
Bit 2: OFT
Bit 3: OLS
Bit 4: RESERVED";
CM_ SG_ 65 VFC_Obj11A_Vy "Object velocity in lateral direction";
CM_ SG_ 65 VFC_Obj11A_DirIndicator "The detected direction indicator lights";
CM_ SG_ 65 VFC_Obj11A_BrakeLight "The number of detected lights. More confident if more lights are detected.";
CM_ SG_ 65 VFC_Obj11A_Ax "Object acceleration in longitudinal direction";
CM_ SG_ 65 VFC_Obj11A_CompletelyInImg "indicator if the object is completely measured in the image";
CM_ SG_ 65 VFC_Obj11A_ProbExist "Object existence probability";
CM_ SG_ 65 VFC_Obj11A_Ay "Object acceleration in lateral direction";
CM_ SG_ 65 VFC_Obj11A_AyStdDev "Standard deviation of Object acceleration in lateral direction";
CM_ SG_ 65 VFC_Obj11A_DxStdDev "Standard deviation of Object distance in longitudinal direction";
CM_ SG_ 65 VFC_Obj11A_ProbMovingLat "Probability of object moving laterally";
CM_ SG_ 65 VFC_Obj11A_DyStdDev "Standard deviation of Object distance in lateral direction";
CM_ SG_ 65 VFC_Obj11A_ProbMovingLong "Probability of object moving longitudinally";
CM_ SG_ 65 VFC_Obj11A_VxStdDev "Standard deviation of Object velocity in longitudinal direction";
CM_ SG_ 65 VFC_Obj11A_HeadingAngleStdDev "Standard deviation of object Heading angle";
CM_ SG_ 65 VFC_Obj11A_VyStdDev "Standard deviation of Object velocity in lateral direction";
CM_ SG_ 65 VFC_Obj11A_HeightStdDev "Standard deviation of object height";
CM_ SG_ 65 VFC_Obj11A_Height "Height of the object";
CM_ SG_ 65 VFC_Obj11A_Length "Length of the object";
CM_ SG_ 65 VFC_Obj11A_HeadingAngle "Heading angle of the object";
CM_ SG_ 65 VFC_Obj11A_NormAx "Normalised Object acceleration in longitudinal direction";
CM_ SG_ 65 VFC_Obj11A_NormVyEdgeLeftStdDev "Standard deviation of Normalised velocity of the ACCS left object edge in lateral direction";
CM_ SG_ 65 VFC_Obj11A_NormVyEdgeLeft "Normalised velocity of the ACCS left object edge in lateral direction";
CM_ SG_ 65 VFC_Obj11A_EdgeBottom "In ACCS coordinates; corresponds to tan(viewing angle of bottom object edge)";
CM_ SG_ 65 VFC_Obj11A_NormVyEdgeRight "Normalised velocity of the ACCS right object edge in lateral direction";
CM_ SG_ 65 VFC_Obj11A_Width "Width of the object";
CM_ SG_ 65 VFC_Obj11A_NormVx "Normalised Object velocity in longitudinal direction";
CM_ SG_ 65 VFC_Obj11A_NormVyEdgeRightStdDev "Standard deviation of Normalised velocity of the ACCS right object edge in lateral direction";
CM_ SG_ 65 VFC_Obj11A_NormAxStdDev "Standard deviation of Normalised Object acceleration in longitudinal direction";
CM_ SG_ 65 VFC_Obj11A_ScaleChange "A scale change of of the detected object";
CM_ SG_ 65 VFC_Obj11A_ScaleChngStdDev "Standard deviation of object scale change";
CM_ SG_ 65 VFC_Obj11A_Reliability "The bitfield shows if the signal quality is assumed to be sufficient for functions with safety target -no false positives-
Bit 0: DYNAMIC
Bit 1: SEMSEG_SURFACE
Bit 2: WDD_CRITICAL
Bit 3: GOD_CONFIRMED
Bit 4: RESTRICTED
Bit 5: ISO26262_SAFE";
CM_ SG_ 65 VFC_Obj11A_NormVxStdDev "Standard deviation of Normalised Object velocity in longitudinal direction";
CM_ SG_ 65 VFC_Obj11A_TypeProb "Probability of the classified object type";
CM_ SG_ 65 VFC_Obj11A_LengthStdDev "Standard deviation of object length";
CM_ SG_ 65 VFC_Obj11A_WidthStdDev "Standard deviation of object width";
CM_ SG_ 65 VFC_Obj11A_EdgeMid "In ACCS coordinates; corresponds to tan(viewing angle of middle object edge)";
CM_ SG_ 65 VFC_Obj11A_EdgeLeft "In ACCS coordinates; corresponds to tan(viewing angle of left object edge)";
CM_ SG_ 65 VFC_Obj11A_EdgeRight "In ACCS coordinates; corresponds to tan(viewing angle of right object edge)";
CM_ SG_ 65 VFC_Obj11A_VisibleView "The visible view of the detected object";
CM_ SG_ 65 VFC_Obj11A_EdgeLeftStdDev "Standard deviation of the ACCS left object edge";
CM_ SG_ 65 VFC_Obj11A_EdgeTop "In ACCS coordinates; corresponds to tan(viewing angle of top object edge)";
CM_ SG_ 65 VFC_Obj11A_HeadOrientation "The orientation of the head of cyclists or pedestrians that are detected";
CM_ SG_ 65 VFC_Obj11A_EdgeMidStdDev "Standard deviation of the ACCS middle object edge";
CM_ SG_ 65 VFC_Obj11A_EdgeRightStdDev "Standard deviation of the ACCS right object edge";
CM_ SG_ 65 VFC_Obj11A_EdgeTopStdDev "Standard deviation of the ACCS top object edge";
CM_ SG_ 65 VFC_Obj11A_EdgeBottomStdDev "Standard deviation of the ACCS bottom object edge";
CM_ SG_ 65 VFC_Obj11A_ClassifiedView "The classified view of object to be used in connection with Heading angle";
CM_ SG_ 66 VFC_Obj12A_CRC "CRC - Autosar E2E Profile 5";
CM_ SG_ 66 VFC_Obj12A_AliveCtr "Alive counter - Autosar E2E Profile 5";
CM_ SG_ 66 VFC_Obj12A_ProtBlockCtr "Protocol-Signal: Block-Counter";
CM_ SG_ 66 VFC_Obj12A_ID "Unique Object ID";
CM_ SG_ 66 VFC_Obj12A_AxStdDev "Standard deviation of Object acceleration in longitudinal direction";
CM_ SG_ 66 VFC_Obj12A_Dx "Object distance in longitudinal direction";
CM_ SG_ 66 VFC_Obj12A_Type "Classification of the object";
CM_ SG_ 66 VFC_Obj12A_Dy "Object distance in lateral direction";
CM_ SG_ 66 VFC_Obj12A_Measured "Indicator if the object detected is measured or predicted";
CM_ SG_ 66 VFC_Obj12A_Vx "Object velocity in longitudinal direction";
CM_ SG_ 66 VFC_Obj12A_MeasSource "Bitfield for the measurement programs from which this object originates
Bit 0: MOD
Bit 1: PDET
Bit 2: OFT
Bit 3: OLS
Bit 4: RESERVED";
CM_ SG_ 66 VFC_Obj12A_Vy "Object velocity in lateral direction";
CM_ SG_ 66 VFC_Obj12A_DirIndicator "The detected direction indicator lights";
CM_ SG_ 66 VFC_Obj12A_BrakeLight "The number of detected lights. More confident if more lights are detected.";
CM_ SG_ 66 VFC_Obj12A_Ax "Object acceleration in longitudinal direction";
CM_ SG_ 66 VFC_Obj12A_CompletelyInImg "indicator if the object is completely measured in the image";
CM_ SG_ 66 VFC_Obj12A_ProbExist "Object existence probability";
CM_ SG_ 66 VFC_Obj12A_Ay "Object acceleration in lateral direction";
CM_ SG_ 66 VFC_Obj12A_AyStdDev "Standard deviation of Object acceleration in lateral direction";
CM_ SG_ 66 VFC_Obj12A_DxStdDev "Standard deviation of Object distance in longitudinal direction";
CM_ SG_ 66 VFC_Obj12A_ProbMovingLat "Probability of object moving laterally";
CM_ SG_ 66 VFC_Obj12A_DyStdDev "Standard deviation of Object distance in lateral direction";
CM_ SG_ 66 VFC_Obj12A_ProbMovingLong "Probability of object moving longitudinally";
CM_ SG_ 66 VFC_Obj12A_VxStdDev "Standard deviation of Object velocity in longitudinal direction";
CM_ SG_ 66 VFC_Obj12A_HeadingAngleStdDev "Standard deviation of object Heading angle";
CM_ SG_ 66 VFC_Obj12A_VyStdDev "Standard deviation of Object velocity in lateral direction";
CM_ SG_ 66 VFC_Obj12A_HeightStdDev "Standard deviation of object height";
CM_ SG_ 66 VFC_Obj12A_Height "Height of the object";
CM_ SG_ 66 VFC_Obj12A_Length "Length of the object";
CM_ SG_ 66 VFC_Obj12A_HeadingAngle "Heading angle of the object";
CM_ SG_ 66 VFC_Obj12A_NormAx "Normalised Object acceleration in longitudinal direction";
CM_ SG_ 66 VFC_Obj12A_NormVyEdgeLeftStdDev "Standard deviation of Normalised velocity of the ACCS left object edge in lateral direction";
CM_ SG_ 66 VFC_Obj12A_NormVyEdgeLeft "Normalised velocity of the ACCS left object edge in lateral direction";
CM_ SG_ 66 VFC_Obj12A_EdgeBottom "In ACCS coordinates; corresponds to tan(viewing angle of bottom object edge)";
CM_ SG_ 66 VFC_Obj12A_NormVyEdgeRight "Normalised velocity of the ACCS right object edge in lateral direction";
CM_ SG_ 66 VFC_Obj12A_Width "Width of the object";
CM_ SG_ 66 VFC_Obj12A_NormVx "Normalised Object velocity in longitudinal direction";
CM_ SG_ 66 VFC_Obj12A_NormVyEdgeRightStdDev "Standard deviation of Normalised velocity of the ACCS right object edge in lateral direction";
CM_ SG_ 66 VFC_Obj12A_NormAxStdDev "Standard deviation of Normalised Object acceleration in longitudinal direction";
CM_ SG_ 66 VFC_Obj12A_ScaleChange "A scale change of of the detected object";
CM_ SG_ 66 VFC_Obj12A_ScaleChngStdDev "Standard deviation of object scale change";
CM_ SG_ 66 VFC_Obj12A_Reliability "The bitfield shows if the signal quality is assumed to be sufficient for functions with safety target -no false positives-
Bit 0: DYNAMIC
Bit 1: SEMSEG_SURFACE
Bit 2: WDD_CRITICAL
Bit 3: GOD_CONFIRMED
Bit 4: RESTRICTED
Bit 5: ISO26262_SAFE";
CM_ SG_ 66 VFC_Obj12A_NormVxStdDev "Standard deviation of Normalised Object velocity in longitudinal direction";
CM_ SG_ 66 VFC_Obj12A_TypeProb "Probability of the classified object type";
CM_ SG_ 66 VFC_Obj12A_LengthStdDev "Standard deviation of object length";
CM_ SG_ 66 VFC_Obj12A_WidthStdDev "Standard deviation of object width";
CM_ SG_ 66 VFC_Obj12A_EdgeMid "In ACCS coordinates; corresponds to tan(viewing angle of middle object edge)";
CM_ SG_ 66 VFC_Obj12A_EdgeLeft "In ACCS coordinates; corresponds to tan(viewing angle of left object edge)";
CM_ SG_ 66 VFC_Obj12A_EdgeRight "In ACCS coordinates; corresponds to tan(viewing angle of right object edge)";
CM_ SG_ 66 VFC_Obj12A_VisibleView "The visible view of the detected object";
CM_ SG_ 66 VFC_Obj12A_EdgeLeftStdDev "Standard deviation of the ACCS left object edge";
CM_ SG_ 66 VFC_Obj12A_EdgeTop "In ACCS coordinates; corresponds to tan(viewing angle of top object edge)";
CM_ SG_ 66 VFC_Obj12A_HeadOrientation "The orientation of the head of cyclists or pedestrians that are detected";
CM_ SG_ 66 VFC_Obj12A_EdgeMidStdDev "Standard deviation of the ACCS middle object edge";
CM_ SG_ 66 VFC_Obj12A_EdgeRightStdDev "Standard deviation of the ACCS right object edge";
CM_ SG_ 66 VFC_Obj12A_EdgeTopStdDev "Standard deviation of the ACCS top object edge";
CM_ SG_ 66 VFC_Obj12A_EdgeBottomStdDev "Standard deviation of the ACCS bottom object edge";
CM_ SG_ 66 VFC_Obj12A_ClassifiedView "The classified view of object to be used in connection with Heading angle";
BA_DEF_ SG_  "GenSigSendType" ENUM  "Cyclic","OnWrite","OnWriteWithRepetition","OnChange","OnChangeWithRepetition","IfActive","IfActiveWithRepetition";
BA_DEF_ BO_  "GenMsgCycleTimeFast" INT 2 50000;
BA_DEF_ BO_  "GenMsgILSupport" ENUM  "No","Yes";
BA_DEF_ BU_  "NodeLayerModules" STRING ;
BA_DEF_ BU_  "ILUsed" ENUM  "No","Yes";
BA_DEF_  "NmBaseAddress" HEX 1024 1087;
BA_DEF_ BO_  "CANFD_BRS" ENUM  "0","1";
BA_DEF_ BO_  "GenMsgCycleTime" INT 0 65535;
BA_DEF_ BO_  "GenMsgSendType" ENUM  "Event","cyclic";
BA_DEF_ BO_  "VFrameFormat" ENUM  "StandardCAN","ExtendedCAN","reserved","reserved","reserved","reserved","reserved","reserved","reserved","reserved","reserved","reserved","reserved","reserved","StandardCAN_FD","ExtendedCAN_FD";
BA_DEF_ SG_  "GenSigStartValue" FLOAT 0 100000000000;
BA_DEF_  "BusType" STRING ;
BA_DEF_  "DBName" STRING ;
BA_DEF_DEF_  "GenSigSendType" "Cyclic";
BA_DEF_DEF_  "GenMsgCycleTimeFast" 100;
BA_DEF_DEF_  "GenMsgILSupport" "Yes";
BA_DEF_DEF_  "NodeLayerModules" "CANoeILNLVector.dll";
BA_DEF_DEF_  "ILUsed" "Yes";
BA_DEF_DEF_  "NmBaseAddress" 1024;
BA_DEF_DEF_  "CANFD_BRS" "1";
BA_DEF_DEF_  "GenMsgCycleTime" 0;
BA_DEF_DEF_  "GenMsgSendType" "";
BA_DEF_DEF_  "VFrameFormat" "";
BA_DEF_DEF_  "GenSigStartValue" 0;
BA_DEF_DEF_  "BusType" "";
BA_DEF_DEF_  "DBName" "ChooseYourNameHere";
BA_ "BusType" "CAN FD";
BA_ "DBName" "OD_3R1V_RFC_VFC_RFL_RFR";
BA_ "GenMsgSendType" BO_ 16 0;
BA_ "VFrameFormat" BO_ 16 14;
BA_ "GenMsgSendType" BO_ 19 0;
BA_ "VFrameFormat" BO_ 19 14;
BA_ "GenMsgSendType" BO_ 20 0;
BA_ "VFrameFormat" BO_ 20 14;
BA_ "GenMsgSendType" BO_ 32 0;
BA_ "VFrameFormat" BO_ 32 14;
BA_ "GenMsgSendType" BO_ 35 1;
BA_ "GenMsgCycleTime" BO_ 35 50;
BA_ "VFrameFormat" BO_ 35 14;
BA_ "GenMsgSendType" BO_ 36 1;
BA_ "GenMsgCycleTime" BO_ 36 50;
BA_ "VFrameFormat" BO_ 36 14;
BA_ "GenMsgSendType" BO_ 52 0;
BA_ "VFrameFormat" BO_ 52 14;
BA_ "GenMsgSendType" BO_ 54 0;
BA_ "VFrameFormat" BO_ 54 14;
BA_ "GenMsgSendType" BO_ 55 0;
BA_ "VFrameFormat" BO_ 55 14;
BA_ "GenMsgSendType" BO_ 56 0;
BA_ "VFrameFormat" BO_ 56 14;
BA_ "GenMsgSendType" BO_ 57 0;
BA_ "VFrameFormat" BO_ 57 14;
BA_ "GenMsgSendType" BO_ 58 0;
BA_ "VFrameFormat" BO_ 58 14;
BA_ "GenMsgSendType" BO_ 59 0;
BA_ "VFrameFormat" BO_ 59 14;
BA_ "GenMsgSendType" BO_ 60 0;
BA_ "VFrameFormat" BO_ 60 14;
BA_ "GenMsgSendType" BO_ 61 0;
BA_ "VFrameFormat" BO_ 61 14;
BA_ "GenMsgSendType" BO_ 62 0;
BA_ "VFrameFormat" BO_ 62 14;
BA_ "GenMsgSendType" BO_ 63 0;
BA_ "VFrameFormat" BO_ 63 14;
BA_ "GenMsgSendType" BO_ 64 0;
BA_ "VFrameFormat" BO_ 64 14;
BA_ "GenMsgSendType" BO_ 65 0;
BA_ "VFrameFormat" BO_ 65 14;
BA_ "GenMsgSendType" BO_ 66 0;
BA_ "VFrameFormat" BO_ 66 14;
BA_ "GenSigStartValue" SG_ 16 VFC_Ax_CommandValue 834;
BA_ "GenSigStartValue" SG_ 19 RFL_Ax_CommandValue 834;
BA_ "GenSigStartValue" SG_ 20 RFR_Ax_CommandValue 834;
BA_ "GenSigStartValue" SG_ 32 VFC_GlobalHdr_ProtocolVersion 4;
BA_ "GenSigStartValue" SG_ 32 VFC_GlobalHdr_MountPosX 4096;
BA_ "GenSigStartValue" SG_ 32 VFC_GlobalHdr_MountPosY 2048;
BA_ "GenSigStartValue" SG_ 32 VFC_GlobalHdr_CalibYawAngle 512;
BA_ "GenSigStartValue" SG_ 32 VFC_GlobalHdr_CalibPitchAngle 512;
BA_ "GenSigStartValue" SG_ 32 VFC_GlobalHdr_CalibRollAngle 512;
BA_ "GenSigStartValue" SG_ 54 VFC_Obj00A_Dy 8000;
BA_ "GenSigStartValue" SG_ 54 VFC_Obj00A_Vx 1540;
BA_ "GenSigStartValue" SG_ 54 VFC_Obj00A_Vy 500;
BA_ "GenSigStartValue" SG_ 54 VFC_Obj00A_Ax 160;
BA_ "GenSigStartValue" SG_ 54 VFC_Obj00A_Ay 120;
BA_ "GenSigStartValue" SG_ 54 VFC_Obj00A_HeadingAngle 157;
BA_ "GenSigStartValue" SG_ 54 VFC_Obj00A_NormAx 5000;
BA_ "GenSigStartValue" SG_ 54 VFC_Obj00A_NormVyEdgeLeft 4000;
BA_ "GenSigStartValue" SG_ 54 VFC_Obj00A_EdgeBottom 2000;
BA_ "GenSigStartValue" SG_ 54 VFC_Obj00A_NormVyEdgeRight 4000;
BA_ "GenSigStartValue" SG_ 54 VFC_Obj00A_NormVx 40000;
BA_ "GenSigStartValue" SG_ 54 VFC_Obj00A_EdgeMid 4000;
BA_ "GenSigStartValue" SG_ 54 VFC_Obj00A_EdgeLeft 4000;
BA_ "GenSigStartValue" SG_ 54 VFC_Obj00A_EdgeRight 4000;
BA_ "GenSigStartValue" SG_ 54 VFC_Obj00A_EdgeTop 2000;
BA_ "GenSigStartValue" SG_ 55 VFC_Obj01A_Dy 8000;
BA_ "GenSigStartValue" SG_ 55 VFC_Obj01A_Vx 1540;
BA_ "GenSigStartValue" SG_ 55 VFC_Obj01A_Vy 500;
BA_ "GenSigStartValue" SG_ 55 VFC_Obj01A_Ax 160;
BA_ "GenSigStartValue" SG_ 55 VFC_Obj01A_Ay 120;
BA_ "GenSigStartValue" SG_ 55 VFC_Obj01A_HeadingAngle 157;
BA_ "GenSigStartValue" SG_ 55 VFC_Obj01A_NormAx 5000;
BA_ "GenSigStartValue" SG_ 55 VFC_Obj01A_NormVyEdgeLeft 4000;
BA_ "GenSigStartValue" SG_ 55 VFC_Obj01A_EdgeBottom 2000;
BA_ "GenSigStartValue" SG_ 55 VFC_Obj01A_NormVyEdgeRight 4000;
BA_ "GenSigStartValue" SG_ 55 VFC_Obj01A_NormVx 40000;
BA_ "GenSigStartValue" SG_ 55 VFC_Obj01A_EdgeMid 4000;
BA_ "GenSigStartValue" SG_ 55 VFC_Obj01A_EdgeLeft 4000;
BA_ "GenSigStartValue" SG_ 55 VFC_Obj01A_EdgeRight 4000;
BA_ "GenSigStartValue" SG_ 55 VFC_Obj01A_EdgeTop 2000;
BA_ "GenSigStartValue" SG_ 56 VFC_Obj02A_Dy 8000;
BA_ "GenSigStartValue" SG_ 56 VFC_Obj02A_Vx 1540;
BA_ "GenSigStartValue" SG_ 56 VFC_Obj02A_Vy 500;
BA_ "GenSigStartValue" SG_ 56 VFC_Obj02A_Ax 160;
BA_ "GenSigStartValue" SG_ 56 VFC_Obj02A_Ay 120;
BA_ "GenSigStartValue" SG_ 56 VFC_Obj02A_HeadingAngle 157;
BA_ "GenSigStartValue" SG_ 56 VFC_Obj02A_NormAx 5000;
BA_ "GenSigStartValue" SG_ 56 VFC_Obj02A_NormVyEdgeLeft 4000;
BA_ "GenSigStartValue" SG_ 56 VFC_Obj02A_EdgeBottom 2000;
BA_ "GenSigStartValue" SG_ 56 VFC_Obj02A_NormVyEdgeRight 4000;
BA_ "GenSigStartValue" SG_ 56 VFC_Obj02A_NormVx 40000;
BA_ "GenSigStartValue" SG_ 56 VFC_Obj02A_EdgeMid 4000;
BA_ "GenSigStartValue" SG_ 56 VFC_Obj02A_EdgeLeft 4000;
BA_ "GenSigStartValue" SG_ 56 VFC_Obj02A_EdgeRight 4000;
BA_ "GenSigStartValue" SG_ 56 VFC_Obj02A_EdgeTop 2000;
BA_ "GenSigStartValue" SG_ 57 VFC_Obj03A_Dy 8000;
BA_ "GenSigStartValue" SG_ 57 VFC_Obj03A_Vx 1540;
BA_ "GenSigStartValue" SG_ 57 VFC_Obj03A_Vy 500;
BA_ "GenSigStartValue" SG_ 57 VFC_Obj03A_Ax 160;
BA_ "GenSigStartValue" SG_ 57 VFC_Obj03A_Ay 120;
BA_ "GenSigStartValue" SG_ 57 VFC_Obj03A_HeadingAngle 157;
BA_ "GenSigStartValue" SG_ 57 VFC_Obj03A_NormAx 5000;
BA_ "GenSigStartValue" SG_ 57 VFC_Obj03A_NormVyEdgeLeft 4000;
BA_ "GenSigStartValue" SG_ 57 VFC_Obj03A_EdgeBottom 2000;
BA_ "GenSigStartValue" SG_ 57 VFC_Obj03A_NormVyEdgeRight 4000;
BA_ "GenSigStartValue" SG_ 57 VFC_Obj03A_NormVx 40000;
BA_ "GenSigStartValue" SG_ 57 VFC_Obj03A_EdgeMid 4000;
BA_ "GenSigStartValue" SG_ 57 VFC_Obj03A_EdgeLeft 4000;
BA_ "GenSigStartValue" SG_ 57 VFC_Obj03A_EdgeRight 4000;
BA_ "GenSigStartValue" SG_ 57 VFC_Obj03A_EdgeTop 2000;
BA_ "GenSigStartValue" SG_ 58 VFC_Obj04A_Dy 8000;
BA_ "GenSigStartValue" SG_ 58 VFC_Obj04A_Vx 1540;
BA_ "GenSigStartValue" SG_ 58 VFC_Obj04A_Vy 500;
BA_ "GenSigStartValue" SG_ 58 VFC_Obj04A_Ax 160;
BA_ "GenSigStartValue" SG_ 58 VFC_Obj04A_Ay 120;
BA_ "GenSigStartValue" SG_ 58 VFC_Obj04A_HeadingAngle 157;
BA_ "GenSigStartValue" SG_ 58 VFC_Obj04A_NormAx 5000;
BA_ "GenSigStartValue" SG_ 58 VFC_Obj04A_NormVyEdgeLeft 4000;
BA_ "GenSigStartValue" SG_ 58 VFC_Obj04A_EdgeBottom 2000;
BA_ "GenSigStartValue" SG_ 58 VFC_Obj04A_NormVyEdgeRight 4000;
BA_ "GenSigStartValue" SG_ 58 VFC_Obj04A_NormVx 40000;
BA_ "GenSigStartValue" SG_ 58 VFC_Obj04A_EdgeMid 4000;
BA_ "GenSigStartValue" SG_ 58 VFC_Obj04A_EdgeLeft 4000;
BA_ "GenSigStartValue" SG_ 58 VFC_Obj04A_EdgeRight 4000;
BA_ "GenSigStartValue" SG_ 58 VFC_Obj04A_EdgeTop 2000;
BA_ "GenSigStartValue" SG_ 59 VFC_Obj05A_Dy 8000;
BA_ "GenSigStartValue" SG_ 59 VFC_Obj05A_Vx 1540;
BA_ "GenSigStartValue" SG_ 59 VFC_Obj05A_Vy 500;
BA_ "GenSigStartValue" SG_ 59 VFC_Obj05A_Ax 160;
BA_ "GenSigStartValue" SG_ 59 VFC_Obj05A_Ay 120;
BA_ "GenSigStartValue" SG_ 59 VFC_Obj05A_HeadingAngle 157;
BA_ "GenSigStartValue" SG_ 59 VFC_Obj05A_NormAx 5000;
BA_ "GenSigStartValue" SG_ 59 VFC_Obj05A_NormVyEdgeLeft 4000;
BA_ "GenSigStartValue" SG_ 59 VFC_Obj05A_EdgeBottom 2000;
BA_ "GenSigStartValue" SG_ 59 VFC_Obj05A_NormVyEdgeRight 4000;
BA_ "GenSigStartValue" SG_ 59 VFC_Obj05A_NormVx 40000;
BA_ "GenSigStartValue" SG_ 59 VFC_Obj05A_EdgeMid 4000;
BA_ "GenSigStartValue" SG_ 59 VFC_Obj05A_EdgeLeft 4000;
BA_ "GenSigStartValue" SG_ 59 VFC_Obj05A_EdgeRight 4000;
BA_ "GenSigStartValue" SG_ 59 VFC_Obj05A_EdgeTop 2000;
BA_ "GenSigStartValue" SG_ 60 VFC_Obj06A_Dy 8000;
BA_ "GenSigStartValue" SG_ 60 VFC_Obj06A_Vx 1540;
BA_ "GenSigStartValue" SG_ 60 VFC_Obj06A_Vy 500;
BA_ "GenSigStartValue" SG_ 60 VFC_Obj06A_Ax 160;
BA_ "GenSigStartValue" SG_ 60 VFC_Obj06A_Ay 120;
BA_ "GenSigStartValue" SG_ 60 VFC_Obj06A_HeadingAngle 157;
BA_ "GenSigStartValue" SG_ 60 VFC_Obj06A_NormAx 5000;
BA_ "GenSigStartValue" SG_ 60 VFC_Obj06A_NormVyEdgeLeft 4000;
BA_ "GenSigStartValue" SG_ 60 VFC_Obj06A_EdgeBottom 2000;
BA_ "GenSigStartValue" SG_ 60 VFC_Obj06A_NormVyEdgeRight 4000;
BA_ "GenSigStartValue" SG_ 60 VFC_Obj06A_NormVx 40000;
BA_ "GenSigStartValue" SG_ 60 VFC_Obj06A_EdgeMid 4000;
BA_ "GenSigStartValue" SG_ 60 VFC_Obj06A_EdgeLeft 4000;
BA_ "GenSigStartValue" SG_ 60 VFC_Obj06A_EdgeRight 4000;
BA_ "GenSigStartValue" SG_ 60 VFC_Obj06A_EdgeTop 2000;
BA_ "GenSigStartValue" SG_ 61 VFC_Obj07A_Dy 8000;
BA_ "GenSigStartValue" SG_ 61 VFC_Obj07A_Vx 1540;
BA_ "GenSigStartValue" SG_ 61 VFC_Obj07A_Vy 500;
BA_ "GenSigStartValue" SG_ 61 VFC_Obj07A_Ax 160;
BA_ "GenSigStartValue" SG_ 61 VFC_Obj07A_Ay 120;
BA_ "GenSigStartValue" SG_ 61 VFC_Obj07A_HeadingAngle 157;
BA_ "GenSigStartValue" SG_ 61 VFC_Obj07A_NormAx 5000;
BA_ "GenSigStartValue" SG_ 61 VFC_Obj07A_NormVyEdgeLeft 4000;
BA_ "GenSigStartValue" SG_ 61 VFC_Obj07A_EdgeBottom 2000;
BA_ "GenSigStartValue" SG_ 61 VFC_Obj07A_NormVyEdgeRight 4000;
BA_ "GenSigStartValue" SG_ 61 VFC_Obj07A_NormVx 40000;
BA_ "GenSigStartValue" SG_ 61 VFC_Obj07A_EdgeMid 4000;
BA_ "GenSigStartValue" SG_ 61 VFC_Obj07A_EdgeLeft 4000;
BA_ "GenSigStartValue" SG_ 61 VFC_Obj07A_EdgeRight 4000;
BA_ "GenSigStartValue" SG_ 61 VFC_Obj07A_EdgeTop 2000;
BA_ "GenSigStartValue" SG_ 62 VFC_Obj08A_Dy 8000;
BA_ "GenSigStartValue" SG_ 62 VFC_Obj08A_Vx 1540;
BA_ "GenSigStartValue" SG_ 62 VFC_Obj08A_Vy 500;
BA_ "GenSigStartValue" SG_ 62 VFC_Obj08A_Ax 160;
BA_ "GenSigStartValue" SG_ 62 VFC_Obj08A_Ay 120;
BA_ "GenSigStartValue" SG_ 62 VFC_Obj08A_HeadingAngle 157;
BA_ "GenSigStartValue" SG_ 62 VFC_Obj08A_NormAx 5000;
BA_ "GenSigStartValue" SG_ 62 VFC_Obj08A_NormVyEdgeLeft 4000;
BA_ "GenSigStartValue" SG_ 62 VFC_Obj08A_EdgeBottom 2000;
BA_ "GenSigStartValue" SG_ 62 VFC_Obj08A_NormVyEdgeRight 4000;
BA_ "GenSigStartValue" SG_ 62 VFC_Obj08A_NormVx 40000;
BA_ "GenSigStartValue" SG_ 62 VFC_Obj08A_EdgeMid 4000;
BA_ "GenSigStartValue" SG_ 62 VFC_Obj08A_EdgeLeft 4000;
BA_ "GenSigStartValue" SG_ 62 VFC_Obj08A_EdgeRight 4000;
BA_ "GenSigStartValue" SG_ 62 VFC_Obj08A_EdgeTop 2000;
BA_ "GenSigStartValue" SG_ 63 VFC_Obj09A_Dy 8000;
BA_ "GenSigStartValue" SG_ 63 VFC_Obj09A_Vx 1540;
BA_ "GenSigStartValue" SG_ 63 VFC_Obj09A_Vy 500;
BA_ "GenSigStartValue" SG_ 63 VFC_Obj09A_Ax 160;
BA_ "GenSigStartValue" SG_ 63 VFC_Obj09A_Ay 120;
BA_ "GenSigStartValue" SG_ 63 VFC_Obj09A_HeadingAngle 157;
BA_ "GenSigStartValue" SG_ 63 VFC_Obj09A_NormAx 5000;
BA_ "GenSigStartValue" SG_ 63 VFC_Obj09A_NormVyEdgeLeft 4000;
BA_ "GenSigStartValue" SG_ 63 VFC_Obj09A_EdgeBottom 2000;
BA_ "GenSigStartValue" SG_ 63 VFC_Obj09A_NormVyEdgeRight 4000;
BA_ "GenSigStartValue" SG_ 63 VFC_Obj09A_NormVx 40000;
BA_ "GenSigStartValue" SG_ 63 VFC_Obj09A_EdgeMid 4000;
BA_ "GenSigStartValue" SG_ 63 VFC_Obj09A_EdgeLeft 4000;
BA_ "GenSigStartValue" SG_ 63 VFC_Obj09A_EdgeRight 4000;
BA_ "GenSigStartValue" SG_ 63 VFC_Obj09A_EdgeTop 2000;
BA_ "GenSigStartValue" SG_ 64 VFC_Obj10A_Dy 8000;
BA_ "GenSigStartValue" SG_ 64 VFC_Obj10A_Vx 1540;
BA_ "GenSigStartValue" SG_ 64 VFC_Obj10A_Vy 500;
BA_ "GenSigStartValue" SG_ 64 VFC_Obj10A_Ax 160;
BA_ "GenSigStartValue" SG_ 64 VFC_Obj10A_Ay 120;
BA_ "GenSigStartValue" SG_ 64 VFC_Obj10A_HeadingAngle 157;
BA_ "GenSigStartValue" SG_ 64 VFC_Obj10A_NormAx 5000;
BA_ "GenSigStartValue" SG_ 64 VFC_Obj10A_NormVyEdgeLeft 4000;
BA_ "GenSigStartValue" SG_ 64 VFC_Obj10A_EdgeBottom 2000;
BA_ "GenSigStartValue" SG_ 64 VFC_Obj10A_NormVyEdgeRight 4000;
BA_ "GenSigStartValue" SG_ 64 VFC_Obj10A_NormVx 40000;
BA_ "GenSigStartValue" SG_ 64 VFC_Obj10A_EdgeMid 4000;
BA_ "GenSigStartValue" SG_ 64 VFC_Obj10A_EdgeLeft 4000;
BA_ "GenSigStartValue" SG_ 64 VFC_Obj10A_EdgeRight 4000;
BA_ "GenSigStartValue" SG_ 64 VFC_Obj10A_EdgeTop 2000;
BA_ "GenSigStartValue" SG_ 65 VFC_Obj11A_Dy 8000;
BA_ "GenSigStartValue" SG_ 65 VFC_Obj11A_Vx 1540;
BA_ "GenSigStartValue" SG_ 65 VFC_Obj11A_Vy 500;
BA_ "GenSigStartValue" SG_ 65 VFC_Obj11A_Ax 160;
BA_ "GenSigStartValue" SG_ 65 VFC_Obj11A_Ay 120;
BA_ "GenSigStartValue" SG_ 65 VFC_Obj11A_HeadingAngle 157;
BA_ "GenSigStartValue" SG_ 65 VFC_Obj11A_NormAx 5000;
BA_ "GenSigStartValue" SG_ 65 VFC_Obj11A_NormVyEdgeLeft 4000;
BA_ "GenSigStartValue" SG_ 65 VFC_Obj11A_EdgeBottom 2000;
BA_ "GenSigStartValue" SG_ 65 VFC_Obj11A_NormVyEdgeRight 4000;
BA_ "GenSigStartValue" SG_ 65 VFC_Obj11A_NormVx 40000;
BA_ "GenSigStartValue" SG_ 65 VFC_Obj11A_EdgeMid 4000;
BA_ "GenSigStartValue" SG_ 65 VFC_Obj11A_EdgeLeft 4000;
BA_ "GenSigStartValue" SG_ 65 VFC_Obj11A_EdgeRight 4000;
BA_ "GenSigStartValue" SG_ 65 VFC_Obj11A_EdgeTop 2000;
BA_ "GenSigStartValue" SG_ 66 VFC_Obj12A_Dy 8000;
BA_ "GenSigStartValue" SG_ 66 VFC_Obj12A_Vx 1540;
BA_ "GenSigStartValue" SG_ 66 VFC_Obj12A_Vy 500;
BA_ "GenSigStartValue" SG_ 66 VFC_Obj12A_Ax 160;
BA_ "GenSigStartValue" SG_ 66 VFC_Obj12A_Ay 120;
BA_ "GenSigStartValue" SG_ 66 VFC_Obj12A_HeadingAngle 157;
BA_ "GenSigStartValue" SG_ 66 VFC_Obj12A_NormAx 5000;
BA_ "GenSigStartValue" SG_ 66 VFC_Obj12A_NormVyEdgeLeft 4000;
BA_ "GenSigStartValue" SG_ 66 VFC_Obj12A_EdgeBottom 2000;
BA_ "GenSigStartValue" SG_ 66 VFC_Obj12A_NormVyEdgeRight 4000;
BA_ "GenSigStartValue" SG_ 66 VFC_Obj12A_NormVx 40000;
BA_ "GenSigStartValue" SG_ 66 VFC_Obj12A_EdgeMid 4000;
BA_ "GenSigStartValue" SG_ 66 VFC_Obj12A_EdgeLeft 4000;
BA_ "GenSigStartValue" SG_ 66 VFC_Obj12A_EdgeRight 4000;
BA_ "GenSigStartValue" SG_ 66 VFC_Obj12A_EdgeTop 2000;
VAL_ 3221225472 RFC_Status_ModulationStatus 0 "Normal operation" 1 "Time sync failure" 2 "Modulation failure" 3 "Reserved" ;
VAL_ 32 VFC_GlobalHdr_TrafficFlowType 0 "Right_Hand_Traffic" 1 "Left_Hand_Traffic" ;
VAL_ 32 VFC_GlobalHdr_SensorState 0 "Camera Operational" 1 "Camera Initialization" 2 "Camera Limited (reduced Mode)" 3 "Camera Dirty" 4 "Camera Blocked" 5 "Camera Error" 6 "Camera Calibration" 7 "Camera Decalibrated" 8 "Camera Shutdown Initiated" 9 "Camera Enter Sleep" 10 "Reserved10" 11 "Reserved11" 12 "Reserved12" 13 "Reserved13" 14 "Reserved14" 15 "Reserved15" ;
VAL_ 32 VFC_GlobalHdr_DsmState 0 "Invalid" 1 "Initialization" 2 "Sys_Not_Operational" 3 "Hw_Full_Operational" 4 "SCAL" 5 "IOCAL" 6 "LIMITED" 7 "Sys_Full_Operational" 8 "Parking" 9 "Full_Shutdown" 10 "Fast_Shutdown" 11 "Sleep" 12 "Reserved12" 13 "Reserved13" 14 "Reserved14" 15 "Reserved15" ;
VAL_ 32 VFC_GlobalHdr_CalibState 0 "Fully Calibrated" 1 "Not Calibrated" 2 "Yaw Not Calibrated" 3 "Pitch Not Calibrated" 4 "Roll Not Calibrated" 5 "Reserved5" 6 "Reserved6" 7 "Reserved7" ;
VAL_ 32 VFC_GlobalHdr_StmState 0 "NOT_IN_STM" 1 "Initialization" 2 "Safe_Island" 3 "HW_Operational" 4 "Parking_Mode" 5 "Reserved5" 6 "Reserved6" 7 "Reserved7" ;
VAL_ 32 VFC_GlobalHdr_RollerBenchState 0 "no_roller_bench_mode" 1 "generic_roller_bench_mode" 2 "full_performance_roller_bench_mode" 3 "Reserved3" ;
VAL_ 35 RFL_Status_SensorState 0 "SENSOR FULLY OPERATIONAL" 1 "HW MALFUNCTION" 2 "DSP ISSUES" 3 "COMMUNICATION ERRORS" 4 "MISALIGNMENT (OUT OF SPEC)" 5 "SENSOR BLIDNESS DETECTED" 6 "SENSOR DISTUBED" 7 "OTHER ISSUES" 8 "DEGRADED BY REQUEST" 9 "RESERVED1" 10 "RESERVED2" 11 "RESERVED3" 12 "RESERVED4" 13 "RESERVED5" 14 "RESERVED6" 15 "INVALID" ;
VAL_ 35 RFL_Status_ModulationStatus 0 "Normal operation" 1 "Time sync failure" 2 "Modulation failure" 3 "Reserved" ;
VAL_ 36 RFR_Status_SensorState 0 "SENSOR FULLY OPERATIONAL" 1 "HW MALFUNCTION" 2 "DSP ISSUES" 3 "COMMUNICATION ERRORS" 4 "MISALIGNMENT (OUT OF SPEC)" 5 "SENSOR BLIDNESS DETECTED" 6 "SENSOR DISTUBED" 7 "OTHER ISSUES" 8 "DEGRADED BY REQUEST" 9 "RESERVED1" 10 "RESERVED2" 11 "RESERVED3" 12 "RESERVED4" 13 "RESERVED5" 14 "RESERVED6" 15 "INVALID" ;
VAL_ 36 RFR_Status_ModulationStatus 0 "Normal operation" 1 "Time sync failure" 2 "Modulation failure" 3 "Reserved" ;
VAL_ 52 VFC_ObjHdr_State 0 "off" 1 "on" 2 "Reduced" 3 "HW_Error" 4 "SW_Error" 5 "FID_Active" 6 "Reserved6" 7 "Reserved7" ;
VAL_ 54 VFC_Obj00A_ID 0 "INVALID" ;
VAL_ 54 VFC_Obj00A_Type 0 "NOTYPE" 1 "CAR" 2 "RESERVED02" 3 "TRUCK" 4 "RESERVED04" 5 "RESERVED05" 6 "MOTORCYCLIST" 7 "PEDESTRIAN" 8 "CYCLIST" 9 "BOLLARD" 10 "ROADPOST" 11 "ARROWPOST" 12 "RESERVED12" 13 "RESERVED13" 14 "RESERVED14" 15 "RESERVED15" ;
VAL_ 54 VFC_Obj00A_Measured 0 "Invalid" 1 "Measured" 2 "Predicted" 3 "Reserved3" ;
VAL_ 54 VFC_Obj00A_DirIndicator 0 "Unknown" 1 "No direction indicator" 2 "Left indicator" 3 "Right indicator" 4 "Warning Lights" ;
VAL_ 54 VFC_Obj00A_BrakeLight 0 "Unknown" 1 "No light detected" 2 "One light detected" 3 "Two lights detected" 4 "Three lights detected" 5 "Reserved5" 6 "Reserved6" 7 "Reserved7" ;
VAL_ 54 VFC_Obj00A_CompletelyInImg 0 "not completely measured" 1 "completely measured" ;
VAL_ 54 VFC_Obj00A_VisibleView 0 "UNKNOWN" 1 "CLASSIC" 2 "SIDE" 3 "CLASSIC_SIDE" 4 "SIDE_CLASSIC" ;
VAL_ 54 VFC_Obj00A_HeadOrientation 0 "N/A" 1 "Head front" 2 "Head left front" 3 "Head left" 4 "Head left back" 5 "Head back" 6 "Head right back" 7 "Head right" 8 "Head right front" 9 "Reserved09" 10 "Reserved10" 11 "Reserved11" 12 "Reserved12" 13 "Reserved13" 14 "Reserved14" 15 "Unknown" ;
VAL_ 54 VFC_Obj00A_ClassifiedView 0 "Unknown" 1 "Front" 2 "Rear" 3 "Left" 4 "Right" ;
VAL_ 55 VFC_Obj01A_ID 0 "INVALID" ;
VAL_ 55 VFC_Obj01A_Type 0 "NOTYPE" 1 "CAR" 2 "RESERVED02" 3 "TRUCK" 4 "RESERVED04" 5 "RESERVED05" 6 "MOTORCYCLIST" 7 "PEDESTRIAN" 8 "CYCLIST" 9 "BOLLARD" 10 "ROADPOST" 11 "ARROWPOST" 12 "RESERVED12" 13 "RESERVED13" 14 "RESERVED14" 15 "RESERVED15" ;
VAL_ 55 VFC_Obj01A_Measured 0 "Invalid" 1 "Measured" 2 "Predicted" 3 "Reserved3" ;
VAL_ 55 VFC_Obj01A_DirIndicator 0 "Unknown" 1 "No direction indicator" 2 "Left indicator" 3 "Right indicator" 4 "Warning Lights" ;
VAL_ 55 VFC_Obj01A_BrakeLight 0 "Unknown" 1 "No light detected" 2 "One light detected" 3 "Two lights detected" 4 "Three lights detected" 5 "Reserved5" 6 "Reserved6" 7 "Reserved7" ;
VAL_ 55 VFC_Obj01A_CompletelyInImg 0 "not completely measured" 1 "completely measured" ;
VAL_ 55 VFC_Obj01A_VisibleView 0 "UNKNOWN" 1 "CLASSIC" 2 "SIDE" 3 "CLASSIC_SIDE" 4 "SIDE_CLASSIC" ;
VAL_ 55 VFC_Obj01A_HeadOrientation 0 "N/A" 1 "Head front" 2 "Head left front" 3 "Head left" 4 "Head left back" 5 "Head back" 6 "Head right back" 7 "Head right" 8 "Head right front" 9 "Reserved09" 10 "Reserved10" 11 "Reserved11" 12 "Reserved12" 13 "Reserved13" 14 "Reserved14" 15 "Unknown" ;
VAL_ 55 VFC_Obj01A_ClassifiedView 0 "Unknown" 1 "Front" 2 "Rear" 3 "Left" 4 "Right" ;
VAL_ 56 VFC_Obj02A_ID 0 "INVALID" ;
VAL_ 56 VFC_Obj02A_Type 0 "NOTYPE" 1 "CAR" 2 "RESERVED02" 3 "TRUCK" 4 "RESERVED04" 5 "RESERVED05" 6 "MOTORCYCLIST" 7 "PEDESTRIAN" 8 "CYCLIST" 9 "BOLLARD" 10 "ROADPOST" 11 "ARROWPOST" 12 "RESERVED12" 13 "RESERVED13" 14 "RESERVED14" 15 "RESERVED15" ;
VAL_ 56 VFC_Obj02A_Measured 0 "Invalid" 1 "Measured" 2 "Predicted" 3 "Reserved3" ;
VAL_ 56 VFC_Obj02A_DirIndicator 0 "Unknown" 1 "No direction indicator" 2 "Left indicator" 3 "Right indicator" 4 "Warning Lights" ;
VAL_ 56 VFC_Obj02A_BrakeLight 0 "Unknown" 1 "No light detected" 2 "One light detected" 3 "Two lights detected" 4 "Three lights detected" 5 "Reserved5" 6 "Reserved6" 7 "Reserved7" ;
VAL_ 56 VFC_Obj02A_CompletelyInImg 0 "not completely measured" 1 "completely measured" ;
VAL_ 56 VFC_Obj02A_VisibleView 0 "UNKNOWN" 1 "CLASSIC" 2 "SIDE" 3 "CLASSIC_SIDE" 4 "SIDE_CLASSIC" ;
VAL_ 56 VFC_Obj02A_HeadOrientation 0 "N/A" 1 "Head front" 2 "Head left front" 3 "Head left" 4 "Head left back" 5 "Head back" 6 "Head right back" 7 "Head right" 8 "Head right front" 9 "Reserved09" 10 "Reserved10" 11 "Reserved11" 12 "Reserved12" 13 "Reserved13" 14 "Reserved14" 15 "Unknown" ;
VAL_ 56 VFC_Obj02A_ClassifiedView 0 "Unknown" 1 "Front" 2 "Rear" 3 "Left" 4 "Right" ;
VAL_ 57 VFC_Obj03A_ID 0 "INVALID" ;
VAL_ 57 VFC_Obj03A_Type 0 "NOTYPE" 1 "CAR" 2 "RESERVED02" 3 "TRUCK" 4 "RESERVED04" 5 "RESERVED05" 6 "MOTORCYCLIST" 7 "PEDESTRIAN" 8 "CYCLIST" 9 "BOLLARD" 10 "ROADPOST" 11 "ARROWPOST" 12 "RESERVED12" 13 "RESERVED13" 14 "RESERVED14" 15 "RESERVED15" ;
VAL_ 57 VFC_Obj03A_Measured 0 "Invalid" 1 "Measured" 2 "Predicted" 3 "Reserved3" ;
VAL_ 57 VFC_Obj03A_DirIndicator 0 "Unknown" 1 "No direction indicator" 2 "Left indicator" 3 "Right indicator" 4 "Warning Lights" ;
VAL_ 57 VFC_Obj03A_BrakeLight 0 "Unknown" 1 "No light detected" 2 "One light detected" 3 "Two lights detected" 4 "Three lights detected" 5 "Reserved5" 6 "Reserved6" 7 "Reserved7" ;
VAL_ 57 VFC_Obj03A_CompletelyInImg 0 "not completely measured" 1 "completely measured" ;
VAL_ 57 VFC_Obj03A_VisibleView 0 "UNKNOWN" 1 "CLASSIC" 2 "SIDE" 3 "CLASSIC_SIDE" 4 "SIDE_CLASSIC" ;
VAL_ 57 VFC_Obj03A_HeadOrientation 0 "N/A" 1 "Head front" 2 "Head left front" 3 "Head left" 4 "Head left back" 5 "Head back" 6 "Head right back" 7 "Head right" 8 "Head right front" 9 "Reserved09" 10 "Reserved10" 11 "Reserved11" 12 "Reserved12" 13 "Reserved13" 14 "Reserved14" 15 "Unknown" ;
VAL_ 57 VFC_Obj03A_ClassifiedView 0 "Unknown" 1 "Front" 2 "Rear" 3 "Left" 4 "Right" ;
VAL_ 58 VFC_Obj04A_ID 0 "INVALID" ;
VAL_ 58 VFC_Obj04A_Type 0 "NOTYPE" 1 "CAR" 2 "RESERVED02" 3 "TRUCK" 4 "RESERVED04" 5 "RESERVED05" 6 "MOTORCYCLIST" 7 "PEDESTRIAN" 8 "CYCLIST" 9 "BOLLARD" 10 "ROADPOST" 11 "ARROWPOST" 12 "RESERVED12" 13 "RESERVED13" 14 "RESERVED14" 15 "RESERVED15" ;
VAL_ 58 VFC_Obj04A_Measured 0 "Invalid" 1 "Measured" 2 "Predicted" 3 "Reserved3" ;
VAL_ 58 VFC_Obj04A_DirIndicator 0 "Unknown" 1 "No direction indicator" 2 "Left indicator" 3 "Right indicator" 4 "Warning Lights" ;
VAL_ 58 VFC_Obj04A_BrakeLight 0 "Unknown" 1 "No light detected" 2 "One light detected" 3 "Two lights detected" 4 "Three lights detected" 5 "Reserved5" 6 "Reserved6" 7 "Reserved7" ;
VAL_ 58 VFC_Obj04A_CompletelyInImg 0 "not completely measured" 1 "completely measured" ;
VAL_ 58 VFC_Obj04A_VisibleView 0 "UNKNOWN" 1 "CLASSIC" 2 "SIDE" 3 "CLASSIC_SIDE" 4 "SIDE_CLASSIC" ;
VAL_ 58 VFC_Obj04A_HeadOrientation 0 "N/A" 1 "Head front" 2 "Head left front" 3 "Head left" 4 "Head left back" 5 "Head back" 6 "Head right back" 7 "Head right" 8 "Head right front" 9 "Reserved09" 10 "Reserved10" 11 "Reserved11" 12 "Reserved12" 13 "Reserved13" 14 "Reserved14" 15 "Unknown" ;
VAL_ 58 VFC_Obj04A_ClassifiedView 0 "Unknown" 1 "Front" 2 "Rear" 3 "Left" 4 "Right" ;
VAL_ 59 VFC_Obj05A_ID 0 "INVALID" ;
VAL_ 59 VFC_Obj05A_Type 0 "NOTYPE" 1 "CAR" 2 "RESERVED02" 3 "TRUCK" 4 "RESERVED04" 5 "RESERVED05" 6 "MOTORCYCLIST" 7 "PEDESTRIAN" 8 "CYCLIST" 9 "BOLLARD" 10 "ROADPOST" 11 "ARROWPOST" 12 "RESERVED12" 13 "RESERVED13" 14 "RESERVED14" 15 "RESERVED15" ;
VAL_ 59 VFC_Obj05A_Measured 0 "Invalid" 1 "Measured" 2 "Predicted" 3 "Reserved3" ;
VAL_ 59 VFC_Obj05A_DirIndicator 0 "Unknown" 1 "No direction indicator" 2 "Left indicator" 3 "Right indicator" 4 "Warning Lights" ;
VAL_ 59 VFC_Obj05A_BrakeLight 0 "Unknown" 1 "No light detected" 2 "One light detected" 3 "Two lights detected" 4 "Three lights detected" 5 "Reserved5" 6 "Reserved6" 7 "Reserved7" ;
VAL_ 59 VFC_Obj05A_CompletelyInImg 0 "not completely measured" 1 "completely measured" ;
VAL_ 59 VFC_Obj05A_VisibleView 0 "UNKNOWN" 1 "CLASSIC" 2 "SIDE" 3 "CLASSIC_SIDE" 4 "SIDE_CLASSIC" ;
VAL_ 59 VFC_Obj05A_HeadOrientation 0 "N/A" 1 "Head front" 2 "Head left front" 3 "Head left" 4 "Head left back" 5 "Head back" 6 "Head right back" 7 "Head right" 8 "Head right front" 9 "Reserved09" 10 "Reserved10" 11 "Reserved11" 12 "Reserved12" 13 "Reserved13" 14 "Reserved14" 15 "Unknown" ;
VAL_ 59 VFC_Obj05A_ClassifiedView 0 "Unknown" 1 "Front" 2 "Rear" 3 "Left" 4 "Right" ;
VAL_ 60 VFC_Obj06A_ID 0 "INVALID" ;
VAL_ 60 VFC_Obj06A_Type 0 "NOTYPE" 1 "CAR" 2 "RESERVED02" 3 "TRUCK" 4 "RESERVED04" 5 "RESERVED05" 6 "MOTORCYCLIST" 7 "PEDESTRIAN" 8 "CYCLIST" 9 "BOLLARD" 10 "ROADPOST" 11 "ARROWPOST" 12 "RESERVED12" 13 "RESERVED13" 14 "RESERVED14" 15 "RESERVED15" ;
VAL_ 60 VFC_Obj06A_Measured 0 "Invalid" 1 "Measured" 2 "Predicted" 3 "Reserved3" ;
VAL_ 60 VFC_Obj06A_DirIndicator 0 "Unknown" 1 "No direction indicator" 2 "Left indicator" 3 "Right indicator" 4 "Warning Lights" ;
VAL_ 60 VFC_Obj06A_BrakeLight 0 "Unknown" 1 "No light detected" 2 "One light detected" 3 "Two lights detected" 4 "Three lights detected" 5 "Reserved5" 6 "Reserved6" 7 "Reserved7" ;
VAL_ 60 VFC_Obj06A_CompletelyInImg 0 "not completely measured" 1 "completely measured" ;
VAL_ 60 VFC_Obj06A_VisibleView 0 "UNKNOWN" 1 "CLASSIC" 2 "SIDE" 3 "CLASSIC_SIDE" 4 "SIDE_CLASSIC" ;
VAL_ 60 VFC_Obj06A_HeadOrientation 0 "N/A" 1 "Head front" 2 "Head left front" 3 "Head left" 4 "Head left back" 5 "Head back" 6 "Head right back" 7 "Head right" 8 "Head right front" 9 "Reserved09" 10 "Reserved10" 11 "Reserved11" 12 "Reserved12" 13 "Reserved13" 14 "Reserved14" 15 "Unknown" ;
VAL_ 60 VFC_Obj06A_ClassifiedView 0 "Unknown" 1 "Front" 2 "Rear" 3 "Left" 4 "Right" ;
VAL_ 61 VFC_Obj07A_ID 0 "INVALID" ;
VAL_ 61 VFC_Obj07A_Type 0 "NOTYPE" 1 "CAR" 2 "RESERVED02" 3 "TRUCK" 4 "RESERVED04" 5 "RESERVED05" 6 "MOTORCYCLIST" 7 "PEDESTRIAN" 8 "CYCLIST" 9 "BOLLARD" 10 "ROADPOST" 11 "ARROWPOST" 12 "RESERVED12" 13 "RESERVED13" 14 "RESERVED14" 15 "RESERVED15" ;
VAL_ 61 VFC_Obj07A_Measured 0 "Invalid" 1 "Measured" 2 "Predicted" 3 "Reserved3" ;
VAL_ 61 VFC_Obj07A_DirIndicator 0 "Unknown" 1 "No direction indicator" 2 "Left indicator" 3 "Right indicator" 4 "Warning Lights" ;
VAL_ 61 VFC_Obj07A_BrakeLight 0 "Unknown" 1 "No light detected" 2 "One light detected" 3 "Two lights detected" 4 "Three lights detected" 5 "Reserved5" 6 "Reserved6" 7 "Reserved7" ;
VAL_ 61 VFC_Obj07A_CompletelyInImg 0 "not completely measured" 1 "completely measured" ;
VAL_ 61 VFC_Obj07A_VisibleView 0 "UNKNOWN" 1 "CLASSIC" 2 "SIDE" 3 "CLASSIC_SIDE" 4 "SIDE_CLASSIC" ;
VAL_ 61 VFC_Obj07A_HeadOrientation 0 "N/A" 1 "Head front" 2 "Head left front" 3 "Head left" 4 "Head left back" 5 "Head back" 6 "Head right back" 7 "Head right" 8 "Head right front" 9 "Reserved09" 10 "Reserved10" 11 "Reserved11" 12 "Reserved12" 13 "Reserved13" 14 "Reserved14" 15 "Unknown" ;
VAL_ 61 VFC_Obj07A_ClassifiedView 0 "Unknown" 1 "Front" 2 "Rear" 3 "Left" 4 "Right" ;
VAL_ 62 VFC_Obj08A_ID 0 "INVALID" ;
VAL_ 62 VFC_Obj08A_Type 0 "NOTYPE" 1 "CAR" 2 "RESERVED02" 3 "TRUCK" 4 "RESERVED04" 5 "RESERVED05" 6 "MOTORCYCLIST" 7 "PEDESTRIAN" 8 "CYCLIST" 9 "BOLLARD" 10 "ROADPOST" 11 "ARROWPOST" 12 "RESERVED12" 13 "RESERVED13" 14 "RESERVED14" 15 "RESERVED15" ;
VAL_ 62 VFC_Obj08A_Measured 0 "Invalid" 1 "Measured" 2 "Predicted" 3 "Reserved3" ;
VAL_ 62 VFC_Obj08A_DirIndicator 0 "Unknown" 1 "No direction indicator" 2 "Left indicator" 3 "Right indicator" 4 "Warning Lights" ;
VAL_ 62 VFC_Obj08A_BrakeLight 0 "Unknown" 1 "No light detected" 2 "One light detected" 3 "Two lights detected" 4 "Three lights detected" 5 "Reserved5" 6 "Reserved6" 7 "Reserved7" ;
VAL_ 62 VFC_Obj08A_CompletelyInImg 0 "not completely measured" 1 "completely measured" ;
VAL_ 62 VFC_Obj08A_VisibleView 0 "UNKNOWN" 1 "CLASSIC" 2 "SIDE" 3 "CLASSIC_SIDE" 4 "SIDE_CLASSIC" ;
VAL_ 62 VFC_Obj08A_HeadOrientation 0 "N/A" 1 "Head front" 2 "Head left front" 3 "Head left" 4 "Head left back" 5 "Head back" 6 "Head right back" 7 "Head right" 8 "Head right front" 9 "Reserved09" 10 "Reserved10" 11 "Reserved11" 12 "Reserved12" 13 "Reserved13" 14 "Reserved14" 15 "Unknown" ;
VAL_ 62 VFC_Obj08A_ClassifiedView 0 "Unknown" 1 "Front" 2 "Rear" 3 "Left" 4 "Right" ;
VAL_ 63 VFC_Obj09A_ID 0 "INVALID" ;
VAL_ 63 VFC_Obj09A_Type 0 "NOTYPE" 1 "CAR" 2 "RESERVED02" 3 "TRUCK" 4 "RESERVED04" 5 "RESERVED05" 6 "MOTORCYCLIST" 7 "PEDESTRIAN" 8 "CYCLIST" 9 "BOLLARD" 10 "ROADPOST" 11 "ARROWPOST" 12 "RESERVED12" 13 "RESERVED13" 14 "RESERVED14" 15 "RESERVED15" ;
VAL_ 63 VFC_Obj09A_Measured 0 "Invalid" 1 "Measured" 2 "Predicted" 3 "Reserved3" ;
VAL_ 63 VFC_Obj09A_DirIndicator 0 "Unknown" 1 "No direction indicator" 2 "Left indicator" 3 "Right indicator" 4 "Warning Lights" ;
VAL_ 63 VFC_Obj09A_BrakeLight 0 "Unknown" 1 "No light detected" 2 "One light detected" 3 "Two lights detected" 4 "Three lights detected" 5 "Reserved5" 6 "Reserved6" 7 "Reserved7" ;
VAL_ 63 VFC_Obj09A_CompletelyInImg 0 "not completely measured" 1 "completely measured" ;
VAL_ 63 VFC_Obj09A_VisibleView 0 "UNKNOWN" 1 "CLASSIC" 2 "SIDE" 3 "CLASSIC_SIDE" 4 "SIDE_CLASSIC" ;
VAL_ 63 VFC_Obj09A_HeadOrientation 0 "N/A" 1 "Head front" 2 "Head left front" 3 "Head left" 4 "Head left back" 5 "Head back" 6 "Head right back" 7 "Head right" 8 "Head right front" 9 "Reserved09" 10 "Reserved10" 11 "Reserved11" 12 "Reserved12" 13 "Reserved13" 14 "Reserved14" 15 "Unknown" ;
VAL_ 63 VFC_Obj09A_ClassifiedView 0 "Unknown" 1 "Front" 2 "Rear" 3 "Left" 4 "Right" ;
VAL_ 64 VFC_Obj10A_ID 0 "INVALID" ;
VAL_ 64 VFC_Obj10A_Type 0 "NOTYPE" 1 "CAR" 2 "RESERVED02" 3 "TRUCK" 4 "RESERVED04" 5 "RESERVED05" 6 "MOTORCYCLIST" 7 "PEDESTRIAN" 8 "CYCLIST" 9 "BOLLARD" 10 "ROADPOST" 11 "ARROWPOST" 12 "RESERVED12" 13 "RESERVED13" 14 "RESERVED14" 15 "RESERVED15" ;
VAL_ 64 VFC_Obj10A_Measured 0 "Invalid" 1 "Measured" 2 "Predicted" 3 "Reserved3" ;
VAL_ 64 VFC_Obj10A_DirIndicator 0 "Unknown" 1 "No direction indicator" 2 "Left indicator" 3 "Right indicator" 4 "Warning Lights" ;
VAL_ 64 VFC_Obj10A_BrakeLight 0 "Unknown" 1 "No light detected" 2 "One light detected" 3 "Two lights detected" 4 "Three lights detected" 5 "Reserved5" 6 "Reserved6" 7 "Reserved7" ;
VAL_ 64 VFC_Obj10A_CompletelyInImg 0 "not completely measured" 1 "completely measured" ;
VAL_ 64 VFC_Obj10A_VisibleView 0 "UNKNOWN" 1 "CLASSIC" 2 "SIDE" 3 "CLASSIC_SIDE" 4 "SIDE_CLASSIC" ;
VAL_ 64 VFC_Obj10A_HeadOrientation 0 "N/A" 1 "Head front" 2 "Head left front" 3 "Head left" 4 "Head left back" 5 "Head back" 6 "Head right back" 7 "Head right" 8 "Head right front" 9 "Reserved09" 10 "Reserved10" 11 "Reserved11" 12 "Reserved12" 13 "Reserved13" 14 "Reserved14" 15 "Unknown" ;
VAL_ 64 VFC_Obj10A_ClassifiedView 0 "Unknown" 1 "Front" 2 "Rear" 3 "Left" 4 "Right" ;
VAL_ 65 VFC_Obj11A_ID 0 "INVALID" ;
VAL_ 65 VFC_Obj11A_Type 0 "NOTYPE" 1 "CAR" 2 "RESERVED02" 3 "TRUCK" 4 "RESERVED04" 5 "RESERVED05" 6 "MOTORCYCLIST" 7 "PEDESTRIAN" 8 "CYCLIST" 9 "BOLLARD" 10 "ROADPOST" 11 "ARROWPOST" 12 "RESERVED12" 13 "RESERVED13" 14 "RESERVED14" 15 "RESERVED15" ;
VAL_ 65 VFC_Obj11A_Measured 0 "Invalid" 1 "Measured" 2 "Predicted" 3 "Reserved3" ;
VAL_ 65 VFC_Obj11A_DirIndicator 0 "Unknown" 1 "No direction indicator" 2 "Left indicator" 3 "Right indicator" 4 "Warning Lights" ;
VAL_ 65 VFC_Obj11A_BrakeLight 0 "Unknown" 1 "No light detected" 2 "One light detected" 3 "Two lights detected" 4 "Three lights detected" 5 "Reserved5" 6 "Reserved6" 7 "Reserved7" ;
VAL_ 65 VFC_Obj11A_CompletelyInImg 0 "not completely measured" 1 "completely measured" ;
VAL_ 65 VFC_Obj11A_VisibleView 0 "UNKNOWN" 1 "CLASSIC" 2 "SIDE" 3 "CLASSIC_SIDE" 4 "SIDE_CLASSIC" ;
VAL_ 65 VFC_Obj11A_HeadOrientation 0 "N/A" 1 "Head front" 2 "Head left front" 3 "Head left" 4 "Head left back" 5 "Head back" 6 "Head right back" 7 "Head right" 8 "Head right front" 9 "Reserved09" 10 "Reserved10" 11 "Reserved11" 12 "Reserved12" 13 "Reserved13" 14 "Reserved14" 15 "Unknown" ;
VAL_ 65 VFC_Obj11A_ClassifiedView 0 "Unknown" 1 "Front" 2 "Rear" 3 "Left" 4 "Right" ;
VAL_ 66 VFC_Obj12A_ID 0 "INVALID" ;
VAL_ 66 VFC_Obj12A_Type 0 "NOTYPE" 1 "CAR" 2 "RESERVED02" 3 "TRUCK" 4 "RESERVED04" 5 "RESERVED05" 6 "MOTORCYCLIST" 7 "PEDESTRIAN" 8 "CYCLIST" 9 "BOLLARD" 10 "ROADPOST" 11 "ARROWPOST" 12 "RESERVED12" 13 "RESERVED13" 14 "RESERVED14" 15 "RESERVED15" ;
VAL_ 66 VFC_Obj12A_Measured 0 "Invalid" 1 "Measured" 2 "Predicted" 3 "Reserved3" ;
VAL_ 66 VFC_Obj12A_DirIndicator 0 "Unknown" 1 "No direction indicator" 2 "Left indicator" 3 "Right indicator" 4 "Warning Lights" ;
VAL_ 66 VFC_Obj12A_BrakeLight 0 "Unknown" 1 "No light detected" 2 "One light detected" 3 "Two lights detected" 4 "Three lights detected" 5 "Reserved5" 6 "Reserved6" 7 "Reserved7" ;
VAL_ 66 VFC_Obj12A_CompletelyInImg 0 "not completely measured" 1 "completely measured" ;
VAL_ 66 VFC_Obj12A_VisibleView 0 "UNKNOWN" 1 "CLASSIC" 2 "SIDE" 3 "CLASSIC_SIDE" 4 "SIDE_CLASSIC" ;
VAL_ 66 VFC_Obj12A_HeadOrientation 0 "N/A" 1 "Head front" 2 "Head left front" 3 "Head left" 4 "Head left back" 5 "Head back" 6 "Head right back" 7 "Head right" 8 "Head right front" 9 "Reserved09" 10 "Reserved10" 11 "Reserved11" 12 "Reserved12" 13 "Reserved13" 14 "Reserved14" 15 "Unknown" ;
VAL_ 66 VFC_Obj12A_ClassifiedView 0 "Unknown" 1 "Front" 2 "Rear" 3 "Left" 4 "Right" ;
SIG_GROUP_ 16 SG_VFC_AEB_Request 1 : VFC_AEB_CRC VFC_AEB_AC VFC_AEB_FPC VFC_AEB_CU VFC_AEB_VRU VFC_AEB_VRUTA VFC_AEB_LTA VFC_Ax_CommandValue VFC_AEB_ObjID VFC_AEB_DummyForFuture;
SIG_GROUP_ 19 SG_RFL_AEB_Request 1 : RFL_AEB_CRC RFL_AEB_AC RFL_AEB_FPC RFL_AEB_CU RFL_AEB_VRU RFL_AEB_VRUTA RFL_AEB_LTA RFL_Ax_CommandValue RFL_AEB_ObjID RFL_AEB_DummyForFuture;
SIG_GROUP_ 20 SG_RFR_AEB_Request 1 : RFR_AEB_CRC RFR_AEB_AC RFR_AEB_FPC RFR_AEB_CU RFR_AEB_VRU RFR_AEB_VRUTA RFR_AEB_LTA RFR_Ax_CommandValue RFR_AEB_ObjID RFR_AEB_DummyForFuture;
SIG_GROUP_ 32 SG_VFC_GlobalHdr 1 : VFC_GlobalHdr_CRC VFC_GlobalHdr_AliveCtr VFC_GlobalHdr_ProtocolVersion VFC_GlobalHdr_TrafficFlowType VFC_GlobalHdr_TimeStampStatus VFC_GlobalHdr_TimeStamp VFC_GlobalHdr_SensorState VFC_GlobalHdr_DsmState VFC_GlobalHdr_CalibState VFC_GlobalHdr_StmState VFC_GlobalHdr_RollerBenchState VFC_GlobalHdr_MountPosX VFC_GlobalHdr_MountPosY VFC_GlobalHdr_MountPosZ VFC_GlobalHdr_CalibYawAngle VFC_GlobalHdr_CalibPitchAngle VFC_GlobalHdr_CalibRollAngle VFC_GlobalHdr_SwVersion VFC_GlobalHdr_FrameNumber;
SIG_GROUP_ 52 SG_VFC_ObjectHdr 1 : VFC_ObjHdr_CRC VFC_ObjHdr_AliveCtr VFC_ObjHdr_ProtBlockCtr VFC_ObjHdr_ProtObjCount VFC_ObjHdr_State VFC_ObjHdr_TimeStampStatus VFC_ObjHdr_TimeStamp VFC_ObjHdr_Principal_Point_U VFC_ObjHdr_Principal_Point_V VFC_ObjHdr_Focal_Length_X VFC_ObjHdr_Focal_Length_Y;
SIG_GROUP_ 54 SG_VFC_Object00A 1 : VFC_Obj00A_CRC VFC_Obj00A_AliveCtr VFC_Obj00A_ProtBlockCtr VFC_Obj00A_ID VFC_Obj00A_AxStdDev VFC_Obj00A_Dx VFC_Obj00A_Type VFC_Obj00A_Dy VFC_Obj00A_Measured VFC_Obj00A_Vx VFC_Obj00A_MeasSource VFC_Obj00A_Vy VFC_Obj00A_DirIndicator VFC_Obj00A_BrakeLight VFC_Obj00A_Ax VFC_Obj00A_CompletelyInImg VFC_Obj00A_ProbExist VFC_Obj00A_Ay VFC_Obj00A_AyStdDev VFC_Obj00A_DxStdDev VFC_Obj00A_ProbMovingLat VFC_Obj00A_DyStdDev VFC_Obj00A_ProbMovingLong VFC_Obj00A_VxStdDev VFC_Obj00A_HeadingAngleStdDev VFC_Obj00A_VyStdDev VFC_Obj00A_HeightStdDev VFC_Obj00A_Height VFC_Obj00A_Length VFC_Obj00A_HeadingAngle VFC_Obj00A_NormAx VFC_Obj00A_NormVyEdgeLeftStdDev VFC_Obj00A_NormVyEdgeLeft VFC_Obj00A_EdgeBottom VFC_Obj00A_NormVyEdgeRight VFC_Obj00A_Width VFC_Obj00A_NormVx VFC_Obj00A_NormVyEdgeRightStdDev VFC_Obj00A_NormAxStdDev VFC_Obj00A_ScaleChange VFC_Obj00A_ScaleChngStdDev VFC_Obj00A_Reliability VFC_Obj00A_NormVxStdDev VFC_Obj00A_TypeProb VFC_Obj00A_LengthStdDev VFC_Obj00A_WidthStdDev VFC_Obj00A_EdgeMid VFC_Obj00A_EdgeLeft VFC_Obj00A_EdgeRight VFC_Obj00A_VisibleView VFC_Obj00A_EdgeLeftStdDev VFC_Obj00A_EdgeTop VFC_Obj00A_HeadOrientation VFC_Obj00A_EdgeMidStdDev VFC_Obj00A_EdgeRightStdDev VFC_Obj00A_EdgeTopStdDev VFC_Obj00A_EdgeBottomStdDev VFC_Obj00A_ClassifiedView;
SIG_GROUP_ 55 SG_VFC_Object01A 1 : VFC_Obj01A_CRC VFC_Obj01A_AliveCtr VFC_Obj01A_ProtBlockCtr VFC_Obj01A_ID VFC_Obj01A_AxStdDev VFC_Obj01A_Dx VFC_Obj01A_Type VFC_Obj01A_Dy VFC_Obj01A_Measured VFC_Obj01A_Vx VFC_Obj01A_MeasSource VFC_Obj01A_Vy VFC_Obj01A_DirIndicator VFC_Obj01A_BrakeLight VFC_Obj01A_Ax VFC_Obj01A_CompletelyInImg VFC_Obj01A_ProbExist VFC_Obj01A_Ay VFC_Obj01A_AyStdDev VFC_Obj01A_DxStdDev VFC_Obj01A_ProbMovingLat VFC_Obj01A_DyStdDev VFC_Obj01A_ProbMovingLong VFC_Obj01A_VxStdDev VFC_Obj01A_HeadingAngleStdDev VFC_Obj01A_VyStdDev VFC_Obj01A_HeightStdDev VFC_Obj01A_Height VFC_Obj01A_Length VFC_Obj01A_HeadingAngle VFC_Obj01A_NormAx VFC_Obj01A_NormVyEdgeLeftStdDev VFC_Obj01A_NormVyEdgeLeft VFC_Obj01A_EdgeBottom VFC_Obj01A_NormVyEdgeRight VFC_Obj01A_Width VFC_Obj01A_NormVx VFC_Obj01A_NormVyEdgeRightStdDev VFC_Obj01A_NormAxStdDev VFC_Obj01A_ScaleChange VFC_Obj01A_ScaleChngStdDev VFC_Obj01A_Reliability VFC_Obj01A_NormVxStdDev VFC_Obj01A_TypeProb VFC_Obj01A_LengthStdDev VFC_Obj01A_WidthStdDev VFC_Obj01A_EdgeMid VFC_Obj01A_EdgeLeft VFC_Obj01A_EdgeRight VFC_Obj01A_VisibleView VFC_Obj01A_EdgeLeftStdDev VFC_Obj01A_EdgeTop VFC_Obj01A_HeadOrientation VFC_Obj01A_EdgeMidStdDev VFC_Obj01A_EdgeRightStdDev VFC_Obj01A_EdgeTopStdDev VFC_Obj01A_EdgeBottomStdDev VFC_Obj01A_ClassifiedView;
SIG_GROUP_ 56 SG_VFC_Object02A 1 : VFC_Obj02A_CRC VFC_Obj02A_AliveCtr VFC_Obj02A_ProtBlockCtr VFC_Obj02A_ID VFC_Obj02A_AxStdDev VFC_Obj02A_Dx VFC_Obj02A_Type VFC_Obj02A_Dy VFC_Obj02A_Measured VFC_Obj02A_Vx VFC_Obj02A_MeasSource VFC_Obj02A_Vy VFC_Obj02A_DirIndicator VFC_Obj02A_BrakeLight VFC_Obj02A_Ax VFC_Obj02A_CompletelyInImg VFC_Obj02A_ProbExist VFC_Obj02A_Ay VFC_Obj02A_AyStdDev VFC_Obj02A_DxStdDev VFC_Obj02A_ProbMovingLat VFC_Obj02A_DyStdDev VFC_Obj02A_ProbMovingLong VFC_Obj02A_VxStdDev VFC_Obj02A_HeadingAngleStdDev VFC_Obj02A_VyStdDev VFC_Obj02A_HeightStdDev VFC_Obj02A_Height VFC_Obj02A_Length VFC_Obj02A_HeadingAngle VFC_Obj02A_NormAx VFC_Obj02A_NormVyEdgeLeftStdDev VFC_Obj02A_NormVyEdgeLeft VFC_Obj02A_EdgeBottom VFC_Obj02A_NormVyEdgeRight VFC_Obj02A_Width VFC_Obj02A_NormVx VFC_Obj02A_NormVyEdgeRightStdDev VFC_Obj02A_NormAxStdDev VFC_Obj02A_ScaleChange VFC_Obj02A_ScaleChngStdDev VFC_Obj02A_Reliability VFC_Obj02A_NormVxStdDev VFC_Obj02A_TypeProb VFC_Obj02A_LengthStdDev VFC_Obj02A_WidthStdDev VFC_Obj02A_EdgeMid VFC_Obj02A_EdgeLeft VFC_Obj02A_EdgeRight VFC_Obj02A_VisibleView VFC_Obj02A_EdgeLeftStdDev VFC_Obj02A_EdgeTop VFC_Obj02A_HeadOrientation VFC_Obj02A_EdgeMidStdDev VFC_Obj02A_EdgeRightStdDev VFC_Obj02A_EdgeTopStdDev VFC_Obj02A_EdgeBottomStdDev VFC_Obj02A_ClassifiedView;
SIG_GROUP_ 57 SG_VFC_Object03A 1 : VFC_Obj03A_CRC VFC_Obj03A_AliveCtr VFC_Obj03A_ProtBlockCtr VFC_Obj03A_ID VFC_Obj03A_AxStdDev VFC_Obj03A_Dx VFC_Obj03A_Type VFC_Obj03A_Dy VFC_Obj03A_Measured VFC_Obj03A_Vx VFC_Obj03A_MeasSource VFC_Obj03A_Vy VFC_Obj03A_DirIndicator VFC_Obj03A_BrakeLight VFC_Obj03A_Ax VFC_Obj03A_CompletelyInImg VFC_Obj03A_ProbExist VFC_Obj03A_Ay VFC_Obj03A_AyStdDev VFC_Obj03A_DxStdDev VFC_Obj03A_ProbMovingLat VFC_Obj03A_DyStdDev VFC_Obj03A_ProbMovingLong VFC_Obj03A_VxStdDev VFC_Obj03A_HeadingAngleStdDev VFC_Obj03A_VyStdDev VFC_Obj03A_HeightStdDev VFC_Obj03A_Height VFC_Obj03A_Length VFC_Obj03A_HeadingAngle VFC_Obj03A_NormAx VFC_Obj03A_NormVyEdgeLeftStdDev VFC_Obj03A_NormVyEdgeLeft VFC_Obj03A_EdgeBottom VFC_Obj03A_NormVyEdgeRight VFC_Obj03A_Width VFC_Obj03A_NormVx VFC_Obj03A_NormVyEdgeRightStdDev VFC_Obj03A_NormAxStdDev VFC_Obj03A_ScaleChange VFC_Obj03A_ScaleChngStdDev VFC_Obj03A_Reliability VFC_Obj03A_NormVxStdDev VFC_Obj03A_TypeProb VFC_Obj03A_LengthStdDev VFC_Obj03A_WidthStdDev VFC_Obj03A_EdgeMid VFC_Obj03A_EdgeLeft VFC_Obj03A_EdgeRight VFC_Obj03A_VisibleView VFC_Obj03A_EdgeLeftStdDev VFC_Obj03A_EdgeTop VFC_Obj03A_HeadOrientation VFC_Obj03A_EdgeMidStdDev VFC_Obj03A_EdgeRightStdDev VFC_Obj03A_EdgeTopStdDev VFC_Obj03A_EdgeBottomStdDev VFC_Obj03A_ClassifiedView;
SIG_GROUP_ 58 SG_VFC_Object04A 1 : VFC_Obj04A_CRC VFC_Obj04A_AliveCtr VFC_Obj04A_ProtBlockCtr VFC_Obj04A_ID VFC_Obj04A_AxStdDev VFC_Obj04A_Dx VFC_Obj04A_Type VFC_Obj04A_Dy VFC_Obj04A_Measured VFC_Obj04A_Vx VFC_Obj04A_MeasSource VFC_Obj04A_Vy VFC_Obj04A_DirIndicator VFC_Obj04A_BrakeLight VFC_Obj04A_Ax VFC_Obj04A_CompletelyInImg VFC_Obj04A_ProbExist VFC_Obj04A_Ay VFC_Obj04A_AyStdDev VFC_Obj04A_DxStdDev VFC_Obj04A_ProbMovingLat VFC_Obj04A_DyStdDev VFC_Obj04A_ProbMovingLong VFC_Obj04A_VxStdDev VFC_Obj04A_HeadingAngleStdDev VFC_Obj04A_VyStdDev VFC_Obj04A_HeightStdDev VFC_Obj04A_Height VFC_Obj04A_Length VFC_Obj04A_HeadingAngle VFC_Obj04A_NormAx VFC_Obj04A_NormVyEdgeLeftStdDev VFC_Obj04A_NormVyEdgeLeft VFC_Obj04A_EdgeBottom VFC_Obj04A_NormVyEdgeRight VFC_Obj04A_Width VFC_Obj04A_NormVx VFC_Obj04A_NormVyEdgeRightStdDev VFC_Obj04A_NormAxStdDev VFC_Obj04A_ScaleChange VFC_Obj04A_ScaleChngStdDev VFC_Obj04A_Reliability VFC_Obj04A_NormVxStdDev VFC_Obj04A_TypeProb VFC_Obj04A_LengthStdDev VFC_Obj04A_WidthStdDev VFC_Obj04A_EdgeMid VFC_Obj04A_EdgeLeft VFC_Obj04A_EdgeRight VFC_Obj04A_VisibleView VFC_Obj04A_EdgeLeftStdDev VFC_Obj04A_EdgeTop VFC_Obj04A_HeadOrientation VFC_Obj04A_EdgeMidStdDev VFC_Obj04A_EdgeRightStdDev VFC_Obj04A_EdgeTopStdDev VFC_Obj04A_EdgeBottomStdDev VFC_Obj04A_ClassifiedView;
SIG_GROUP_ 59 SG_VFC_Object05A 1 : VFC_Obj05A_CRC VFC_Obj05A_AliveCtr VFC_Obj05A_ProtBlockCtr VFC_Obj05A_ID VFC_Obj05A_AxStdDev VFC_Obj05A_Dx VFC_Obj05A_Type VFC_Obj05A_Dy VFC_Obj05A_Measured VFC_Obj05A_Vx VFC_Obj05A_MeasSource VFC_Obj05A_Vy VFC_Obj05A_DirIndicator VFC_Obj05A_BrakeLight VFC_Obj05A_Ax VFC_Obj05A_CompletelyInImg VFC_Obj05A_ProbExist VFC_Obj05A_Ay VFC_Obj05A_AyStdDev VFC_Obj05A_DxStdDev VFC_Obj05A_ProbMovingLat VFC_Obj05A_DyStdDev VFC_Obj05A_ProbMovingLong VFC_Obj05A_VxStdDev VFC_Obj05A_HeadingAngleStdDev VFC_Obj05A_VyStdDev VFC_Obj05A_HeightStdDev VFC_Obj05A_Height VFC_Obj05A_Length VFC_Obj05A_HeadingAngle VFC_Obj05A_NormAx VFC_Obj05A_NormVyEdgeLeftStdDev VFC_Obj05A_NormVyEdgeLeft VFC_Obj05A_EdgeBottom VFC_Obj05A_NormVyEdgeRight VFC_Obj05A_Width VFC_Obj05A_NormVx VFC_Obj05A_NormVyEdgeRightStdDev VFC_Obj05A_NormAxStdDev VFC_Obj05A_ScaleChange VFC_Obj05A_ScaleChngStdDev VFC_Obj05A_Reliability VFC_Obj05A_NormVxStdDev VFC_Obj05A_TypeProb VFC_Obj05A_LengthStdDev VFC_Obj05A_WidthStdDev VFC_Obj05A_EdgeMid VFC_Obj05A_EdgeLeft VFC_Obj05A_EdgeRight VFC_Obj05A_VisibleView VFC_Obj05A_EdgeLeftStdDev VFC_Obj05A_EdgeTop VFC_Obj05A_HeadOrientation VFC_Obj05A_EdgeMidStdDev VFC_Obj05A_EdgeRightStdDev VFC_Obj05A_EdgeTopStdDev VFC_Obj05A_EdgeBottomStdDev VFC_Obj05A_ClassifiedView;
SIG_GROUP_ 60 SG_VFC_Object06A 1 : VFC_Obj06A_CRC VFC_Obj06A_AliveCtr VFC_Obj06A_ProtBlockCtr VFC_Obj06A_ID VFC_Obj06A_AxStdDev VFC_Obj06A_Dx VFC_Obj06A_Type VFC_Obj06A_Dy VFC_Obj06A_Measured VFC_Obj06A_Vx VFC_Obj06A_MeasSource VFC_Obj06A_Vy VFC_Obj06A_DirIndicator VFC_Obj06A_BrakeLight VFC_Obj06A_Ax VFC_Obj06A_CompletelyInImg VFC_Obj06A_ProbExist VFC_Obj06A_Ay VFC_Obj06A_AyStdDev VFC_Obj06A_DxStdDev VFC_Obj06A_ProbMovingLat VFC_Obj06A_DyStdDev VFC_Obj06A_ProbMovingLong VFC_Obj06A_VxStdDev VFC_Obj06A_HeadingAngleStdDev VFC_Obj06A_VyStdDev VFC_Obj06A_HeightStdDev VFC_Obj06A_Height VFC_Obj06A_Length VFC_Obj06A_HeadingAngle VFC_Obj06A_NormAx VFC_Obj06A_NormVyEdgeLeftStdDev VFC_Obj06A_NormVyEdgeLeft VFC_Obj06A_EdgeBottom VFC_Obj06A_NormVyEdgeRight VFC_Obj06A_Width VFC_Obj06A_NormVx VFC_Obj06A_NormVyEdgeRightStdDev VFC_Obj06A_NormAxStdDev VFC_Obj06A_ScaleChange VFC_Obj06A_ScaleChngStdDev VFC_Obj06A_Reliability VFC_Obj06A_NormVxStdDev VFC_Obj06A_TypeProb VFC_Obj06A_LengthStdDev VFC_Obj06A_WidthStdDev VFC_Obj06A_EdgeMid VFC_Obj06A_EdgeLeft VFC_Obj06A_EdgeRight VFC_Obj06A_VisibleView VFC_Obj06A_EdgeLeftStdDev VFC_Obj06A_EdgeTop VFC_Obj06A_HeadOrientation VFC_Obj06A_EdgeMidStdDev VFC_Obj06A_EdgeRightStdDev VFC_Obj06A_EdgeTopStdDev VFC_Obj06A_EdgeBottomStdDev VFC_Obj06A_ClassifiedView;
SIG_GROUP_ 61 SG_VFC_Object07A 1 : VFC_Obj07A_CRC VFC_Obj07A_AliveCtr VFC_Obj07A_ProtBlockCtr VFC_Obj07A_ID VFC_Obj07A_AxStdDev VFC_Obj07A_Dx VFC_Obj07A_Type VFC_Obj07A_Dy VFC_Obj07A_Measured VFC_Obj07A_Vx VFC_Obj07A_MeasSource VFC_Obj07A_Vy VFC_Obj07A_DirIndicator VFC_Obj07A_BrakeLight VFC_Obj07A_Ax VFC_Obj07A_CompletelyInImg VFC_Obj07A_ProbExist VFC_Obj07A_Ay VFC_Obj07A_AyStdDev VFC_Obj07A_DxStdDev VFC_Obj07A_ProbMovingLat VFC_Obj07A_DyStdDev VFC_Obj07A_ProbMovingLong VFC_Obj07A_VxStdDev VFC_Obj07A_HeadingAngleStdDev VFC_Obj07A_VyStdDev VFC_Obj07A_HeightStdDev VFC_Obj07A_Height VFC_Obj07A_Length VFC_Obj07A_HeadingAngle VFC_Obj07A_NormAx VFC_Obj07A_NormVyEdgeLeftStdDev VFC_Obj07A_NormVyEdgeLeft VFC_Obj07A_EdgeBottom VFC_Obj07A_NormVyEdgeRight VFC_Obj07A_Width VFC_Obj07A_NormVx VFC_Obj07A_NormVyEdgeRightStdDev VFC_Obj07A_NormAxStdDev VFC_Obj07A_ScaleChange VFC_Obj07A_ScaleChngStdDev VFC_Obj07A_Reliability VFC_Obj07A_NormVxStdDev VFC_Obj07A_TypeProb VFC_Obj07A_LengthStdDev VFC_Obj07A_WidthStdDev VFC_Obj07A_EdgeMid VFC_Obj07A_EdgeLeft VFC_Obj07A_EdgeRight VFC_Obj07A_VisibleView VFC_Obj07A_EdgeLeftStdDev VFC_Obj07A_EdgeTop VFC_Obj07A_HeadOrientation VFC_Obj07A_EdgeMidStdDev VFC_Obj07A_EdgeRightStdDev VFC_Obj07A_EdgeTopStdDev VFC_Obj07A_EdgeBottomStdDev VFC_Obj07A_ClassifiedView;
SIG_GROUP_ 62 SG_VFC_Object08A 1 : VFC_Obj08A_CRC VFC_Obj08A_AliveCtr VFC_Obj08A_ProtBlockCtr VFC_Obj08A_ID VFC_Obj08A_AxStdDev VFC_Obj08A_Dx VFC_Obj08A_Type VFC_Obj08A_Dy VFC_Obj08A_Measured VFC_Obj08A_Vx VFC_Obj08A_MeasSource VFC_Obj08A_Vy VFC_Obj08A_DirIndicator VFC_Obj08A_BrakeLight VFC_Obj08A_Ax VFC_Obj08A_CompletelyInImg VFC_Obj08A_ProbExist VFC_Obj08A_Ay VFC_Obj08A_AyStdDev VFC_Obj08A_DxStdDev VFC_Obj08A_ProbMovingLat VFC_Obj08A_DyStdDev VFC_Obj08A_ProbMovingLong VFC_Obj08A_VxStdDev VFC_Obj08A_HeadingAngleStdDev VFC_Obj08A_VyStdDev VFC_Obj08A_HeightStdDev VFC_Obj08A_Height VFC_Obj08A_Length VFC_Obj08A_HeadingAngle VFC_Obj08A_NormAx VFC_Obj08A_NormVyEdgeLeftStdDev VFC_Obj08A_NormVyEdgeLeft VFC_Obj08A_EdgeBottom VFC_Obj08A_NormVyEdgeRight VFC_Obj08A_Width VFC_Obj08A_NormVx VFC_Obj08A_NormVyEdgeRightStdDev VFC_Obj08A_NormAxStdDev VFC_Obj08A_ScaleChange VFC_Obj08A_ScaleChngStdDev VFC_Obj08A_Reliability VFC_Obj08A_NormVxStdDev VFC_Obj08A_TypeProb VFC_Obj08A_LengthStdDev VFC_Obj08A_WidthStdDev VFC_Obj08A_EdgeMid VFC_Obj08A_EdgeLeft VFC_Obj08A_EdgeRight VFC_Obj08A_VisibleView VFC_Obj08A_EdgeLeftStdDev VFC_Obj08A_EdgeTop VFC_Obj08A_HeadOrientation VFC_Obj08A_EdgeMidStdDev VFC_Obj08A_EdgeRightStdDev VFC_Obj08A_EdgeTopStdDev VFC_Obj08A_EdgeBottomStdDev VFC_Obj08A_ClassifiedView;
SIG_GROUP_ 63 SG_VFC_Object09A 1 : VFC_Obj09A_CRC VFC_Obj09A_AliveCtr VFC_Obj09A_ProtBlockCtr VFC_Obj09A_ID VFC_Obj09A_AxStdDev VFC_Obj09A_Dx VFC_Obj09A_Type VFC_Obj09A_Dy VFC_Obj09A_Measured VFC_Obj09A_Vx VFC_Obj09A_MeasSource VFC_Obj09A_Vy VFC_Obj09A_DirIndicator VFC_Obj09A_BrakeLight VFC_Obj09A_Ax VFC_Obj09A_CompletelyInImg VFC_Obj09A_ProbExist VFC_Obj09A_Ay VFC_Obj09A_AyStdDev VFC_Obj09A_DxStdDev VFC_Obj09A_ProbMovingLat VFC_Obj09A_DyStdDev VFC_Obj09A_ProbMovingLong VFC_Obj09A_VxStdDev VFC_Obj09A_HeadingAngleStdDev VFC_Obj09A_VyStdDev VFC_Obj09A_HeightStdDev VFC_Obj09A_Height VFC_Obj09A_Length VFC_Obj09A_HeadingAngle VFC_Obj09A_NormAx VFC_Obj09A_NormVyEdgeLeftStdDev VFC_Obj09A_NormVyEdgeLeft VFC_Obj09A_EdgeBottom VFC_Obj09A_NormVyEdgeRight VFC_Obj09A_Width VFC_Obj09A_NormVx VFC_Obj09A_NormVyEdgeRightStdDev VFC_Obj09A_NormAxStdDev VFC_Obj09A_ScaleChange VFC_Obj09A_ScaleChngStdDev VFC_Obj09A_Reliability VFC_Obj09A_NormVxStdDev VFC_Obj09A_TypeProb VFC_Obj09A_LengthStdDev VFC_Obj09A_WidthStdDev VFC_Obj09A_EdgeMid VFC_Obj09A_EdgeLeft VFC_Obj09A_EdgeRight VFC_Obj09A_VisibleView VFC_Obj09A_EdgeLeftStdDev VFC_Obj09A_EdgeTop VFC_Obj09A_HeadOrientation VFC_Obj09A_EdgeMidStdDev VFC_Obj09A_EdgeRightStdDev VFC_Obj09A_EdgeTopStdDev VFC_Obj09A_EdgeBottomStdDev VFC_Obj09A_ClassifiedView;
SIG_GROUP_ 64 SG_VFC_Object10A 1 : VFC_Obj10A_CRC VFC_Obj10A_AliveCtr VFC_Obj10A_ProtBlockCtr VFC_Obj10A_ID VFC_Obj10A_AxStdDev VFC_Obj10A_Dx VFC_Obj10A_Type VFC_Obj10A_Dy VFC_Obj10A_Measured VFC_Obj10A_Vx VFC_Obj10A_MeasSource VFC_Obj10A_Vy VFC_Obj10A_DirIndicator VFC_Obj10A_BrakeLight VFC_Obj10A_Ax VFC_Obj10A_CompletelyInImg VFC_Obj10A_ProbExist VFC_Obj10A_Ay VFC_Obj10A_AyStdDev VFC_Obj10A_DxStdDev VFC_Obj10A_ProbMovingLat VFC_Obj10A_DyStdDev VFC_Obj10A_ProbMovingLong VFC_Obj10A_VxStdDev VFC_Obj10A_HeadingAngleStdDev VFC_Obj10A_VyStdDev VFC_Obj10A_HeightStdDev VFC_Obj10A_Height VFC_Obj10A_Length VFC_Obj10A_HeadingAngle VFC_Obj10A_NormAx VFC_Obj10A_NormVyEdgeLeftStdDev VFC_Obj10A_NormVyEdgeLeft VFC_Obj10A_EdgeBottom VFC_Obj10A_NormVyEdgeRight VFC_Obj10A_Width VFC_Obj10A_NormVx VFC_Obj10A_NormVyEdgeRightStdDev VFC_Obj10A_NormAxStdDev VFC_Obj10A_ScaleChange VFC_Obj10A_ScaleChngStdDev VFC_Obj10A_Reliability VFC_Obj10A_NormVxStdDev VFC_Obj10A_TypeProb VFC_Obj10A_LengthStdDev VFC_Obj10A_WidthStdDev VFC_Obj10A_EdgeMid VFC_Obj10A_EdgeLeft VFC_Obj10A_EdgeRight VFC_Obj10A_VisibleView VFC_Obj10A_EdgeLeftStdDev VFC_Obj10A_EdgeTop VFC_Obj10A_HeadOrientation VFC_Obj10A_EdgeMidStdDev VFC_Obj10A_EdgeRightStdDev VFC_Obj10A_EdgeTopStdDev VFC_Obj10A_EdgeBottomStdDev VFC_Obj10A_ClassifiedView;
SIG_GROUP_ 65 SG_VFC_Object11A 1 : VFC_Obj11A_CRC VFC_Obj11A_AliveCtr VFC_Obj11A_ProtBlockCtr VFC_Obj11A_ID VFC_Obj11A_AxStdDev VFC_Obj11A_Dx VFC_Obj11A_Type VFC_Obj11A_Dy VFC_Obj11A_Measured VFC_Obj11A_Vx VFC_Obj11A_MeasSource VFC_Obj11A_Vy VFC_Obj11A_DirIndicator VFC_Obj11A_BrakeLight VFC_Obj11A_Ax VFC_Obj11A_CompletelyInImg VFC_Obj11A_ProbExist VFC_Obj11A_Ay VFC_Obj11A_AyStdDev VFC_Obj11A_DxStdDev VFC_Obj11A_ProbMovingLat VFC_Obj11A_DyStdDev VFC_Obj11A_ProbMovingLong VFC_Obj11A_VxStdDev VFC_Obj11A_HeadingAngleStdDev VFC_Obj11A_VyStdDev VFC_Obj11A_HeightStdDev VFC_Obj11A_Height VFC_Obj11A_Length VFC_Obj11A_HeadingAngle VFC_Obj11A_NormAx VFC_Obj11A_NormVyEdgeLeftStdDev VFC_Obj11A_NormVyEdgeLeft VFC_Obj11A_EdgeBottom VFC_Obj11A_NormVyEdgeRight VFC_Obj11A_Width VFC_Obj11A_NormVx VFC_Obj11A_NormVyEdgeRightStdDev VFC_Obj11A_NormAxStdDev VFC_Obj11A_ScaleChange VFC_Obj11A_ScaleChngStdDev VFC_Obj11A_Reliability VFC_Obj11A_NormVxStdDev VFC_Obj11A_TypeProb VFC_Obj11A_LengthStdDev VFC_Obj11A_WidthStdDev VFC_Obj11A_EdgeMid VFC_Obj11A_EdgeLeft VFC_Obj11A_EdgeRight VFC_Obj11A_VisibleView VFC_Obj11A_EdgeLeftStdDev VFC_Obj11A_EdgeTop VFC_Obj11A_HeadOrientation VFC_Obj11A_EdgeMidStdDev VFC_Obj11A_EdgeRightStdDev VFC_Obj11A_EdgeTopStdDev VFC_Obj11A_EdgeBottomStdDev VFC_Obj11A_ClassifiedView;
SIG_GROUP_ 66 SG_VFC_Object12A 1 : VFC_Obj12A_CRC VFC_Obj12A_AliveCtr VFC_Obj12A_ProtBlockCtr VFC_Obj12A_ID VFC_Obj12A_AxStdDev VFC_Obj12A_Dx VFC_Obj12A_Type VFC_Obj12A_Dy VFC_Obj12A_Measured VFC_Obj12A_Vx VFC_Obj12A_MeasSource VFC_Obj12A_Vy VFC_Obj12A_DirIndicator VFC_Obj12A_BrakeLight VFC_Obj12A_Ax VFC_Obj12A_CompletelyInImg VFC_Obj12A_ProbExist VFC_Obj12A_Ay VFC_Obj12A_AyStdDev VFC_Obj12A_DxStdDev VFC_Obj12A_ProbMovingLat VFC_Obj12A_DyStdDev VFC_Obj12A_ProbMovingLong VFC_Obj12A_VxStdDev VFC_Obj12A_HeadingAngleStdDev VFC_Obj12A_VyStdDev VFC_Obj12A_HeightStdDev VFC_Obj12A_Height VFC_Obj12A_Length VFC_Obj12A_HeadingAngle VFC_Obj12A_NormAx VFC_Obj12A_NormVyEdgeLeftStdDev VFC_Obj12A_NormVyEdgeLeft VFC_Obj12A_EdgeBottom VFC_Obj12A_NormVyEdgeRight VFC_Obj12A_Width VFC_Obj12A_NormVx VFC_Obj12A_NormVyEdgeRightStdDev VFC_Obj12A_NormAxStdDev VFC_Obj12A_ScaleChange VFC_Obj12A_ScaleChngStdDev VFC_Obj12A_Reliability VFC_Obj12A_NormVxStdDev VFC_Obj12A_TypeProb VFC_Obj12A_LengthStdDev VFC_Obj12A_WidthStdDev VFC_Obj12A_EdgeMid VFC_Obj12A_EdgeLeft VFC_Obj12A_EdgeRight VFC_Obj12A_VisibleView VFC_Obj12A_EdgeLeftStdDev VFC_Obj12A_EdgeTop VFC_Obj12A_HeadOrientation VFC_Obj12A_EdgeMidStdDev VFC_Obj12A_EdgeRightStdDev VFC_Obj12A_EdgeTopStdDev VFC_Obj12A_EdgeBottomStdDev VFC_Obj12A_ClassifiedView;
